VERSION ""

NS_ :

BS_:

BU_: Turbocharger OnBoardDataLogger OffBoardDiagnosticTool2 OffBoardDiagnosticTool1 FileServer ParkingBrakeController SeatControl2 FanDriveController SteeringColumnUnit CommunicationUnitRadio CommunicationUnitSatellite CommunicationUnitCellular PropulsionBatteryCharger ChassisController2 ChassisController1 EngineValveControl AuxiliaryHeater2 AuxiliaryHeater1 ClutchUnit RampControl InformationSystem1 SuspensionSystemController2 OilSensor VehicleDynamicStability ExhaustEmissionController TransmissionDisplay2 TransmissionDisplay1 ClimateControl2 WaterPumpController RearAxleSteeringController LightingOperatorControl SeatController1 IgnitionController2 IgnitionController1 TirePressureController CabController2 CabController1 PneumaticSystemController SuspensionSystemController1 HydraulicPumpController EnduranceBrakingSystem RetarderExhaustEngine2 OnBoardDiagnosticUnit HeadwayController RetarderExhaustEngine1 CabDisplay1 ManagementComputer VirtualTerminal OffVehicleGateway PowerTakeOffFront HitchControl AuxiliaryValveControl BodyController TractorTrailerBridge1 StarterSystem ElectricalSystem VehicleSecurity VehicleNavigation AerodynamicControl ElectricalChargingSystem ClimateControl1 TripRecorder InstrumentCluster SuspensionDriveAxle2 SuspensionDriveAxle1 SuspensionSteerAxle SteeringController FuelSystem CruiseControl RetarderDriveline RetarderEngine BrakesDriveAxle2 BrakesDriveAxle1 BrakesSystemController BrakesSteerAxle AxleDrive2 AxleDrive1 AxleSteering PowerTakeOff ShiftConsoleSecondary ShiftConsolePrimary Transmission2 Transmission1 Engine2 Engine1

BO_ 2628452094 FSClient: 9 Vector__XXX
 SG_ FSClientCommand M : 0|8@1+ (1,0) [0|255] "" Vector__XXX
 SG_ CM_VersionNumber m0 : 8|8@1+ (1,0) [0|255] "" Vector__XXX
 SG_ VS_ReportVolumeUsedByClient m2 : 8|1@1+ (1,0) [0|1] "" Vector__XXX
 SG_ VI_TAN m64 : 8|8@1+ (1,0) [0|255] "" Vector__XXX
 SG_ DF_TAN m49 : 8|8@1+ (1,0) [0|255] "" Vector__XXX
 SG_ MF_TAN m48 : 8|8@1+ (1,0) [0|255] "" Vector__XXX
 SG_ OF_TAN m32 : 8|8@1+ (1,0) [0|255] "" Vector__XXX
 SG_ SF_TAN m33 : 8|8@1+ (1,0) [0|255] "" Vector__XXX
 SG_ WF_TAN m35 : 8|8@1+ (1,0) [0|255] "" Vector__XXX
 SG_ CF_TAN m36 : 8|8@1+ (1,0) [0|255] "" Vector__XXX
 SG_ RF_TAN m34 : 8|8@1+ (1,0) [0|255] "" Vector__XXX
 SG_ GA_TAN m50 : 8|8@1+ (1,0) [0|255] "" Vector__XXX
 SG_ SA_TAN m51 : 8|8@1+ (1,0) [0|255] "" Vector__XXX
 SG_ FDT_TAN m52 : 8|8@1+ (1,0) [0|255] "" Vector__XXX
 SG_ GCD_TAN m16 : 8|8@1+ (1,0) [0|255] "" Vector__XXX
 SG_ CCD_TAN m17 : 8|8@1+ (1,0) [0|255] "" Vector__XXX
 SG_ VS_RequestVolumeToPrepareForRemo m2 : 9|1@1- (1,0) [0|1] "" Vector__XXX
 SG_ VS_VolumeName m2 : 16|16@1+ (1,0) [0|65535] "" Vector__XXX
 SG_ FDT_PathName m52 : 16|16@1+ (1,0) [0|65535] "" Vector__XXX
 SG_ GA_PathName m50 : 16|16@1+ (1,0) [0|65535] "" Vector__XXX
 SG_ DF_DeleteMode m49 : 16|1@1+ (1,0) [0|1] "" Vector__XXX
 SG_ MF_MoveModeCopy m48 : 16|1@1+ (1,0) [0|1] "" Vector__XXX
 SG_ CCD_PathName m17 : 16|16@1+ (1,0) [0|65535] "" Vector__XXX
 SG_ OF_FlagReadWrite m32 : 16|2@1+ (1,0) [0|3] "" Vector__XXX
 SG_ SF_Handle m33 : 16|8@1+ (1,0) [0|255] "" Vector__XXX
 SG_ RF_Handle m34 : 16|8@1+ (1,0) [0|255] "" Vector__XXX
 SG_ WF_Handle m35 : 16|8@1+ (1,0) [0|255] "" Vector__XXX
 SG_ CF_Handle m36 : 16|8@1+ (1,0) [0|255] "" Vector__XXX
 SG_ SET_ATTR_ReadOnly m51 : 16|2@1+ (1,0) [0|3] "" Vector__XXX
 SG_ VI_Flag_UsingSpaceSpecified m64 : 49|1@1+ (1,0) [0|1] "" Vector__XXX
 SG_ DF_DeleteModeForce m49 : 17|1@1+ (1,0) [0|1] "" Vector__XXX
 SG_ MF_MoveModeForce m48 : 17|1@1+ (1,0) [0|1] "" Vector__XXX
 SG_ DF_DeleteModeRecursive m49 : 18|1@1+ (1,0) [0|1] "" Vector__XXX
 SG_ MF_MoveModeRecursive m48 : 18|1@1+ (1,0) [0|1] "" Vector__XXX
 SG_ OF_FlagCreateNew m32 : 18|1@1+ (1,0) [0|1] "" Vector__XXX
 SG_ SET_ATTR_Hidden m51 : 18|2@1+ (1,0) [0|3] "" Vector__XXX
 SG_ OF_FlagAppend m32 : 19|1@1+ (1,0) [0|1] "" Vector__XXX
 SG_ OF_FlagExclusiveAccess m32 : 20|1@1+ (1,0) [0|1] "" Vector__XXX
 SG_ VI_Space m64 : 16|32@1+ (1,0) [0|4294967295] "" Vector__XXX
 SG_ SA_PathName m51 : 24|16@1+ (1,0) [0|65535] "" Vector__XXX
 SG_ DF_PathName m49 : 24|16@1+ (1,0) [0|65535] "" Vector__XXX
 SG_ WF_Count m35 : 24|16@1+ (1,0) [0|65535] "" Vector__XXX
 SG_ MF_SourcePathNameLength m48 : 24|16@1+ (1,0) [0|65535] "" Vector__XXX
 SG_ OF_PathName m32 : 24|16@1+ (1,0) [0|65535] "" Vector__XXX
 SG_ SF_PositionMode m33 : 24|8@1+ (1,0) [0|255] "" Vector__XXX
 SG_ RF_Count m34 : 24|16@1+ (1,0) [0|65535] "Bytes" Vector__XXX
 SG_ SF_Offset m33 : 32|32@1+ (1,0) [0|4294967295] "" Vector__XXX
 SG_ RF_ReportHiddenFiles m34 : 40|8@1+ (1,0) [0|255] "" Vector__XXX
 SG_ MF_DestinationPathNameLength m48 : 40|16@1+ (1,0) [0|65535] "" Vector__XXX
 SG_ VI_Flag_OverwriteExisting m64 : 48|1@1+ (1,0) [0|1] "" Vector__XXX
 SG_ VI_VolumeName m64 : 56|16@1+ (1,0) [0|65535] "" Vector__XXX

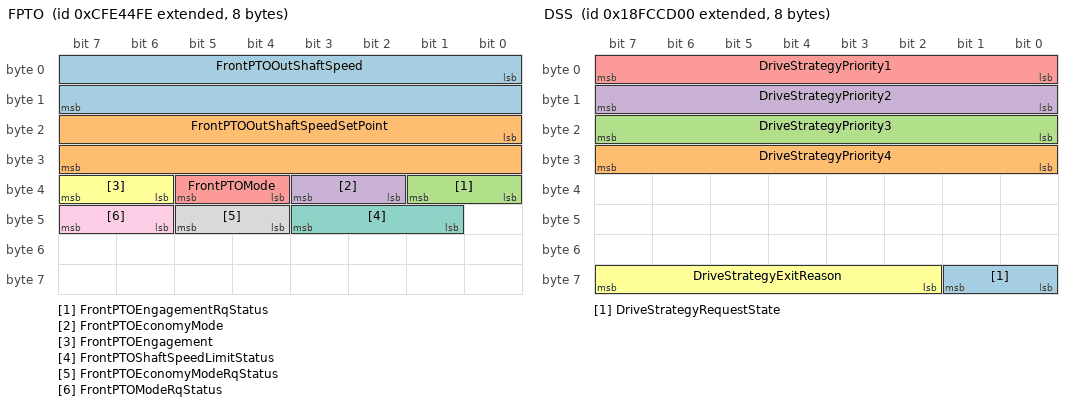
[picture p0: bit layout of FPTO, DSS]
BO_ 2365474046 FPTO: 8 Vector__XXX
 SG_ FrontPTOOutShaftSpeed : 0|16@1+ (0.125,0) [0|8031.88] "1/min" Vector__XXX
 SG_ FrontPTOOutShaftSpeedSetPoint : 16|16@1+ (0.125,0) [0|8031.88] "1/min" Vector__XXX
 SG_ FrontPTOEngagementRqStatus : 32|2@1+ (1,0) [0|3] "" Vector__XXX
 SG_ FrontPTOEconomyMode : 34|2@1+ (1,0) [0|3] "" Vector__XXX
 SG_ FrontPTOMode : 36|2@1+ (1,0) [0|3] "" Vector__XXX
 SG_ FrontPTOEngagement : 38|2@1+ (1,0) [0|3] "" Vector__XXX
 SG_ FrontPTOShaftSpeedLimitStatus : 41|3@1+ (1,0) [0|7] "" Vector__XXX
 SG_ FrontPTOEconomyModeRqStatus : 44|2@1+ (1,0) [0|3] "" Vector__XXX
 SG_ FrontPTOModeRqStatus : 46|2@1+ (1,0) [0|3] "" Vector__XXX

BO_ 2365474558 FHS: 8 Vector__XXX
 SG_ FrontHitchPosition : 0|8@1+ (0.4,0) [0|100] "%" Vector__XXX
 SG_ FrontHitchPositionLimitStatus : 11|3@1+ (1,0) [0|7] "" Vector__XXX
 SG_ FrontHitchInWorkIndication : 14|2@1+ (1,0) [0|3] "" Vector__XXX
 SG_ FrontNominalLowerLinkForce : 16|8@1+ (0.8,-100) [-100|100] "%" Vector__XXX
 SG_ FrontDraft : 24|16@1+ (10,-320000) [-320000|322550] "N" Vector__XXX

BO_ 2563243774 ETP_DT: 8 Vector__XXX
 SG_ SequenceNumber : 0|8@1+ (1,0) [0|255] "" Vector__XXX
 SG_ Byte1 : 8|8@1+ (1,0) [0|255] "" Vector__XXX
 SG_ Byte2 : 16|8@1+ (1,0) [0|255] "" Vector__XXX
 SG_ Byte3 : 24|8@1+ (1,0) [0|255] "" Vector__XXX
 SG_ Byte4 : 32|8@1+ (1,0) [0|255] "" Vector__XXX
 SG_ Byte5 : 40|8@1+ (1,0) [0|255] "" Vector__XXX
 SG_ Byte6 : 48|8@1+ (1,0) [0|255] "" Vector__XXX
 SG_ Byte7 : 56|8@1+ (1,0) [0|255] "" Vector__XXX

BO_ 2563309310 ETP_CM: 8 Vector__XXX
 SG_ ConnectionAbortReason m255 : 8|8@1+ (1,0) [0|255] "" Vector__XXX
 SG_ ControlByte M : 0|8@1+ (1,0) [0|255] "" Vector__XXX
 SG_ NumberOfBytesToTransfer m20 : 8|32@1+ (1,0) [1786|117440505] "" Vector__XXX
 SG_ NumberOfPacketsToSend m21 : 8|8@1+ (1,0) [1|255] "" Vector__XXX
 SG_ NumberOfPacketsOffset m22 : 8|8@1+ (1,0) [1|255] "" Vector__XXX
 SG_ NumberOfBytesTransfered m23 : 8|32@1+ (1,0) [1786|117440505] "" Vector__XXX
 SG_ NextPacketNumberToSend m21 : 16|24@1+ (1,0) [1|16777215] "" Vector__XXX
 SG_ DataPacketOffset m22 : 16|24@1+ (1,0) [0|16777215] "" Vector__XXX
 SG_ PGNumber : 40|24@1+ (1,0) [0|16777200] "" Vector__XXX

BO_ 2566704384 DSS: 8 Vector__XXX
 SG_ DriveStrategyRequestState : 56|2@1+ (1,0) [0|3] "" Vector__XXX
 SG_ DriveStrategyPriority4 : 24|8@1+ (1,0) [0|255] "" Vector__XXX
 SG_ DriveStrategyPriority3 : 16|8@1+ (1,0) [0|255] "" Vector__XXX
 SG_ DriveStrategyPriority2 : 8|8@1+ (1,0) [0|255] "" Vector__XXX
 SG_ DriveStrategyPriority1 : 0|8@1+ (1,0) [0|255] "" Vector__XXX
 SG_ DriveStrategyExitReason : 58|6@1+ (1,0) [0|63] "" Vector__XXX

BO_ 2365378048 DSC: 8 Vector__XXX
 SG_ RestoreOpDriveStratSetReq : 56|2@1+ (1,0) [0|3] "" Vector__XXX
 SG_ DriveStrategyPriority4Req : 24|8@1+ (1,0) [0|255] "" Vector__XXX
 SG_ DriveStrategyPriority3Req : 16|8@1+ (1,0) [0|255] "" Vector__XXX
 SG_ DriveStrategyPriority2Req : 8|8@1+ (1,0) [0|255] "" Vector__XXX
 SG_ DriveStrategyPriority1Req : 0|8@1+ (1,0) [0|255] "" Vector__XXX

BO_ 2566730494 DP: 8 Vector__XXX
 SG_ J1939_73 : 0|1@1+ (1,0) [0|1] "" Vector__XXX
 SG_ ISO14230 : 1|1@1+ (1,0) [0|1] "" Vector__XXX
 SG_ ISO15765_3 : 2|1@1+ (1,0) [0|1] "" Vector__XXX

BO_ 2314732286 COGSOGRapidUpdate: 8 Vector__XXX
 SG_ SID : 0|8@1+ (1,0) [0|252] "" Vector__XXX
 SG_ COGReference : 8|2@1+ (1,0) [0|3] "" Vector__XXX
 SG_ CourseOverGround : 16|16@1+ (0.0001,0) [0|6.28318] "rad" Vector__XXX
 SG_ SpeedOverGround : 32|16@1+ (0.01,0) [0|655.32] "m/s" Vector__XXX

BO_ 2566688510 CFF: 8 Vector__XXX
 SG_ NumberOfOptionsBytes : 32|8@1- (1,0) [0|255] "" Vector__XXX
 SG_ FunctionalityGeneration : 24|8@1- (1,0) [1|255] "" Vector__XXX
 SG_ Functionality : 16|8@1- (1,0) [0|255] "" Vector__XXX
 SG_ NumberOfFunctionalities : 8|8@1- (1,0) [1|255] "" Vector__XXX

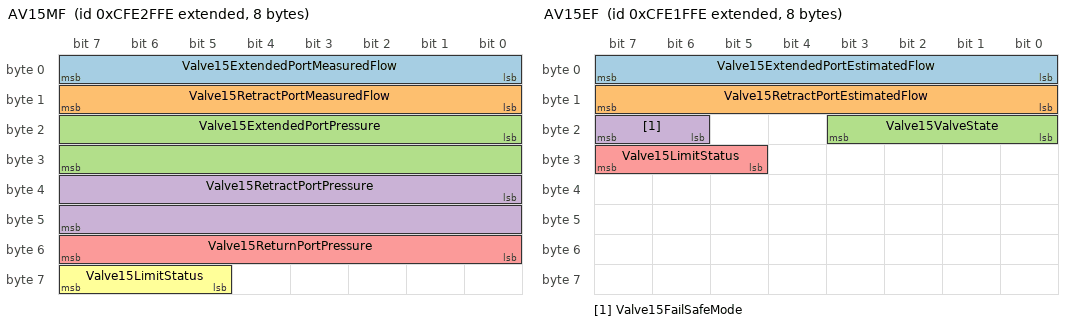
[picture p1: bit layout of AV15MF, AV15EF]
BO_ 2365468670 AV15MF: 8 Vector__XXX
 SG_ Valve15ExtendedPortMeasuredFlow : 0|8@1+ (1,-125) [-125|125] "%" Vector__XXX
 SG_ Valve15RetractPortMeasuredFlow : 8|8@1+ (1,-125) [-125|125] "%" Vector__XXX
 SG_ Valve15ExtendedPortPressure : 16|16@1+ (5,0) [0|321275] "kPa" Vector__XXX
 SG_ Valve15RetractPortPressure : 32|16@1+ (5,0) [0|321275] "kPa" Vector__XXX
 SG_ Valve15ReturnPortPressure : 48|8@1+ (16,0) [0|4000] "kPa" Vector__XXX
 SG_ Valve15LimitStatus : 61|3@1+ (1,0) [0|7] "" Vector__XXX

BO_ 2365464574 AV15EF: 8 Vector__XXX
 SG_ Valve15ExtendedPortEstimatedFlow : 0|8@1+ (1,-125) [-125|125] "%" Vector__XXX
 SG_ Valve15RetractPortEstimatedFlow : 8|8@1+ (1,-125) [-125|125] "%" Vector__XXX
 SG_ Valve15ValveState : 16|4@1+ (1,0) [0|15] "" Vector__XXX
 SG_ Valve15FailSafeMode : 22|2@1+ (1,0) [0|3] "" Vector__XXX
 SG_ Valve15LimitStatus : 29|3@1+ (1,0) [0|7] "" Vector__XXX

BO_ 2365472766 AV15C: 8 Vector__XXX
 SG_ Valve15PortFlowCmd : 0|8@1+ (0.4,0) [0|100] "%" Vector__XXX
 SG_ Valve15StateCmd : 16|4@1+ (1,0) [0|15] "" Vector__XXX
 SG_ Valve15FailSaveModeCmd : 22|2@1+ (1,0) [0|3] "" Vector__XXX

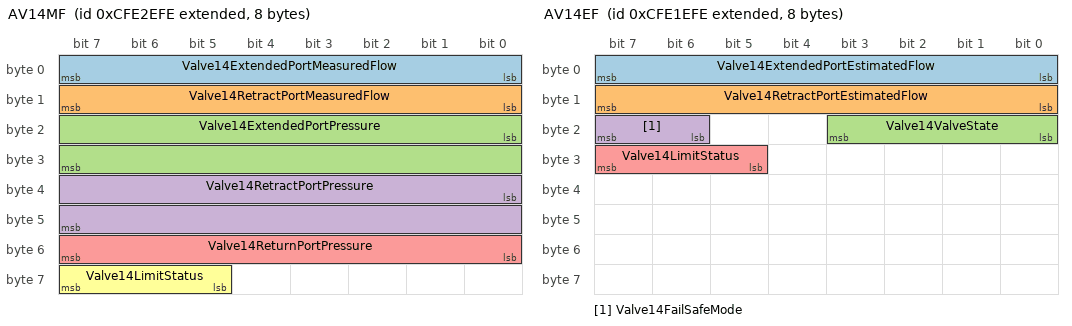
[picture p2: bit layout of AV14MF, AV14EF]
BO_ 2365468414 AV14MF: 8 Vector__XXX
 SG_ Valve14ExtendedPortMeasuredFlow : 0|8@1+ (1,-125) [-125|125] "%" Vector__XXX
 SG_ Valve14RetractPortMeasuredFlow : 8|8@1+ (1,-125) [-125|125] "%" Vector__XXX
 SG_ Valve14ExtendedPortPressure : 16|16@1+ (5,0) [0|321275] "kPa" Vector__XXX
 SG_ Valve14RetractPortPressure : 32|16@1+ (5,0) [0|321275] "kPa" Vector__XXX
 SG_ Valve14ReturnPortPressure : 48|8@1+ (16,0) [0|4000] "kPa" Vector__XXX
 SG_ Valve14LimitStatus : 61|3@1+ (1,0) [0|7] "" Vector__XXX

BO_ 2365464318 AV14EF: 8 Vector__XXX
 SG_ Valve14ExtendedPortEstimatedFlow : 0|8@1+ (1,-125) [-125|125] "%" Vector__XXX
 SG_ Valve14RetractPortEstimatedFlow : 8|8@1+ (1,-125) [-125|125] "%" Vector__XXX
 SG_ Valve14ValveState : 16|4@1+ (1,0) [0|15] "" Vector__XXX
 SG_ Valve14FailSafeMode : 22|2@1+ (1,0) [0|3] "" Vector__XXX
 SG_ Valve14LimitStatus : 29|3@1+ (1,0) [0|7] "" Vector__XXX

BO_ 2365472510 AV14C: 8 Vector__XXX
 SG_ Valve14PortFlowCmd : 0|8@1+ (0.4,0) [0|100] "%" Vector__XXX
 SG_ Valve14StateCmd : 16|4@1+ (1,0) [0|15] "" Vector__XXX
 SG_ Valve14FailSaveModeCmd : 22|2@1+ (1,0) [0|3] "" Vector__XXX

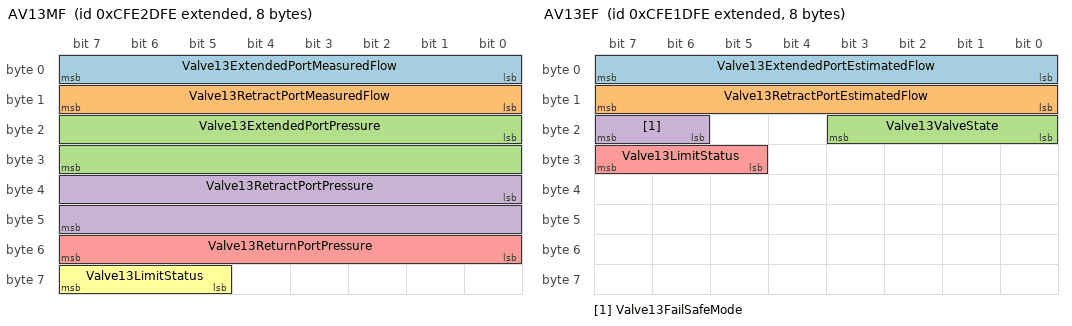
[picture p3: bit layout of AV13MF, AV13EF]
BO_ 2365468158 AV13MF: 8 Vector__XXX
 SG_ Valve13ExtendedPortMeasuredFlow : 0|8@1+ (1,-125) [-125|125] "%" Vector__XXX
 SG_ Valve13RetractPortMeasuredFlow : 8|8@1+ (1,-125) [-125|125] "%" Vector__XXX
 SG_ Valve13ExtendedPortPressure : 16|16@1+ (5,0) [0|321275] "kPa" Vector__XXX
 SG_ Valve13RetractPortPressure : 32|16@1+ (5,0) [0|321275] "kPa" Vector__XXX
 SG_ Valve13ReturnPortPressure : 48|8@1+ (16,0) [0|4000] "kPa" Vector__XXX
 SG_ Valve13LimitStatus : 61|3@1+ (1,0) [0|7] "" Vector__XXX

BO_ 2365464062 AV13EF: 8 Vector__XXX
 SG_ Valve13ExtendedPortEstimatedFlow : 0|8@1+ (1,-125) [-125|125] "%" Vector__XXX
 SG_ Valve13RetractPortEstimatedFlow : 8|8@1+ (1,-125) [-125|125] "%" Vector__XXX
 SG_ Valve13ValveState : 16|4@1+ (1,0) [0|15] "" Vector__XXX
 SG_ Valve13FailSafeMode : 22|2@1+ (1,0) [0|3] "" Vector__XXX
 SG_ Valve13LimitStatus : 29|3@1+ (1,0) [0|7] "" Vector__XXX

BO_ 2365472254 AV13C: 8 Vector__XXX
 SG_ Valve13PortFlowCmd : 0|8@1+ (0.4,0) [0|100] "%" Vector__XXX
 SG_ Valve13StateCmd : 16|4@1+ (1,0) [0|15] "" Vector__XXX
 SG_ Valve13FailSaveModeCmd : 22|2@1+ (1,0) [0|3] "" Vector__XXX

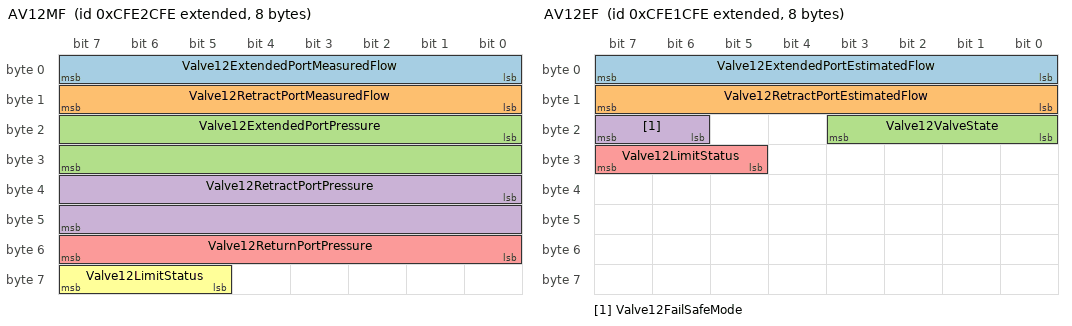
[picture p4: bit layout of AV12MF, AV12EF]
BO_ 2365467902 AV12MF: 8 Vector__XXX
 SG_ Valve12ExtendedPortMeasuredFlow : 0|8@1+ (1,-125) [-125|125] "%" Vector__XXX
 SG_ Valve12RetractPortMeasuredFlow : 8|8@1+ (1,-125) [-125|125] "%" Vector__XXX
 SG_ Valve12ExtendedPortPressure : 16|16@1+ (5,0) [0|321275] "kPa" Vector__XXX
 SG_ Valve12RetractPortPressure : 32|16@1+ (5,0) [0|321275] "kPa" Vector__XXX
 SG_ Valve12ReturnPortPressure : 48|8@1+ (16,0) [0|4000] "kPa" Vector__XXX
 SG_ Valve12LimitStatus : 61|3@1+ (1,0) [0|7] "" Vector__XXX

BO_ 2365463806 AV12EF: 8 Vector__XXX
 SG_ Valve12ExtendedPortEstimatedFlow : 0|8@1+ (1,-125) [-125|125] "%" Vector__XXX
 SG_ Valve12RetractPortEstimatedFlow : 8|8@1+ (1,-125) [-125|125] "%" Vector__XXX
 SG_ Valve12ValveState : 16|4@1+ (1,0) [0|15] "" Vector__XXX
 SG_ Valve12FailSafeMode : 22|2@1+ (1,0) [0|3] "" Vector__XXX
 SG_ Valve12LimitStatus : 29|3@1+ (1,0) [0|7] "" Vector__XXX

BO_ 2365471998 AV12C: 8 Vector__XXX
 SG_ Valve12PortFlowCmd : 0|8@1+ (0.4,0) [0|100] "%" Vector__XXX
 SG_ Valve12StateCmd : 16|4@1+ (1,0) [0|15] "" Vector__XXX
 SG_ Valve12FailSaveModeCmd : 22|2@1+ (1,0) [0|3] "" Vector__XXX

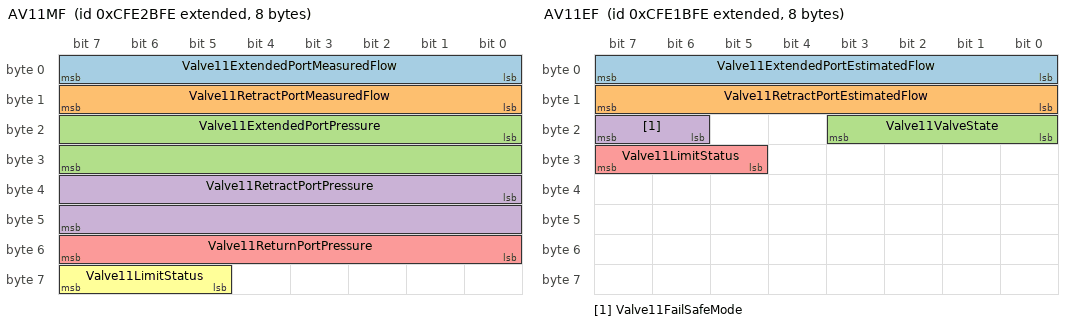
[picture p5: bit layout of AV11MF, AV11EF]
BO_ 2365467646 AV11MF: 8 Vector__XXX
 SG_ Valve11ExtendedPortMeasuredFlow : 0|8@1+ (1,-125) [-125|125] "%" Vector__XXX
 SG_ Valve11RetractPortMeasuredFlow : 8|8@1+ (1,-125) [-125|125] "%" Vector__XXX
 SG_ Valve11ExtendedPortPressure : 16|16@1+ (5,0) [0|321275] "kPa" Vector__XXX
 SG_ Valve11RetractPortPressure : 32|16@1+ (5,0) [0|321275] "kPa" Vector__XXX
 SG_ Valve11ReturnPortPressure : 48|8@1+ (16,0) [0|4000] "kPa" Vector__XXX
 SG_ Valve11LimitStatus : 61|3@1+ (1,0) [0|7] "" Vector__XXX

BO_ 2365463550 AV11EF: 8 Vector__XXX
 SG_ Valve11ExtendedPortEstimatedFlow : 0|8@1+ (1,-125) [-125|125] "%" Vector__XXX
 SG_ Valve11RetractPortEstimatedFlow : 8|8@1+ (1,-125) [-125|125] "%" Vector__XXX
 SG_ Valve11ValveState : 16|4@1+ (1,0) [0|15] "" Vector__XXX
 SG_ Valve11FailSafeMode : 22|2@1+ (1,0) [0|3] "" Vector__XXX
 SG_ Valve11LimitStatus : 29|3@1+ (1,0) [0|7] "" Vector__XXX

BO_ 2365471742 AV11C: 8 Vector__XXX
 SG_ Valve11PortFlowCmd : 0|8@1+ (0.4,0) [0|100] "%" Vector__XXX
 SG_ Valve11StateCmd : 16|4@1+ (1,0) [0|15] "" Vector__XXX
 SG_ Valve11FailSaveModeCmd : 22|2@1+ (1,0) [0|3] "" Vector__XXX

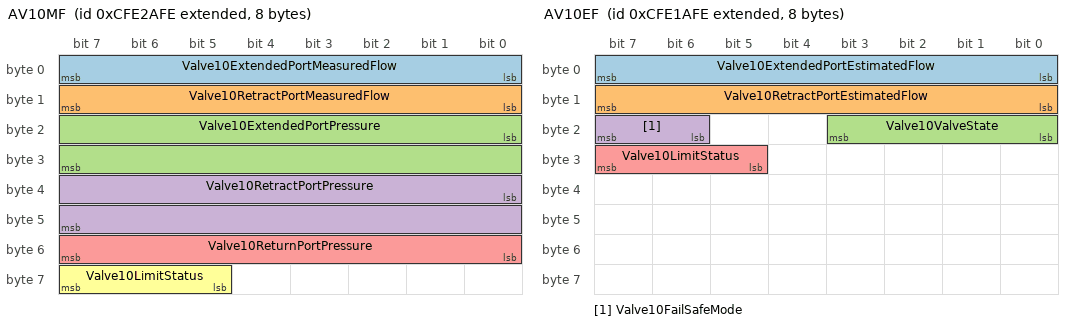
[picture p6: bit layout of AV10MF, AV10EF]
BO_ 2365467390 AV10MF: 8 Vector__XXX
 SG_ Valve10ExtendedPortMeasuredFlow : 0|8@1+ (1,-125) [-125|125] "%" Vector__XXX
 SG_ Valve10RetractPortMeasuredFlow : 8|8@1+ (1,-125) [-125|125] "%" Vector__XXX
 SG_ Valve10ExtendedPortPressure : 16|16@1+ (5,0) [0|321275] "kPa" Vector__XXX
 SG_ Valve10RetractPortPressure : 32|16@1+ (5,0) [0|321275] "kPa" Vector__XXX
 SG_ Valve10ReturnPortPressure : 48|8@1+ (16,0) [0|4000] "kPa" Vector__XXX
 SG_ Valve10LimitStatus : 61|3@1+ (1,0) [0|7] "" Vector__XXX

BO_ 2365463294 AV10EF: 8 Vector__XXX
 SG_ Valve10ExtendedPortEstimatedFlow : 0|8@1+ (1,-125) [-125|125] "%" Vector__XXX
 SG_ Valve10RetractPortEstimatedFlow : 8|8@1+ (1,-125) [-125|125] "%" Vector__XXX
 SG_ Valve10ValveState : 16|4@1+ (1,0) [0|15] "" Vector__XXX
 SG_ Valve10FailSafeMode : 22|2@1+ (1,0) [0|3] "" Vector__XXX
 SG_ Valve10LimitStatus : 29|3@1+ (1,0) [0|7] "" Vector__XXX

BO_ 2365471486 AV10C: 8 Vector__XXX
 SG_ Valve10PortFlowCmd : 0|8@1+ (0.4,0) [0|100] "%" Vector__XXX
 SG_ Valve10StateCmd : 16|4@1+ (1,0) [0|15] "" Vector__XXX
 SG_ Valve10FailSaveModeCmd : 22|2@1+ (1,0) [0|3] "" Vector__XXX

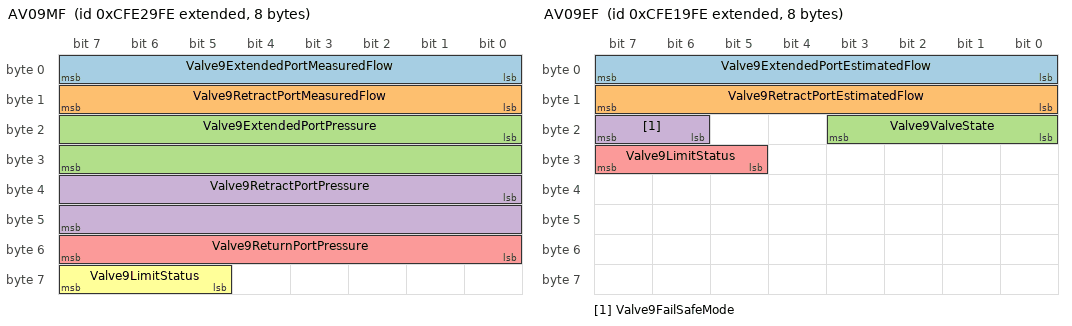
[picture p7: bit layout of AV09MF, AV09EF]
BO_ 2365467134 AV09MF: 8 Vector__XXX
 SG_ Valve9ExtendedPortMeasuredFlow : 0|8@1+ (1,-125) [-125|125] "%" Vector__XXX
 SG_ Valve9RetractPortMeasuredFlow : 8|8@1+ (1,-125) [-125|125] "%" Vector__XXX
 SG_ Valve9ExtendedPortPressure : 16|16@1+ (5,0) [0|321275] "kPa" Vector__XXX
 SG_ Valve9RetractPortPressure : 32|16@1+ (5,0) [0|321275] "kPa" Vector__XXX
 SG_ Valve9ReturnPortPressure : 48|8@1+ (16,0) [0|4000] "kPa" Vector__XXX
 SG_ Valve9LimitStatus : 61|3@1+ (1,0) [0|7] "" Vector__XXX

BO_ 2365463038 AV09EF: 8 Vector__XXX
 SG_ Valve9ExtendedPortEstimatedFlow : 0|8@1+ (1,-125) [-125|125] "%" Vector__XXX
 SG_ Valve9RetractPortEstimatedFlow : 8|8@1+ (1,-125) [-125|125] "%" Vector__XXX
 SG_ Valve9ValveState : 16|4@1+ (1,0) [0|15] "" Vector__XXX
 SG_ Valve9FailSafeMode : 22|2@1+ (1,0) [0|3] "" Vector__XXX
 SG_ Valve9LimitStatus : 29|3@1+ (1,0) [0|7] "" Vector__XXX

BO_ 2365471230 AV09C: 8 Vector__XXX
 SG_ Valve9PortFlowCmd : 0|8@1+ (0.4,0) [0|100] "%" Vector__XXX
 SG_ Valve9StateCmd : 16|4@1+ (1,0) [0|15] "" Vector__XXX
 SG_ Valve9FailSaveModeCmd : 22|2@1+ (1,0) [0|3] "" Vector__XXX

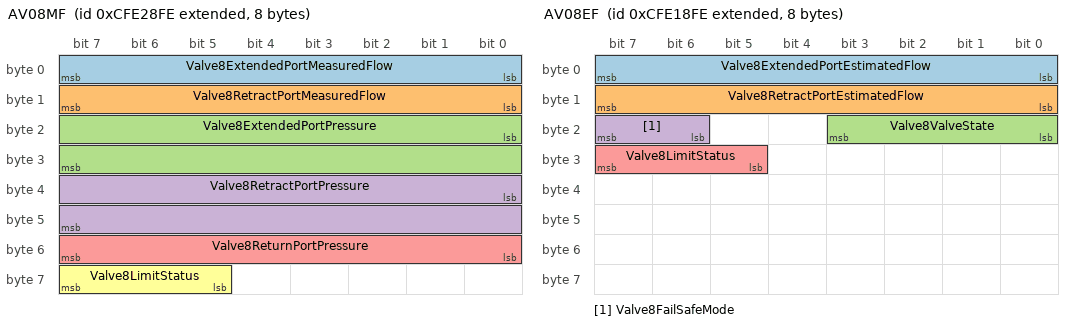
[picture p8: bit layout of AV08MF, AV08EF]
BO_ 2365466878 AV08MF: 8 Vector__XXX
 SG_ Valve8ExtendedPortMeasuredFlow : 0|8@1+ (1,-125) [-125|125] "%" Vector__XXX
 SG_ Valve8RetractPortMeasuredFlow : 8|8@1+ (1,-125) [-125|125] "%" Vector__XXX
 SG_ Valve8ExtendedPortPressure : 16|16@1+ (5,0) [0|321275] "kPa" Vector__XXX
 SG_ Valve8RetractPortPressure : 32|16@1+ (5,0) [0|321275] "kPa" Vector__XXX
 SG_ Valve8ReturnPortPressure : 48|8@1+ (16,0) [0|4000] "kPa" Vector__XXX
 SG_ Valve8LimitStatus : 61|3@1+ (1,0) [0|7] "" Vector__XXX

BO_ 2365462782 AV08EF: 8 Vector__XXX
 SG_ Valve8ExtendedPortEstimatedFlow : 0|8@1+ (1,-125) [-125|125] "%" Vector__XXX
 SG_ Valve8RetractPortEstimatedFlow : 8|8@1+ (1,-125) [-125|125] "%" Vector__XXX
 SG_ Valve8ValveState : 16|4@1+ (1,0) [0|15] "" Vector__XXX
 SG_ Valve8FailSafeMode : 22|2@1+ (1,0) [0|3] "" Vector__XXX
 SG_ Valve8LimitStatus : 29|3@1+ (1,0) [0|7] "" Vector__XXX

BO_ 2365470974 AV08C: 8 Vector__XXX
 SG_ Valve8PortFlowCmd : 0|8@1+ (0.4,0) [0|100] "%" Vector__XXX
 SG_ Valve8StateCmd : 16|4@1+ (1,0) [0|15] "" Vector__XXX
 SG_ Valve8FailSaveModeCmd : 22|2@1+ (1,0) [0|3] "" Vector__XXX

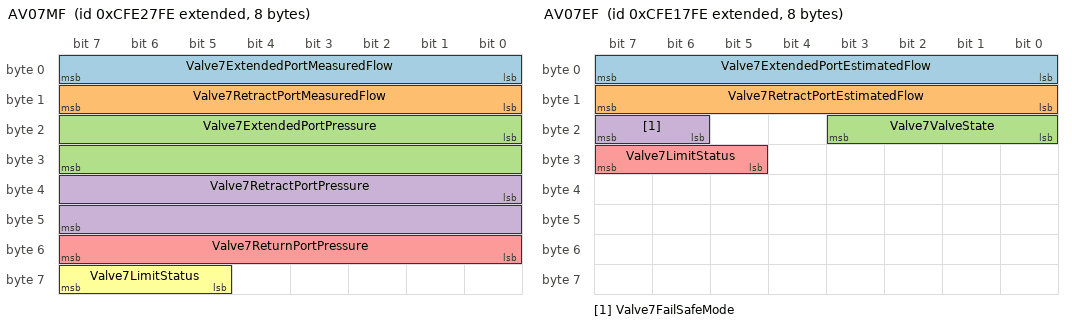
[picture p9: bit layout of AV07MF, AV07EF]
BO_ 2365466622 AV07MF: 8 Vector__XXX
 SG_ Valve7ExtendedPortMeasuredFlow : 0|8@1+ (1,-125) [-125|125] "%" Vector__XXX
 SG_ Valve7RetractPortMeasuredFlow : 8|8@1+ (1,-125) [-125|125] "%" Vector__XXX
 SG_ Valve7ExtendedPortPressure : 16|16@1+ (5,0) [0|321275] "kPa" Vector__XXX
 SG_ Valve7RetractPortPressure : 32|16@1+ (5,0) [0|321275] "kPa" Vector__XXX
 SG_ Valve7ReturnPortPressure : 48|8@1+ (16,0) [0|4000] "kPa" Vector__XXX
 SG_ Valve7LimitStatus : 61|3@1+ (1,0) [0|7] "" Vector__XXX

BO_ 2365462526 AV07EF: 8 Vector__XXX
 SG_ Valve7ExtendedPortEstimatedFlow : 0|8@1+ (1,-125) [-125|125] "%" Vector__XXX
 SG_ Valve7RetractPortEstimatedFlow : 8|8@1+ (1,-125) [-125|125] "%" Vector__XXX
 SG_ Valve7ValveState : 16|4@1+ (1,0) [0|15] "" Vector__XXX
 SG_ Valve7FailSafeMode : 22|2@1+ (1,0) [0|3] "" Vector__XXX
 SG_ Valve7LimitStatus : 29|3@1+ (1,0) [0|7] "" Vector__XXX

BO_ 2365470718 AV07C: 8 Vector__XXX
 SG_ Valve7PortFlowCmd : 0|8@1+ (0.4,0) [0|100] "%" Vector__XXX
 SG_ Valve7StateCmd : 16|4@1+ (1,0) [0|15] "" Vector__XXX
 SG_ Valve7FailSaveModeCmd : 22|2@1+ (1,0) [0|3] "" Vector__XXX

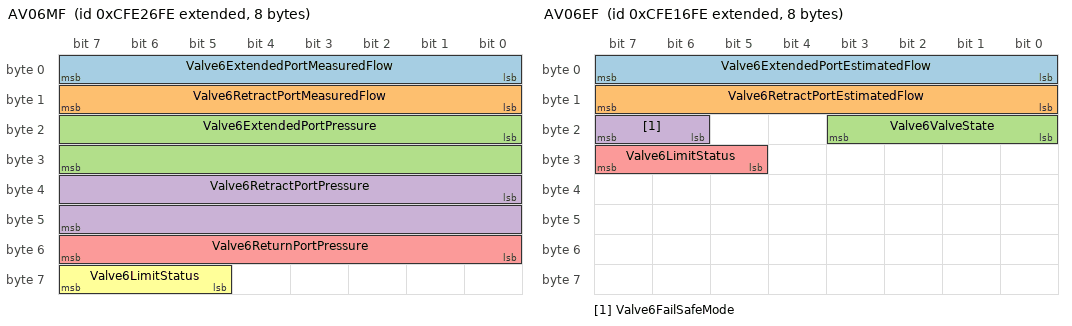
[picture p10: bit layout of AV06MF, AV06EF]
BO_ 2365466366 AV06MF: 8 Vector__XXX
 SG_ Valve6ExtendedPortMeasuredFlow : 0|8@1+ (1,-125) [-125|125] "%" Vector__XXX
 SG_ Valve6RetractPortMeasuredFlow : 8|8@1+ (1,-125) [-125|125] "%" Vector__XXX
 SG_ Valve6ExtendedPortPressure : 16|16@1+ (5,0) [0|321275] "kPa" Vector__XXX
 SG_ Valve6RetractPortPressure : 32|16@1+ (5,0) [0|321275] "kPa" Vector__XXX
 SG_ Valve6ReturnPortPressure : 48|8@1+ (16,0) [0|4000] "kPa" Vector__XXX
 SG_ Valve6LimitStatus : 61|3@1+ (1,0) [0|7] "" Vector__XXX

BO_ 2365462270 AV06EF: 8 Vector__XXX
 SG_ Valve6ExtendedPortEstimatedFlow : 0|8@1+ (1,-125) [-125|125] "%" Vector__XXX
 SG_ Valve6RetractPortEstimatedFlow : 8|8@1+ (1,-125) [-125|125] "%" Vector__XXX
 SG_ Valve6ValveState : 16|4@1+ (1,0) [0|15] "" Vector__XXX
 SG_ Valve6FailSafeMode : 22|2@1+ (1,0) [0|3] "" Vector__XXX
 SG_ Valve6LimitStatus : 29|3@1+ (1,0) [0|7] "" Vector__XXX

BO_ 2365470462 AV06C: 8 Vector__XXX
 SG_ Valve6PortFlowCmd : 0|8@1+ (0.4,0) [0|100] "%" Vector__XXX
 SG_ Valve6StateCmd : 16|4@1+ (1,0) [0|15] "" Vector__XXX
 SG_ Valve6FailSaveModeCmd : 22|2@1+ (1,0) [0|3] "" Vector__XXX

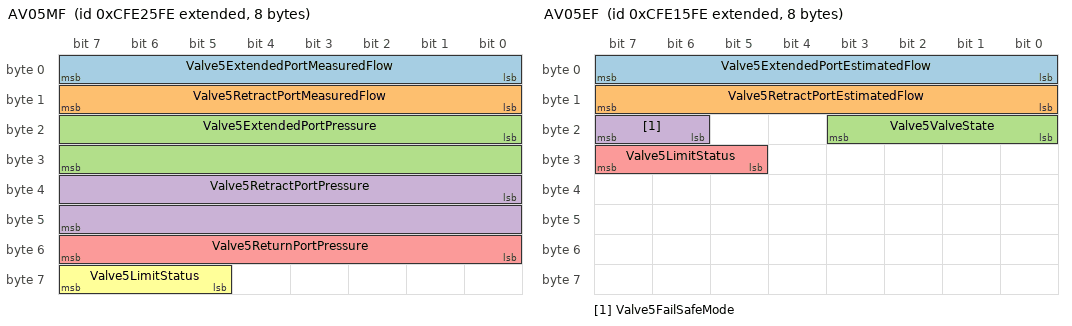
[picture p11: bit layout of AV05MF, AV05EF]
BO_ 2365466110 AV05MF: 8 Vector__XXX
 SG_ Valve5ExtendedPortMeasuredFlow : 0|8@1+ (1,-125) [-125|125] "%" Vector__XXX
 SG_ Valve5RetractPortMeasuredFlow : 8|8@1+ (1,-125) [-125|125] "%" Vector__XXX
 SG_ Valve5ExtendedPortPressure : 16|16@1+ (5,0) [0|321275] "kPa" Vector__XXX
 SG_ Valve5RetractPortPressure : 32|16@1+ (5,0) [0|321275] "kPa" Vector__XXX
 SG_ Valve5ReturnPortPressure : 48|8@1+ (16,0) [0|4000] "kPa" Vector__XXX
 SG_ Valve5LimitStatus : 61|3@1+ (1,0) [0|7] "" Vector__XXX

BO_ 2365462014 AV05EF: 8 Vector__XXX
 SG_ Valve5ExtendedPortEstimatedFlow : 0|8@1+ (1,-125) [-125|125] "%" Vector__XXX
 SG_ Valve5RetractPortEstimatedFlow : 8|8@1+ (1,-125) [-125|125] "%" Vector__XXX
 SG_ Valve5ValveState : 16|4@1+ (1,0) [0|15] "" Vector__XXX
 SG_ Valve5FailSafeMode : 22|2@1+ (1,0) [0|3] "" Vector__XXX
 SG_ Valve5LimitStatus : 29|3@1+ (1,0) [0|7] "" Vector__XXX

BO_ 2365470206 AV05C: 8 Vector__XXX
 SG_ Valve5PortFlowCmd : 0|8@1+ (0.4,0) [0|100] "%" Vector__XXX
 SG_ Valve5StateCmd : 16|4@1+ (1,0) [0|15] "" Vector__XXX
 SG_ Valve5FailSaveModeCmd : 22|2@1+ (1,0) [0|3] "" Vector__XXX

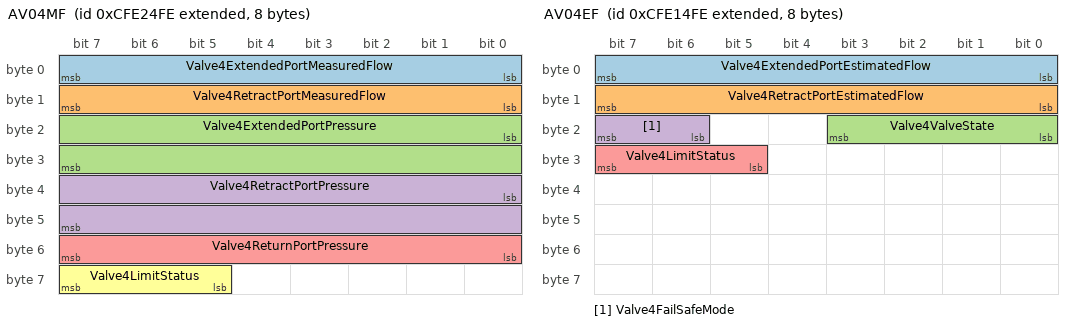
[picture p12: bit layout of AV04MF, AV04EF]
BO_ 2365465854 AV04MF: 8 Vector__XXX
 SG_ Valve4ExtendedPortMeasuredFlow : 0|8@1+ (1,-125) [-125|125] "%" Vector__XXX
 SG_ Valve4RetractPortMeasuredFlow : 8|8@1+ (1,-125) [-125|125] "%" Vector__XXX
 SG_ Valve4ExtendedPortPressure : 16|16@1+ (5,0) [0|321275] "kPa" Vector__XXX
 SG_ Valve4RetractPortPressure : 32|16@1+ (5,0) [0|321275] "kPa" Vector__XXX
 SG_ Valve4ReturnPortPressure : 48|8@1+ (16,0) [0|4000] "kPa" Vector__XXX
 SG_ Valve4LimitStatus : 61|3@1+ (1,0) [0|7] "" Vector__XXX

BO_ 2365461758 AV04EF: 8 Vector__XXX
 SG_ Valve4ExtendedPortEstimatedFlow : 0|8@1+ (1,-125) [-125|125] "%" Vector__XXX
 SG_ Valve4RetractPortEstimatedFlow : 8|8@1+ (1,-125) [-125|125] "%" Vector__XXX
 SG_ Valve4ValveState : 16|4@1+ (1,0) [0|15] "" Vector__XXX
 SG_ Valve4FailSafeMode : 22|2@1+ (1,0) [0|3] "" Vector__XXX
 SG_ Valve4LimitStatus : 29|3@1+ (1,0) [0|7] "" Vector__XXX

BO_ 2365469950 AV04C: 8 Vector__XXX
 SG_ Valve4PortFlowCmd : 0|8@1+ (0.4,0) [0|100] "%" Vector__XXX
 SG_ Valve4StateCmd : 16|4@1+ (1,0) [0|15] "" Vector__XXX
 SG_ Valve4FailSaveModeCmd : 22|2@1+ (1,0) [0|3] "" Vector__XXX

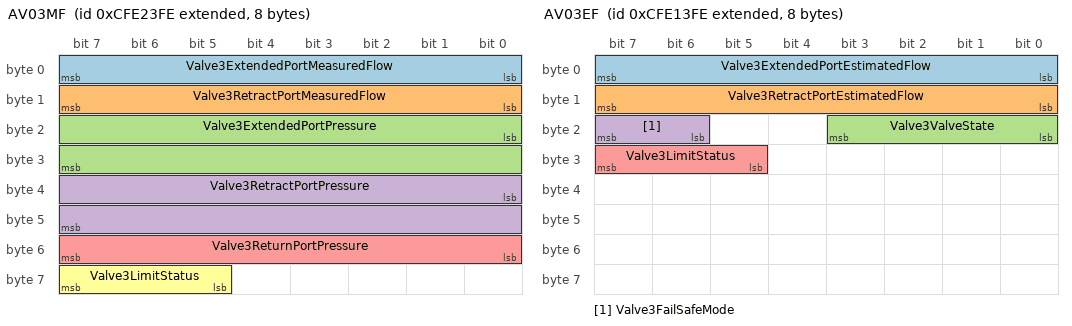
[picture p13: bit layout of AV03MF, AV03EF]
BO_ 2365465598 AV03MF: 8 Vector__XXX
 SG_ Valve3ExtendedPortMeasuredFlow : 0|8@1+ (1,-125) [-125|125] "%" Vector__XXX
 SG_ Valve3RetractPortMeasuredFlow : 8|8@1+ (1,-125) [-125|125] "%" Vector__XXX
 SG_ Valve3ExtendedPortPressure : 16|16@1+ (5,0) [0|321275] "kPa" Vector__XXX
 SG_ Valve3RetractPortPressure : 32|16@1+ (5,0) [0|321275] "kPa" Vector__XXX
 SG_ Valve3ReturnPortPressure : 48|8@1+ (16,0) [0|4000] "kPa" Vector__XXX
 SG_ Valve3LimitStatus : 61|3@1+ (1,0) [0|7] "" Vector__XXX

BO_ 2365461502 AV03EF: 8 Vector__XXX
 SG_ Valve3ExtendedPortEstimatedFlow : 0|8@1+ (1,-125) [-125|125] "%" Vector__XXX
 SG_ Valve3RetractPortEstimatedFlow : 8|8@1+ (1,-125) [-125|125] "%" Vector__XXX
 SG_ Valve3ValveState : 16|4@1+ (1,0) [0|15] "" Vector__XXX
 SG_ Valve3FailSafeMode : 22|2@1+ (1,0) [0|3] "" Vector__XXX
 SG_ Valve3LimitStatus : 29|3@1+ (1,0) [0|7] "" Vector__XXX

BO_ 2365469694 AV03C: 8 Vector__XXX
 SG_ Valve3PortFlowCmd : 0|8@1+ (0.4,0) [0|100] "%" Vector__XXX
 SG_ Valve3StateCmd : 16|4@1+ (1,0) [0|15] "" Vector__XXX
 SG_ Valve3FailSaveModeCmd : 22|2@1+ (1,0) [0|3] "" Vector__XXX

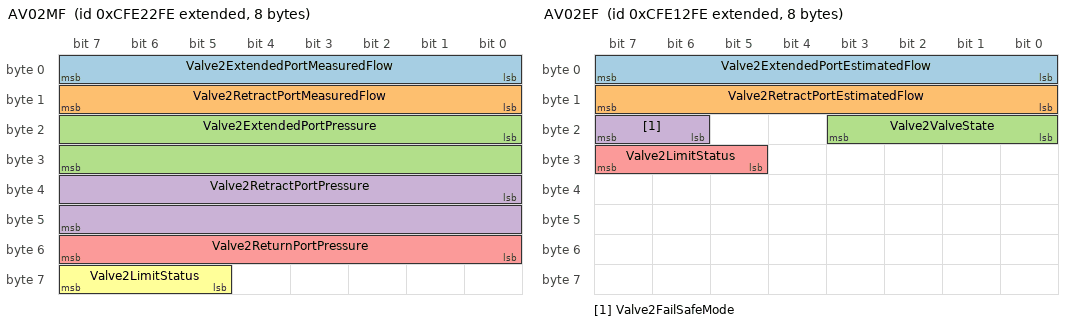
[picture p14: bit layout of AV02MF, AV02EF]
BO_ 2365465342 AV02MF: 8 Vector__XXX
 SG_ Valve2ExtendedPortMeasuredFlow : 0|8@1+ (1,-125) [-125|125] "%" Vector__XXX
 SG_ Valve2RetractPortMeasuredFlow : 8|8@1+ (1,-125) [-125|125] "%" Vector__XXX
 SG_ Valve2ExtendedPortPressure : 16|16@1+ (5,0) [0|321275] "kPa" Vector__XXX
 SG_ Valve2RetractPortPressure : 32|16@1+ (5,0) [0|321275] "kPa" Vector__XXX
 SG_ Valve2ReturnPortPressure : 48|8@1+ (16,0) [0|4000] "kPa" Vector__XXX
 SG_ Valve2LimitStatus : 61|3@1+ (1,0) [0|7] "" Vector__XXX

BO_ 2365461246 AV02EF: 8 Vector__XXX
 SG_ Valve2ExtendedPortEstimatedFlow : 0|8@1+ (1,-125) [-125|125] "%" Vector__XXX
 SG_ Valve2RetractPortEstimatedFlow : 8|8@1+ (1,-125) [-125|125] "%" Vector__XXX
 SG_ Valve2ValveState : 16|4@1+ (1,0) [0|15] "" Vector__XXX
 SG_ Valve2FailSafeMode : 22|2@1+ (1,0) [0|3] "" Vector__XXX
 SG_ Valve2LimitStatus : 29|3@1+ (1,0) [0|7] "" Vector__XXX

BO_ 2365469438 AV02C: 8 Vector__XXX
 SG_ Valve2PortFlowCmd : 0|8@1+ (0.4,0) [0|100] "%" Vector__XXX
 SG_ Valve2StateCmd : 16|4@1+ (1,0) [0|15] "" Vector__XXX
 SG_ Valve2FailSaveModeCmd : 22|2@1+ (1,0) [0|3] "" Vector__XXX

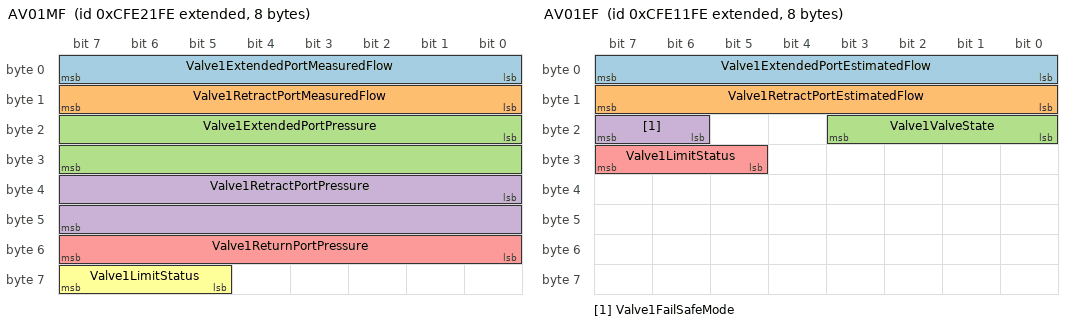
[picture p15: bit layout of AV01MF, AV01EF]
BO_ 2365465086 AV01MF: 8 Vector__XXX
 SG_ Valve1ExtendedPortMeasuredFlow : 0|8@1+ (1,-125) [-125|125] "%" Vector__XXX
 SG_ Valve1RetractPortMeasuredFlow : 8|8@1+ (1,-125) [-125|125] "%" Vector__XXX
 SG_ Valve1ExtendedPortPressure : 16|16@1+ (5,0) [0|321275] "kPa" Vector__XXX
 SG_ Valve1RetractPortPressure : 32|16@1+ (5,0) [0|321275] "kPa" Vector__XXX
 SG_ Valve1ReturnPortPressure : 48|8@1+ (16,0) [0|4000] "kPa" Vector__XXX
 SG_ Valve1LimitStatus : 61|3@1+ (1,0) [0|7] "" Vector__XXX

BO_ 2365460990 AV01EF: 8 Vector__XXX
 SG_ Valve1ExtendedPortEstimatedFlow : 0|8@1+ (1,-125) [-125|125] "%" Vector__XXX
 SG_ Valve1RetractPortEstimatedFlow : 8|8@1+ (1,-125) [-125|125] "%" Vector__XXX
 SG_ Valve1ValveState : 16|4@1+ (1,0) [0|15] "" Vector__XXX
 SG_ Valve1FailSafeMode : 22|2@1+ (1,0) [0|3] "" Vector__XXX
 SG_ Valve1LimitStatus : 29|3@1+ (1,0) [0|7] "" Vector__XXX

BO_ 2365469182 AV01C: 8 Vector__XXX
 SG_ Valve1PortFlowCmd : 0|8@1+ (0.4,0) [0|100] "%" Vector__XXX
 SG_ Valve1StateCmd : 16|4@1+ (1,0) [0|15] "" Vector__XXX
 SG_ Valve1FailSaveModeCmd : 22|2@1+ (1,0) [0|3] "" Vector__XXX

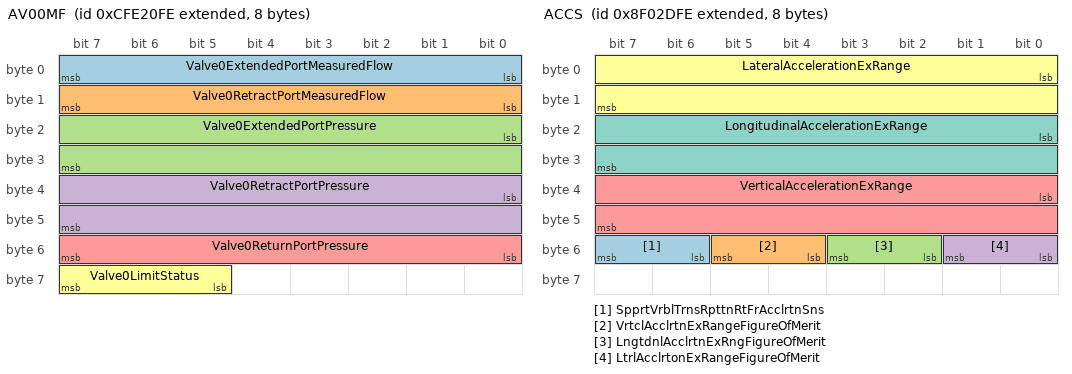
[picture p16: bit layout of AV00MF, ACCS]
BO_ 2365464830 AV00MF: 8 Vector__XXX
 SG_ Valve0ExtendedPortMeasuredFlow : 0|8@1+ (1,-125) [-125|125] "%" Vector__XXX
 SG_ Valve0RetractPortMeasuredFlow : 8|8@1+ (1,-125) [-125|125] "%" Vector__XXX
 SG_ Valve0ExtendedPortPressure : 16|16@1+ (5,0) [0|321275] "kPa" Vector__XXX
 SG_ Valve0RetractPortPressure : 32|16@1+ (5,0) [0|321275] "kPa" Vector__XXX
 SG_ Valve0ReturnPortPressure : 48|8@1+ (16,0) [0|4000] "kPa" Vector__XXX
 SG_ Valve0LimitStatus : 61|3@1+ (1,0) [0|7] "" Vector__XXX

BO_ 2365460734 AV00EF: 8 Vector__XXX
 SG_ Valve0ExtendedPortEstimatedFlow : 0|8@1+ (1,-125) [-125|125] "%" Vector__XXX
 SG_ Valve0RetractPortEstimatedFlow : 8|8@1+ (1,-125) [-125|125] "%" Vector__XXX
 SG_ Valve0ValveState : 16|4@1+ (1,0) [0|15] "" Vector__XXX
 SG_ Valve0FailSafeMode : 22|2@1+ (1,0) [0|3] "" Vector__XXX
 SG_ Valve0LimitStatus : 29|3@1+ (1,0) [0|7] "" Vector__XXX

BO_ 2365468926 AV00C: 8 Vector__XXX
 SG_ Valve0PortFlowCmd : 0|8@1+ (0.4,0) [0|100] "%" Vector__XXX
 SG_ Valve0StateCmd : 16|4@1+ (1,0) [0|15] "" Vector__XXX
 SG_ Valve0FailSaveModeCmd : 22|2@1+ (1,0) [0|3] "" Vector__XXX

BO_ 2365391360 AISO: 8 Vector__XXX
 SG_ StopAllImplementOperations : 56|2@1- (1,0) [0|3] "" Vector__XXX

BO_ 2297441790 ACCS: 8 Vector__XXX
 SG_ SpprtVrblTrnsRpttnRtFrAcclrtnSns : 54|2@1+ (1,0) [0|3] "" Vector__XXX
 SG_ VrtclAcclrtnExRangeFigureOfMerit : 52|2@1+ (1,0) [0|3] "" Vector__XXX
 SG_ LngtdnlAcclrtnExRngFigureOfMerit : 50|2@1+ (1,0) [0|3] "" Vector__XXX
 SG_ LtrlAcclrtonExRangeFigureOfMerit : 48|2@1+ (1,0) [0|3] "" Vector__XXX
 SG_ VerticalAccelerationExRange : 32|16@1+ (0.01,-320) [-320|322.55] "m/s²" Vector__XXX
 SG_ LateralAccelerationExRange : 0|16@1+ (0.01,-320) [-320|322.55] "m/s²" Vector__XXX
 SG_ LongitudinalAccelerationExRange : 16|16@1+ (0.01,-320) [-320|322.55] "m/s²" Vector__XXX

BO_ 2566712062 VEP4: 8 Vector__XXX
 SG_ HybridBatteryPackRemainingCharge : 0|16@1+ (0.0025,0) [0|160.6375] "%" Vector__XXX

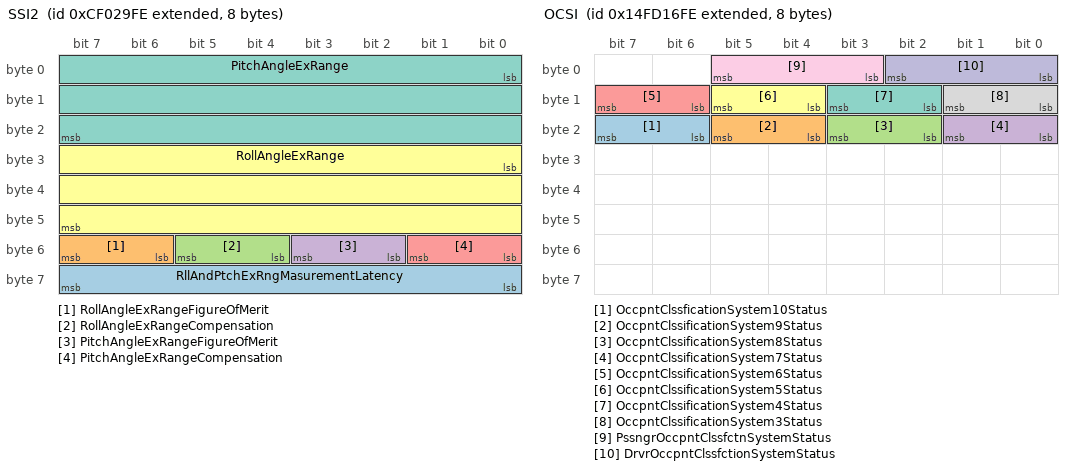
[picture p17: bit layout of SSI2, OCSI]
BO_ 2364549630 SSI2: 8 Vector__XXX
 SG_ RllAndPtchExRngMasurementLatency : 56|8@1+ (0.5,0) [0|125] "ms" Vector__XXX
 SG_ RollAngleExRangeFigureOfMerit : 54|2@1+ (1,0) [0|3] "" Vector__XXX
 SG_ RollAngleExRangeCompensation : 52|2@1+ (1,0) [0|3] "" Vector__XXX
 SG_ PitchAngleExRangeFigureOfMerit : 50|2@1+ (1,0) [0|3] "" Vector__XXX
 SG_ PitchAngleExRangeCompensation : 48|2@1+ (1,0) [0|3] "" Vector__XXX
 SG_ RollAngleExRange : 24|24@1+ (1,-250) [-250|250.9999] "deg" Vector__XXX
 SG_ PitchAngleExRange : 0|24@1+ (1,-250) [-250|250.9999] "deg" Vector__XXX

BO_ 2499614462 OCSI: 8 Vector__XXX
 SG_ OccpntClssficationSystem10Status : 22|2@1+ (1,0) [0|3] "" Vector__XXX
 SG_ OccpntClssificationSystem9Status : 20|2@1+ (1,0) [0|3] "" Vector__XXX
 SG_ OccpntClssificationSystem8Status : 18|2@1+ (1,0) [0|3] "" Vector__XXX
 SG_ OccpntClssificationSystem7Status : 16|2@1+ (1,0) [0|3] "" Vector__XXX
 SG_ OccpntClssificationSystem6Status : 14|2@1+ (1,0) [0|3] "" Vector__XXX
 SG_ OccpntClssificationSystem5Status : 12|2@1+ (1,0) [0|3] "" Vector__XXX
 SG_ OccpntClssificationSystem4Status : 10|2@1+ (1,0) [0|3] "" Vector__XXX
 SG_ OccpntClssificationSystem3Status : 8|2@1+ (1,0) [0|3] "" Vector__XXX
 SG_ PssngrOccpntClssfctnSystemStatus : 3|3@1+ (1,0) [0|7] "" Vector__XXX
 SG_ DrvrOccpntClssfctionSystemStatus : 0|3@1+ (1,0) [0|7] "" Vector__XXX

BO_ 2560098046 NCS: 8 Vector__XXX
 SG_ CabNoiseCtrlTuningStatus : 2|4@1+ (1,0) [0|15] "" Vector__XXX
 SG_ CabNoiseCtrlStatus : 0|2@1+ (1,0) [0|3] "" Vector__XXX

BO_ 2560163582 NC1: 8 Vector__XXX
 SG_ CabNoiseCtrlTuningState : 2|3@1+ (1,0) [0|7] "" Vector__XXX
 SG_ CabNoiseCtrlState : 0|2@1+ (1,0) [0|3] "" Vector__XXX

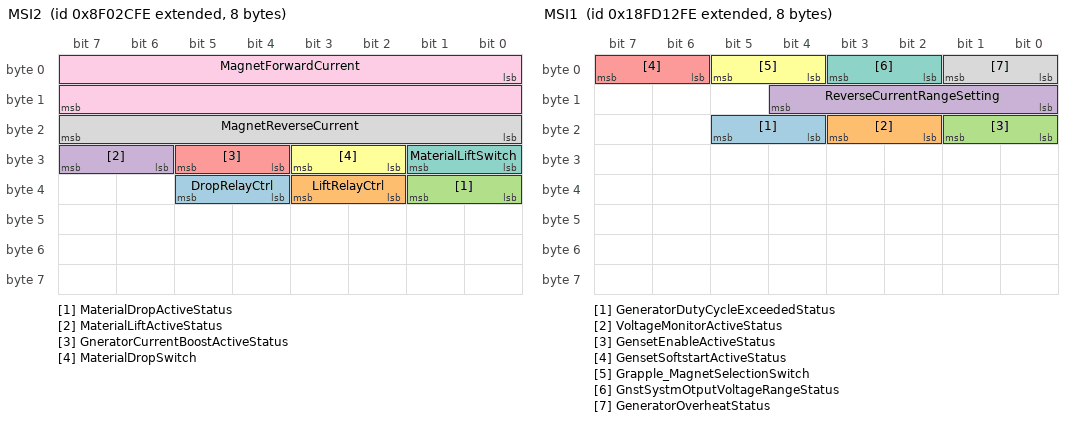
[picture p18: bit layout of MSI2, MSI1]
BO_ 2297441534 MSI2: 8 Vector__XXX
 SG_ DropRelayCtrl : 36|2@1+ (1,0) [0|3] "" Vector__XXX
 SG_ LiftRelayCtrl : 34|2@1+ (1,0) [0|3] "" Vector__XXX
 SG_ MaterialDropActiveStatus : 32|2@1+ (1,0) [0|3] "" Vector__XXX
 SG_ MaterialLiftActiveStatus : 30|2@1+ (1,0) [0|3] "" Vector__XXX
 SG_ GneratorCurrentBoostActiveStatus : 28|2@1+ (1,0) [0|3] "" Vector__XXX
 SG_ MaterialDropSwitch : 26|2@1+ (1,0) [0|3] "" Vector__XXX
 SG_ MaterialLiftSwitch : 24|2@1+ (1,0) [0|3] "" Vector__XXX
 SG_ MagnetReverseCurrent : 16|8@1+ (1,0) [0|250] "A" Vector__XXX
 SG_ MagnetForwardCurrent : 0|16@1+ (1,0) [0|64255] "Amps" Vector__XXX

BO_ 2566722302 MSI1: 8 Vector__XXX
 SG_ GeneratorDutyCycleExceededStatus : 20|2@1+ (1,0) [0|3] "" Vector__XXX
 SG_ VoltageMonitorActiveStatus : 18|2@1+ (1,0) [0|3] "" Vector__XXX
 SG_ GensetEnableActiveStatus : 16|2@1+ (1,0) [0|3] "" Vector__XXX
 SG_ ReverseCurrentRangeSetting : 8|5@1+ (1,0) [0|31] "" Vector__XXX
 SG_ GensetSoftstartActiveStatus : 6|2@1+ (1,0) [0|3] "" Vector__XXX
 SG_ Grapple_MagnetSelectionSwitch : 4|2@1+ (1,0) [0|3] "" Vector__XXX
 SG_ GnstSystmOtputVoltageRangeStatus : 2|2@1+ (1,0) [0|3] "" Vector__XXX
 SG_ GeneratorOverheatStatus : 0|2@1+ (1,0) [0|3] "" Vector__XXX

BO_ 2566722558 MSCI: 8 Vector__XXX
 SG_ MagnetRatedPower : 8|16@1+ (1,0) [0|32127.5] "kW" Vector__XXX
 SG_ MagnetBoostTime : 0|8@1+ (1,0) [0|62.5] "s" Vector__XXX

BO_ 2560032510 LVDSOM: 8 Vector__XXX
 SG_ LwVltgDscnnctDsiredOperatingMode : 0|4@1+ (1,0) [0|15] "" Vector__XXX

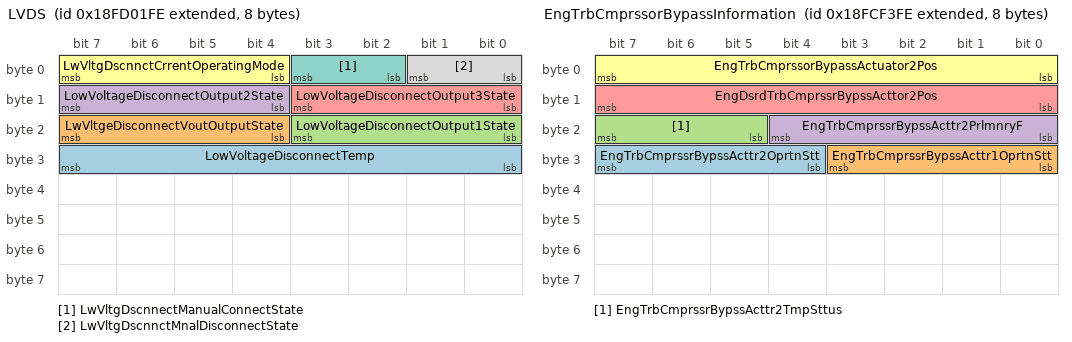
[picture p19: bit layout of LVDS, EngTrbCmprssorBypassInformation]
BO_ 2566717950 LVDS: 8 Vector__XXX
 SG_ LowVoltageDisconnectTemp : 24|8@1+ (1,-40) [-40|210] "deg C" Vector__XXX
 SG_ LwVltgeDisconnectVoutOutputState : 20|4@1+ (1,0) [0|15] "" Vector__XXX
 SG_ LowVoltageDisconnectOutput1State : 16|4@1+ (1,0) [0|15] "" Vector__XXX
 SG_ LowVoltageDisconnectOutput2State : 12|4@1+ (1,0) [0|15] "" Vector__XXX
 SG_ LowVoltageDisconnectOutput3State : 8|4@1+ (1,0) [0|15] "" Vector__XXX
 SG_ LwVltgDscnnctCrrentOperatingMode : 4|4@1+ (1,0) [0|15] "" Vector__XXX
 SG_ LwVltgDscnnectManualConnectState : 2|2@1+ (1,0) [0|3] "" Vector__XXX
 SG_ LwVltgDscnnctMnalDisconnectState : 0|2@1+ (1,0) [0|3] "" Vector__XXX

BO_ 2499604222 LLRE: 8 Vector__XXX
 SG_ BldReferenceElevationOffsetRight : 48|16@1+ (1,-32000) [-32000|32255] "mm" Vector__XXX
 SG_ BldeReferenceElevationOffsetLeft : 32|16@1+ (1,-32000) [-32000|32255] "mm" Vector__XXX
 SG_ BladeElevationDeviationRight : 16|16@1+ (1,-32000) [-32000|32255] "mm" Vector__XXX
 SG_ BladeElevationDeviationLeft : 0|16@1+ (1,-32000) [-32000|32255] "mm" Vector__XXX

BO_ 2358902526 JLCM: 8 Vector__XXX
 SG_ Joystick3Lamp10Cmd : 58|2@1+ (1,0) [0|3] "" Vector__XXX
 SG_ Joystick3Lamp9Cmd : 56|2@1+ (1,0) [0|3] "" Vector__XXX
 SG_ Joystick3Lamp8Cmd : 54|2@1+ (1,0) [0|3] "" Vector__XXX
 SG_ Joystick3Lamp7Cmd : 52|2@1+ (1,0) [0|3] "" Vector__XXX
 SG_ Joystick3Lamp6Cmd : 50|2@1+ (1,0) [0|3] "" Vector__XXX
 SG_ Joystick3Lamp5Cmd : 48|2@1+ (1,0) [0|3] "" Vector__XXX
 SG_ Joystick3Lamp4Cmd : 46|2@1+ (1,0) [0|3] "" Vector__XXX
 SG_ Joystick3Lamp3Cmd : 44|2@1+ (1,0) [0|3] "" Vector__XXX
 SG_ Joystick3Lamp2Cmd : 42|2@1+ (1,0) [0|3] "" Vector__XXX
 SG_ Joystick3Lamp1Cmd : 40|2@1+ (1,0) [0|3] "" Vector__XXX
 SG_ Joystick2Lamp10Cmd : 38|2@1+ (1,0) [0|3] "" Vector__XXX
 SG_ Joystick2Lamp9Cmd : 36|2@1+ (1,0) [0|3] "" Vector__XXX
 SG_ Joystick2Lamp8Cmd : 34|2@1+ (1,0) [0|3] "" Vector__XXX
 SG_ Joystick2Lamp7Cmd : 32|2@1+ (1,0) [0|3] "" Vector__XXX
 SG_ Joystick2Lamp6Cmd : 30|2@1+ (1,0) [0|3] "" Vector__XXX
 SG_ Joystick2Lamp5Cmd : 28|2@1+ (1,0) [0|3] "" Vector__XXX
 SG_ Joystick2Lamp4Cmd : 26|2@1+ (1,0) [0|3] "" Vector__XXX
 SG_ Joystick2Lamp3Cmd : 24|2@1+ (1,0) [0|3] "" Vector__XXX
 SG_ Joystick2Lamp2Cmd : 22|2@1+ (1,0) [0|3] "" Vector__XXX
 SG_ Joystick2Lamp1Cmd : 20|2@1+ (1,0) [0|3] "" Vector__XXX
 SG_ Joystick1Lamp10Cmd : 18|2@1+ (1,0) [0|3] "" Vector__XXX
 SG_ Joystick1Lamp9Cmd : 16|2@1+ (1,0) [0|3] "" Vector__XXX
 SG_ Joystick1Lamp8Cmd : 14|2@1+ (1,0) [0|3] "" Vector__XXX
 SG_ Joystick1Lamp7Cmd : 12|2@1+ (1,0) [0|3] "" Vector__XXX
 SG_ Joystick1Lamp6Cmd : 10|2@1+ (1,0) [0|3] "" Vector__XXX
 SG_ Joystick1Lamp5Cmd : 8|2@1+ (1,0) [0|3] "" Vector__XXX
 SG_ Joystick1Lamp4Cmd : 6|2@1+ (1,0) [0|3] "" Vector__XXX
 SG_ Joystick1Lamp3Cmd : 4|2@1+ (1,0) [0|3] "" Vector__XXX
 SG_ Joystick1Lamp2Cmd : 2|2@1+ (1,0) [0|3] "" Vector__XXX
 SG_ Joystick1Lamp1Cmd : 0|2@1+ (1,0) [0|3] "" Vector__XXX

BO_ 2566711550 IVAC: 8 Vector__XXX
 SG_ IntkVlvActtnSystmOlPrss2SlndCtrl : 2|2@1+ (1,0) [0|3] "" Vector__XXX
 SG_ IntkVlvActtnSystmOlPrss1SlndCtrl : 0|2@1+ (1,0) [0|3] "" Vector__XXX

BO_ 2633832958 ILI: 198 Vector__XXX
 SG_ SpecialIgnitorLoop90Resistance : 1584|16@1+ (0.1,0) [0|6425.5] "ohm" Vector__XXX
 SG_ SpecialIgnitorLoop89Resistance : 1568|16@1+ (0.1,0) [0|6425.5] "ohm" Vector__XXX
 SG_ SpecialIgnitorLoop88Resistance : 1552|16@1+ (0.1,0) [0|6425.5] "ohm" Vector__XXX
 SG_ SpecialIgnitorLoop87Resistance : 1536|16@1+ (0.1,0) [0|6425.5] "ohm" Vector__XXX
 SG_ SpecialIgnitorLoop86Resistance : 1520|16@1+ (0.1,0) [0|6425.5] "ohm" Vector__XXX
 SG_ SpecialIgnitorLoop85Resistance : 1504|16@1+ (0.1,0) [0|6425.5] "ohm" Vector__XXX
 SG_ SpecialIgnitorLoop84Resistance : 1488|16@1+ (0.1,0) [0|6425.5] "ohm" Vector__XXX
 SG_ SpecialIgnitorLoop83Resistance : 1472|16@1+ (0.1,0) [0|6425.5] "ohm" Vector__XXX
 SG_ SpecialIgnitorLoop82Resistance : 1456|16@1+ (0.1,0) [0|6425.5] "ohm" Vector__XXX
 SG_ SpecialIgnitorLoop81Resistance : 1440|16@1+ (0.1,0) [0|6425.5] "ohm" Vector__XXX
 SG_ SpecialIgnitorLoop80Resistance : 1424|16@1+ (0.1,0) [0|6425.5] "ohm" Vector__XXX
 SG_ SpecialIgnitorLoop79Resistance : 1408|16@1+ (0.1,0) [0|6425.5] "ohm" Vector__XXX
 SG_ SpecialIgnitorLoop78Resistance : 1392|16@1+ (0.1,0) [0|6425.5] "ohm" Vector__XXX
 SG_ SpecialIgnitorLoop77Resistance : 1376|16@1+ (0.1,0) [0|6425.5] "ohm" Vector__XXX
 SG_ SpecialIgnitorLoop76Resistance : 1360|16@1+ (0.1,0) [0|6425.5] "ohm" Vector__XXX
 SG_ SpecialIgnitorLoop75Resistance : 1344|16@1+ (0.1,0) [0|6425.5] "ohm" Vector__XXX
 SG_ SpecialIgnitorLoop74Resistance : 1328|16@1+ (0.1,0) [0|6425.5] "ohm" Vector__XXX
 SG_ SpecialIgnitorLoop73Resistance : 1312|16@1+ (0.1,0) [0|6425.5] "ohm" Vector__XXX
 SG_ SpecialIgnitorLoop72Resistance : 1296|16@1+ (0.1,0) [0|6425.5] "ohm" Vector__XXX
 SG_ SpecialIgnitorLoop71Resistance : 1280|16@1+ (0.1,0) [0|6425.5] "ohm" Vector__XXX
 SG_ SpecialIgnitorLoop70Resistance : 1264|16@1+ (0.1,0) [0|6425.5] "ohm" Vector__XXX
 SG_ SpecialIgnitorLoop69Resistance : 1248|16@1+ (0.1,0) [0|6425.5] "ohm" Vector__XXX
 SG_ SpecialIgnitorLoop68Resistance : 1232|16@1+ (0.1,0) [0|6425.5] "ohm" Vector__XXX
 SG_ SpecialIgnitorLoop67Resistance : 1216|16@1+ (0.1,0) [0|6425.5] "ohm" Vector__XXX
 SG_ SpecialIgnitorLoop66Resistance : 1200|16@1+ (0.1,0) [0|6425.5] "ohm" Vector__XXX
 SG_ SpecialIgnitorLoop65Resistance : 1184|16@1+ (0.1,0) [0|6425.5] "ohm" Vector__XXX
 SG_ SpecialIgnitorLoop64Resistance : 1168|16@1+ (0.1,0) [0|6425.5] "ohm" Vector__XXX
 SG_ SpecialIgnitorLoop63Resistance : 1152|16@1+ (0.1,0) [0|6425.5] "ohm" Vector__XXX
 SG_ SpecialIgnitorLoop61Resistance : 1120|16@1+ (0.1,0) [0|6425.5] "ohm" Vector__XXX
 SG_ SpecialIgnitorLoop60Resistance : 1104|16@1+ (0.1,0) [0|6425.5] "ohm" Vector__XXX
 SG_ SpecialIgnitorLoop59Resistance : 1088|16@1+ (0.1,0) [0|6425.5] "ohm" Vector__XXX
 SG_ SpecialIgnitorLoop58Resistance : 1072|16@1+ (0.1,0) [0|6425.5] "ohm" Vector__XXX
 SG_ SpecialIgnitorLoop57Resistance : 1056|16@1+ (0.1,0) [0|6425.5] "ohm" Vector__XXX
 SG_ SpecialIgnitorLoop56Resistance : 1040|16@1+ (0.1,0) [0|6425.5] "ohm" Vector__XXX
 SG_ SpecialIgnitorLoop55Resistance : 1024|16@1+ (0.1,0) [0|6425.5] "ohm" Vector__XXX
 SG_ SpecialIgnitorLoop54Resistance : 1008|16@1+ (0.1,0) [0|6425.5] "ohm" Vector__XXX
 SG_ SpecialIgnitorLoop53Resistance : 992|16@1+ (0.1,0) [0|6425.5] "ohm" Vector__XXX
 SG_ SpecialIgnitorLoop52Resistance : 976|16@1+ (0.1,0) [0|6425.5] "ohm" Vector__XXX
 SG_ SpecialIgnitorLoop51Resistance : 960|16@1+ (0.1,0) [0|6425.5] "ohm" Vector__XXX
 SG_ SpecialIgnitorLoop50Resistance : 944|16@1+ (0.1,0) [0|6425.5] "ohm" Vector__XXX
 SG_ SpecialIgnitorLoop49Resistance : 928|16@1+ (0.1,0) [0|6425.5] "ohm" Vector__XXX
 SG_ SpecialIgnitorLoop48Resistance : 912|16@1+ (0.1,0) [0|6425.5] "ohm" Vector__XXX
 SG_ SpecialIgnitorLoop47Resistance : 896|16@1+ (0.1,0) [0|6425.5] "ohm" Vector__XXX
 SG_ SpecialIgnitorLoop46Resistance : 880|16@1+ (0.1,0) [0|6425.5] "ohm" Vector__XXX
 SG_ SpecialIgnitorLoop45Resistance : 864|16@1+ (0.1,0) [0|6425.5] "ohm" Vector__XXX
 SG_ SpecialIgnitorLoop44Resistance : 848|16@1+ (0.1,0) [0|6425.5] "ohm" Vector__XXX
 SG_ SpecialIgnitorLoop43Resistance : 832|16@1+ (0.1,0) [0|6425.5] "ohm" Vector__XXX
 SG_ SpecialIgnitorLoop42Resistance : 816|16@1+ (0.1,0) [0|6425.5] "ohm" Vector__XXX
 SG_ SpecialIgnitorLoop41Resistance : 800|16@1+ (0.1,0) [0|6425.5] "ohm" Vector__XXX
 SG_ SpecialIgnitorLoop40Resistance : 784|16@1+ (0.1,0) [0|6425.5] "ohm" Vector__XXX
 SG_ SpecialIgnitorLoop39Resistance : 768|16@1+ (0.1,0) [0|6425.5] "ohm" Vector__XXX
 SG_ SpecialIgnitorLoop38Resistance : 752|16@1+ (0.1,0) [0|6425.5] "ohm" Vector__XXX
 SG_ SpecialIgnitorLoop37Resistance : 736|16@1+ (0.1,0) [0|6425.5] "ohm" Vector__XXX
 SG_ SpecialIgnitorLoop36Resistance : 720|16@1+ (0.1,0) [0|6425.5] "ohm" Vector__XXX
 SG_ SpecialIgnitorLoop35Resistance : 704|16@1+ (0.1,0) [0|6425.5] "ohm" Vector__XXX
 SG_ SpecialIgnitorLoop34Resistance : 688|16@1+ (0.1,0) [0|6425.5] "ohm" Vector__XXX
 SG_ SpecialIgnitorLoop33Resistance : 672|16@1+ (0.1,0) [0|6425.5] "ohm" Vector__XXX
 SG_ SpecialIgnitorLoop32Resistance : 656|16@1+ (0.1,0) [0|6425.5] "ohm" Vector__XXX
 SG_ SpecialIgnitorLoop31Resistance : 640|16@1+ (0.1,0) [0|6425.5] "ohm" Vector__XXX
 SG_ SpecialIgnitorLoop30Resistance : 624|16@1+ (0.1,0) [0|6425.5] "ohm" Vector__XXX
 SG_ SpecialIgnitorLoop29Resistance : 608|16@1+ (0.1,0) [0|6425.5] "ohm" Vector__XXX
 SG_ SpecialIgnitorLoop28Resistance : 592|16@1+ (0.1,0) [0|6425.5] "ohm" Vector__XXX
 SG_ SpecialIgnitorLoop27Resistance : 576|16@1+ (0.1,0) [0|6425.5] "ohm" Vector__XXX
 SG_ SpecialIgnitorLoop26Resistance : 560|16@1+ (0.1,0) [0|6425.5] "ohm" Vector__XXX
 SG_ SpecialIgnitorLoop25Resistance : 544|16@1+ (0.1,0) [0|6425.5] "ohm" Vector__XXX
 SG_ SpecialIgnitorLoop24Resistance : 528|16@1+ (0.1,0) [0|6425.5] "ohm" Vector__XXX
 SG_ SpecialIgnitorLoop23Resistance : 512|16@1+ (0.1,0) [0|6425.5] "ohm" Vector__XXX
 SG_ SpecialIgnitorLoop22Resistance : 496|16@1+ (0.1,0) [0|6425.5] "ohm" Vector__XXX
 SG_ SpecialIgnitorLoop21Resistance : 480|16@1+ (0.1,0) [0|6425.5] "ohm" Vector__XXX
 SG_ SpecialIgnitorLoop20Resistance : 464|16@1+ (0.1,0) [0|6425.5] "ohm" Vector__XXX
 SG_ SpecialIgnitorLoop19Resistance : 448|16@1+ (0.1,0) [0|6425.5] "ohm" Vector__XXX
 SG_ SpecialIgnitorLoop18Resistance : 432|16@1+ (0.1,0) [0|6425.5] "ohm" Vector__XXX
 SG_ SpecialIgnitorLoop17Resistance : 416|16@1+ (0.1,0) [0|6425.5] "ohm" Vector__XXX
 SG_ SpecialIgnitorLoop16Resistance : 400|16@1+ (0.1,0) [0|6425.5] "ohm" Vector__XXX
 SG_ SpecialIgnitorLoop15Resistance : 384|16@1+ (0.1,0) [0|6425.5] "ohm" Vector__XXX
 SG_ SpecialIgnitorLoop14Resistance : 368|16@1+ (0.1,0) [0|6425.5] "ohm" Vector__XXX
 SG_ SpecialIgnitorLoop13Resistance : 352|16@1+ (0.1,0) [0|6425.5] "ohm" Vector__XXX
 SG_ SpecialIgnitorLoop12Resistance : 336|16@1+ (0.1,0) [0|6425.5] "ohm" Vector__XXX
 SG_ SpecialIgnitorLoop11Resistance : 320|16@1+ (0.1,0) [0|6425.5] "ohm" Vector__XXX
 SG_ SpecialIgnitorLoop10Resistance : 304|16@1+ (0.1,0) [0|6425.5] "ohm" Vector__XXX
 SG_ SpecialIgnitorLoop9Resistance : 288|16@1+ (0.1,0) [0|6425.5] "ohm" Vector__XXX
 SG_ SpecialIgnitorLoop8Resistance : 272|16@1+ (0.1,0) [0|6425.5] "ohm" Vector__XXX
 SG_ SpecialIgnitorLoop7Resistance : 256|16@1+ (0.1,0) [0|6425.5] "ohm" Vector__XXX
 SG_ SpecialIgnitorLoop6Resistance : 240|16@1+ (0.1,0) [0|6425.5] "ohm" Vector__XXX
 SG_ SpecialIgnitorLoop5Resistance : 224|16@1+ (0.1,0) [0|6425.5] "ohm" Vector__XXX
 SG_ SpecialIgnitorLoop4Resistance : 208|16@1+ (0.1,0) [0|6425.5] "ohm" Vector__XXX
 SG_ SpecialIgnitorLoop3Resistance : 192|16@1+ (0.1,0) [0|6425.5] "ohm" Vector__XXX
 SG_ SpecialIgnitorLoop2Resistance : 176|16@1+ (0.1,0) [0|6425.5] "ohm" Vector__XXX
 SG_ SpecialIgnitorLoop1Resistance : 160|16@1+ (0.1,0) [0|6425.5] "ohm" Vector__XXX
 SG_ SdBagIgnitorLoop2RightResistance : 144|16@1+ (0.1,0) [0|6425.5] "ohm" Vector__XXX
 SG_ SdBagIgnitorLoop1RightResistance : 128|16@1+ (0.1,0) [0|6425.5] "ohm" Vector__XXX
 SG_ SdeBagIgnitorLoop2LeftResistance : 112|16@1+ (0.1,0) [0|6425.5] "ohm" Vector__XXX
 SG_ SdeBagIgnitorLoop1LeftResistance : 96|16@1+ (0.1,0) [0|6425.5] "ohm" Vector__XXX
 SG_ PssngrBltTnsnrIgntrLopResistance : 80|16@1+ (0.1,0) [0|6425.5] "ohm" Vector__XXX
 SG_ DrvrBltTnsnrIgntorLoopResistance : 64|16@1+ (0.1,0) [0|6425.5] "ohm" Vector__XXX
 SG_ PssngrArbgIgntrLp2ndStgRsistance : 48|16@1+ (0.1,0) [0|6425.5] "ohm" Vector__XXX
 SG_ DrvrArbgIgntrLp2ndStgeResistance : 32|16@1+ (0.1,0) [0|6425.5] "ohm" Vector__XXX
 SG_ PssngrArbgIgntrLp1stStgRsistance : 16|16@1+ (0.1,0) [0|6425.5] "ohm" Vector__XXX
 SG_ DrvrArbgIgntrLp1stStgeResistance : 0|16@1+ (0.1,0) [0|6425.5] "ohm" Vector__XXX

BO_ 2566719998 HRLFC: 8 Vector__XXX
 SG_ HighResolutionEngTotalFuelUsed : 32|32@1+ (0.001,0) [0|4211081.215] "L" Vector__XXX
 SG_ HighResolutionEngTripFuel : 0|32@1+ (0.001,0) [0|4211081.215] "L" Vector__XXX

BO_ 2565877502 EngTrboWastegateActuatorCtrlCmd: 8 Vector__XXX
 SG_ EngTurboWastegateActuator2Cmd : 16|16@1+ (1,0) [0|160.6375] "%" Vector__XXX
 SG_ EngTurboWastegateActuator1Cmd : 0|16@1+ (1,0) [0|160.6375] "%" Vector__XXX

BO_ 2566713854 EngTrbWstgteActuatorInformation: 8 Vector__XXX
 SG_ EngTrbWstgtActtr2OperationStatus : 12|4@1+ (1,0) [0|15] "" Vector__XXX
 SG_ EngTrbWstgtActtr1OperationStatus : 8|4@1+ (1,0) [0|15] "" Vector__XXX
 SG_ EngTrbWstgateActuator2TempStatus : 5|3@1+ (1,0) [0|7] "" Vector__XXX
 SG_ EngTrbWstgtActtor2PreliminaryFMI : 0|5@1+ (1,0) [0|31] "" Vector__XXX

BO_ 2566714366 EngTrbCmprssorBypassInformation: 8 Vector__XXX
 SG_ EngTrbCmprssrBypssActtr2OprtnStt : 28|4@1+ (1,0) [0|15] "" Vector__XXX
 SG_ EngTrbCmprssrBypssActtr1OprtnStt : 24|4@1+ (1,0) [0|15] "" Vector__XXX
 SG_ EngTrbCmprssrBypssActtr2TmpSttus : 21|3@1+ (1,0) [0|7] "" Vector__XXX
 SG_ EngTrbCmprssrBypssActtr2PrlmnryF : 16|5@1+ (1,0) [0|31] "" Vector__XXX
 SG_ EngDsrdTrbCmprssrBypssActtor2Pos : 8|8@1+ (1,0) [0|100] "%" Vector__XXX
 SG_ EngTrbCmprssorBypassActuator2Pos : 0|8@1+ (0.4,0) [0|100] "%" Vector__XXX

CM_ BO_ 2628452094 "File Client to Server";
CM_ SG_ 2628452094 FSClientCommand "File Server - Client Command";
CM_ SG_ 2628452094 VI_TAN "Transaction Number for Volume Initialization";
CM_ SG_ 2628452094 DF_TAN "Transaction Number for Delete File";
CM_ SG_ 2628452094 MF_TAN "Transaction Number for Move File";
CM_ SG_ 2628452094 OF_TAN "Transaction Number for Open File";
CM_ SG_ 2628452094 SF_TAN "Transaction Number for Seek File";
CM_ SG_ 2628452094 WF_TAN "Transaction Number for Write File";
CM_ SG_ 2628452094 CF_TAN "Transaction Number for Close File";
CM_ SG_ 2628452094 RF_TAN "Transaction Number for Rename File";
CM_ SG_ 2628452094 GA_TAN "Transaction Number for Get File Attributes";
CM_ SG_ 2628452094 SA_TAN "Transaction Number for Set File Attributes";
CM_ SG_ 2628452094 FDT_TAN "Transaction Number for Get File Data & Time";
CM_ SG_ 2628452094 GCD_TAN "Transaction Number for Get Current Directory";
CM_ SG_ 2628452094 CCD_TAN "Transaction Number for Change Current Directory";
CM_ SG_ 2628452094 FDT_PathName "Length of path name string for Get File Date and Time";
CM_ SG_ 2628452094 GA_PathName "Length of path name string for Get File Attributes";
CM_ SG_ 2628452094 DF_DeleteMode "Copy mode for Move File";
CM_ SG_ 2628452094 MF_MoveModeCopy "Copy mode for Move File";
CM_ SG_ 2628452094 CCD_PathName "Length of path name string for Change Current Directory";
CM_ SG_ 2628452094 OF_FlagReadWrite "Read/Write/Both/Directory Flag for Open File";
CM_ SG_ 2628452094 SF_Handle "Handle for Seek File";
CM_ SG_ 2628452094 RF_Handle "Handle for Read File";
CM_ SG_ 2628452094 WF_Handle "Handle for Write File";
CM_ SG_ 2628452094 CF_Handle "Handle for Close File";
CM_ SG_ 2628452094 SET_ATTR_ReadOnly "SetFile Attribute Read-Only";
CM_ SG_ 2628452094 VI_Flag_UsingSpaceSpecified "Create volume using space specified";
CM_ SG_ 2628452094 DF_DeleteModeForce "Force mode for Move File";
CM_ SG_ 2628452094 MF_MoveModeForce "Force mode for Move File";
CM_ SG_ 2628452094 DF_DeleteModeRecursive "Recursive mode for Move File";
CM_ SG_ 2628452094 MF_MoveModeRecursive "Recursive mode for Move File";
CM_ SG_ 2628452094 OF_FlagCreateNew "Create a new file if not yet existing";
CM_ SG_ 2628452094 SET_ATTR_Hidden "SetFile Attribute Hidden";
CM_ SG_ 2628452094 OF_FlagAppend "Open file for appending data to the end of the file";
CM_ SG_ 2628452094 OF_FlagExclusiveAccess "Open file with exclusive access (fails if already open)";
CM_ SG_ 2628452094 VI_Space "The space in units of 512";
CM_ SG_ 2628452094 SA_PathName "Length of path name string for Set File Attributes";
CM_ SG_ 2628452094 DF_PathName "Length of path name string for Delete File";
CM_ SG_ 2628452094 WF_Count "Number of written bytes";
CM_ SG_ 2628452094 MF_SourcePathNameLength "Length of source path name string for Move File";
CM_ SG_ 2628452094 OF_PathName "Length of path name string for Open File";
CM_ SG_ 2628452094 SF_PositionMode "Position Mode for Seek File";
CM_ SG_ 2628452094 RF_Count "Number of read bytes or number of read directory entries";
CM_ SG_ 2628452094 SF_Offset "Offset for Seek File";
CM_ SG_ 2628452094 RF_ReportHiddenFiles "Report Hidden Files";
CM_ SG_ 2628452094 MF_DestinationPathNameLength "Length of destination path name string for Move File";
CM_ SG_ 2628452094 VI_Flag_OverwriteExisting "Create a new volume if not yet existing (fails if existing volume)";
CM_ SG_ 2628452094 VI_VolumeName "Length of path name string for Initailize Volume Request";
CM_ BO_ 2365474046 "Secondary or Front Power Take off Output-Shaft";
CM_ SG_ 2365474046 FrontPTOEngagementRqStatus "Parameter used to report the tractor ECUs status associated with a parameter whose requests are transient.";
CM_ SG_ 2365474046 FrontPTOShaftSpeedLimitStatus "Parameter used to report the tractor ECUs present limit status associated with a parameter whose commands are persistent";
CM_ SG_ 2365474046 FrontPTOEconomyModeRqStatus "Parameter used to report the tractor ECUs status associated with a parameter whose requests are transient.";
CM_ SG_ 2365474046 FrontPTOModeRqStatus "Parameter used to report the tractor ECUs status associated with a parameter whose requests are transient.";
CM_ BO_ 2365474558 "Secondary or Front Hitch Status";
CM_ SG_ 2365474558 FrontHitchPositionLimitStatus "Parameter used to report the tractor ECUs present limit status associated with a parameter whose commands are persistent";
CM_ BO_ 2563243774 "Extended TP (Data)";
CM_ BO_ 2563309310 "Extended TP (Command)";
CM_ BO_ 2566704384 "Message sent from the tractor to the implement to indicate the current status, of the drive strategy priority 
structure, which indicates the priority of the multiple powertrain functions. ";
CM_ SG_ 2566704384 DriveStrategyRequestState "This  parmeter  reports  the  tractor's  state  associated  with  Drive  Strategy  requests  that  are 
transient/temporary/one-shot.";
CM_ SG_ 2566704384 DriveStrategyPriority4 "This parameter indicates the current Tractor drive strategy priority structure, which determines the balance 
between  fuel  economy/consumption  and  the  torque  reserve  of  the  engine.  This  parameter  indicates  the 
lowest priority. ";
CM_ SG_ 2566704384 DriveStrategyPriority3 "This parameter indicates the current Tractor drive strategy priority structure, which determines the balance 
between  fuel  economy/consumption  and  the  torque  reserve  of  the  engine.  This  parameter  indicates 
 the third to highest priority. ";
CM_ SG_ 2566704384 DriveStrategyPriority2 "This parameter indicates the current Tractor drive strategy priority structure, which determines the balance 
between  fuel  economy/consumption  and  the  torque  reserve  of  the  engine.  This  parameter  indicates 
 the second to highest priority. ";
CM_ SG_ 2566704384 DriveStrategyPriority1 "This parameter indicates the current Tractor drive strategy priority structure, which determines the balance 
between  fuel  economy/consumption  and  the  torque  reserve  of  the  engine.  This  parameter  indicates  the 
highest priority. ";
CM_ SG_ 2566704384 DriveStrategyExitReason "Parameter used to indicate why the drive strategy subsystem cannot currently accept remote commands or 
has most recently stopped accepting remote commands.";
CM_ SG_ 2365378048 RestoreOpDriveStratSetReq "This parameter requests the drive strategy subsystem to restore the settings for drive strategy to the state 
before automation was ended. ";
CM_ SG_ 2365378048 DriveStrategyPriority4Req "This parameter used to request an alteration to the tractor drive strategy priority structure, which determines 
the  balance  between  fuel  economy/consumption  and  the  torque  reserve  of  the  engine - the lowest priority request.  ";
CM_ SG_ 2365378048 DriveStrategyPriority3Req "This parameter used to request an alteration to the tractor drive strategy priority structure, which determines 
the  balance  between  fuel  economy/consumption  and  the  torque  reserve  of  the  engine - the third to highest priority request.";
CM_ SG_ 2365378048 DriveStrategyPriority2Req "This parameter used to request an alteration to the tractor drive strategy priority structure, which determines 
the  balance  between  fuel  economy/consumption  and  the  torque  reserve  of  the  engine - the second to highest priority request.";
CM_ SG_ 2365378048 DriveStrategyPriority1Req "This parameter used to request an alteration to the tractor drive strategy priority structure, which determines 
the  balance  between  fuel  economy/consumption  and  the  torque  reserve  of  the  engine - the highest priority request.";
CM_ BO_ 2566730494 "ECU diagnostic protocol";
CM_ SG_ 2566730494 J1939_73 "J1939-73";
CM_ SG_ 2566730494 ISO14230 "ISO 14230 (KWP 2000 over K line)";
CM_ SG_ 2566730494 ISO15765_3 "ISO 15765-3 (UDS on CAN)";
CM_ BO_ 2314732286 "This PGN is a single frame PGN that provides Course Over Ground(COG)and Speed Over Ground(SOG).

Being a single frame Msg,as opposed to other PGNs that include COG and SOG and are defined as multi-packet,this PGN lends itself to being transmitted more f";
CM_ SG_ 2314732286 SID "An upward counting number used to tie related information together between different PGNs.For example,SID would be used to tie together COG,SOG and RAIM values to a given Pos.255=no valid Pos fix to tie it to.Range 0 to 250 for valid Pos fixes.";
CM_ SG_ 2314732286 COGReference "0 = True, 
1 = Magnetic, 
2 = Error, 
3 = Null";
CM_ SG_ 2314732286 CourseOverGround "The direction of the path over ground actually followed by a vessel.";
CM_ BO_ 2566688510 "This message identifies all the functionalities, functionality generation and functionality options, supported by 
control functions.";
CM_ SG_ 2566688510 NumberOfOptionsBytes "This parameter reports the number of bytes that follow to report which options are supported by a functionality 
provided  by  a  control  function  connected  to  the  ISO  11783  network.";
CM_ SG_ 2566688510 FunctionalityGeneration "This parameter reports the generation of the functionality provided by a control function connected to the ISO 11783 network.";
CM_ SG_ 2566688510 Functionality "This parameter reports which functionalities are supported by a control function connected to the ISO 11783 
network. ";
CM_ BO_ 2365468670 "Auxiliary valve measured flow";
CM_ SG_ 2365468670 Valve15LimitStatus "Parameter used to report the tractor ECUs present limit status associated with a parameter whose commands are persistent";
CM_ BO_ 2365464574 "Esimated flow of auxiliary valve number 0 ";
CM_ SG_ 2365464574 Valve15LimitStatus "Parameter used to report the tractor ECUs present limit status associated with a parameter whose commands are persistent";
CM_ BO_ 2365472766 "Auxiliary Valve Command";
CM_ BO_ 2365468414 "Auxiliary valve measured flow";
CM_ SG_ 2365468414 Valve14LimitStatus "Parameter used to report the tractor ECUs present limit status associated with a parameter whose commands are persistent";
CM_ BO_ 2365464318 "Esimated flow of auxiliary valve number 0 ";
CM_ SG_ 2365464318 Valve14LimitStatus "Parameter used to report the tractor ECUs present limit status associated with a parameter whose commands are persistent";
CM_ BO_ 2365472510 "Auxiliary Valve Command";
CM_ BO_ 2365468158 "Auxiliary valve measured flow";
CM_ SG_ 2365468158 Valve13LimitStatus "Parameter used to report the tractor ECUs present limit status associated with a parameter whose commands are persistent";
CM_ BO_ 2365464062 "Esimated flow of auxiliary valve number 0 ";
CM_ SG_ 2365464062 Valve13LimitStatus "Parameter used to report the tractor ECUs present limit status associated with a parameter whose commands are persistent";
CM_ BO_ 2365472254 "Auxiliary Valve Command";
CM_ BO_ 2365467902 "Auxiliary valve measured flow";
CM_ SG_ 2365467902 Valve12LimitStatus "Parameter used to report the tractor ECUs present limit status associated with a parameter whose commands are persistent";
CM_ BO_ 2365463806 "Esimated flow of auxiliary valve number 0 ";
CM_ SG_ 2365463806 Valve12LimitStatus "Parameter used to report the tractor ECUs present limit status associated with a parameter whose commands are persistent";
CM_ BO_ 2365471998 "Auxiliary Valve Command";
CM_ BO_ 2365467646 "Auxiliary valve measured flow";
CM_ SG_ 2365467646 Valve11LimitStatus "Parameter used to report the tractor ECUs present limit status associated with a parameter whose commands are persistent";
CM_ BO_ 2365463550 "Esimated flow of auxiliary valve number 0 ";
CM_ SG_ 2365463550 Valve11LimitStatus "Parameter used to report the tractor ECUs present limit status associated with a parameter whose commands are persistent";
CM_ BO_ 2365471742 "Auxiliary Valve Command";
CM_ BO_ 2365467390 "Auxiliary valve measured flow";
CM_ SG_ 2365467390 Valve10LimitStatus "Parameter used to report the tractor ECUs present limit status associated with a parameter whose commands are persistent";
CM_ BO_ 2365463294 "Esimated flow of auxiliary valve number 0 ";
CM_ SG_ 2365463294 Valve10LimitStatus "Parameter used to report the tractor ECUs present limit status associated with a parameter whose commands are persistent";
CM_ BO_ 2365471486 "Auxiliary Valve Command";
CM_ BO_ 2365467134 "Auxiliary valve measured flow";
CM_ SG_ 2365467134 Valve9LimitStatus "Parameter used to report the tractor ECUs present limit status associated with a parameter whose commands are persistent";
CM_ BO_ 2365463038 "Esimated flow of auxiliary valve number 0 ";
CM_ SG_ 2365463038 Valve9LimitStatus "Parameter used to report the tractor ECUs present limit status associated with a parameter whose commands are persistent";
CM_ BO_ 2365471230 "Auxiliary Valve Command";
CM_ BO_ 2365466878 "Auxiliary valve measured flow";
CM_ SG_ 2365466878 Valve8LimitStatus "Parameter used to report the tractor ECUs present limit status associated with a parameter whose commands are persistent";
CM_ BO_ 2365462782 "Esimated flow of auxiliary valve number 0 ";
CM_ SG_ 2365462782 Valve8LimitStatus "Parameter used to report the tractor ECUs present limit status associated with a parameter whose commands are persistent";
CM_ BO_ 2365470974 "Auxiliary Valve Command";
CM_ BO_ 2365466622 "Auxiliary valve measured flow";
CM_ SG_ 2365466622 Valve7LimitStatus "Parameter used to report the tractor ECUs present limit status associated with a parameter whose commands are persistent";
CM_ BO_ 2365462526 "Esimated flow of auxiliary valve number 0 ";
CM_ SG_ 2365462526 Valve7LimitStatus "Parameter used to report the tractor ECUs present limit status associated with a parameter whose commands are persistent";
CM_ BO_ 2365470718 "Auxiliary Valve Command";
CM_ BO_ 2365466366 "Auxiliary valve measured flow";
CM_ SG_ 2365466366 Valve6LimitStatus "Parameter used to report the tractor ECUs present limit status associated with a parameter whose commands are persistent";
CM_ BO_ 2365462270 "Esimated flow of auxiliary valve number 0 ";
CM_ SG_ 2365462270 Valve6LimitStatus "Parameter used to report the tractor ECUs present limit status associated with a parameter whose commands are persistent";
CM_ BO_ 2365470462 "Auxiliary Valve Command";
CM_ BO_ 2365466110 "Auxiliary valve measured flow";
CM_ SG_ 2365466110 Valve5LimitStatus "Parameter used to report the tractor ECUs present limit status associated with a parameter whose commands are persistent";
CM_ BO_ 2365462014 "Esimated flow of auxiliary valve number 0 ";
CM_ SG_ 2365462014 Valve5LimitStatus "Parameter used to report the tractor ECUs present limit status associated with a parameter whose commands are persistent";
CM_ BO_ 2365470206 "Auxiliary Valve Command";
CM_ BO_ 2365465854 "Auxiliary valve measured flow";
CM_ SG_ 2365465854 Valve4LimitStatus "Parameter used to report the tractor ECUs present limit status associated with a parameter whose commands are persistent";
CM_ BO_ 2365461758 "Esimated flow of auxiliary valve number 0 ";
CM_ SG_ 2365461758 Valve4LimitStatus "Parameter used to report the tractor ECUs present limit status associated with a parameter whose commands are persistent";
CM_ BO_ 2365469950 "Auxiliary Valve Command";
CM_ BO_ 2365465598 "Auxiliary valve measured flow";
CM_ SG_ 2365465598 Valve3LimitStatus "Parameter used to report the tractor ECUs present limit status associated with a parameter whose commands are persistent";
CM_ BO_ 2365461502 "Esimated flow of auxiliary valve number 0 ";
CM_ SG_ 2365461502 Valve3LimitStatus "Parameter used to report the tractor ECUs present limit status associated with a parameter whose commands are persistent";
CM_ BO_ 2365469694 "Auxiliary Valve Command";
CM_ BO_ 2365465342 "Auxiliary valve measured flow";
CM_ SG_ 2365465342 Valve2LimitStatus "Parameter used to report the tractor ECUs present limit status associated with a parameter whose commands are persistent";
CM_ BO_ 2365461246 "Esimated flow of auxiliary valve number 0 ";
CM_ SG_ 2365461246 Valve2LimitStatus "Parameter used to report the tractor ECUs present limit status associated with a parameter whose commands are persistent";
CM_ BO_ 2365469438 "Auxiliary Valve Command";
CM_ BO_ 2365465086 "Auxiliary valve measured flow";
CM_ SG_ 2365465086 Valve1LimitStatus "Parameter used to report the tractor ECUs present limit status associated with a parameter whose commands are persistent";
CM_ BO_ 2365460990 "Esimated flow of auxiliary valve number 0 ";
CM_ SG_ 2365460990 Valve1LimitStatus "Parameter used to report the tractor ECUs present limit status associated with a parameter whose commands are persistent";
CM_ BO_ 2365469182 "Auxiliary Valve Command";
CM_ BO_ 2365464830 "Auxiliary valve measured flow";
CM_ SG_ 2365464830 Valve0LimitStatus "Parameter used to report the tractor ECUs present limit status associated with a parameter whose commands are persistent";
CM_ BO_ 2365460734 "Esimated flow of auxiliary valve number 0 ";
CM_ SG_ 2365460734 Valve0LimitStatus "Parameter used to report the tractor ECUs present limit status associated with a parameter whose commands are persistent";
CM_ BO_ 2365468926 "Auxiliary Valve Command";
CM_ BO_ 2365391360 " All implements stop operations switch state";
CM_ BO_ 2297441790 "The acceleration sensor message shall provide a measurement of the vehicle's acceleration in the lateral, longitudinal,
and vertical axes.";
CM_ SG_ 2297441790 SpprtVrblTrnsRpttnRtFrAcclrtnSns "Indicates which acceleration transmission rate are supported by the ECU in addition to the required 10 ms transmission";
CM_ SG_ 2297441790 VrtclAcclrtnExRangeFigureOfMerit "Figure of merit for vertical acceleration measurement.";
CM_ SG_ 2297441790 LngtdnlAcclrtnExRngFigureOfMerit "Figure of merit for longitudinal acceleration measurement.";
CM_ SG_ 2297441790 LtrlAcclrtonExRangeFigureOfMerit "Figure of merit for lateral acceleration measurement.";
CM_ SG_ 2297441790 VerticalAccelerationExRange "Indicates vertical acceleration of the vehicle and the effect of gravity. A positive vertical acceleration signal results when";
CM_ SG_ 2297441790 LateralAccelerationExRange "Indicates lateral acceleration of the vehicle. A positive lateral acceleration signal results when the vehicle is accelerated";
CM_ SG_ 2297441790 LongitudinalAccelerationExRange "Indicates longitudinal acceleration of the vehicle. A positive longitudinal acceleration signal results when the vehicle";
CM_ BO_ 2566712062 "Hybrid system voltage information.";
CM_ SG_ 2566712062 HybridBatteryPackRemainingCharge "Indicates the hybrid battery pack remaining charge. 0% means no charge remaining, 100% means full charge remaining.";
CM_ BO_ 2364549630 "The Slope Sensor Information 2 message shall provide a measurement of the vehicle's extended pitch angle and a";
CM_ SG_ 2364549630 RllAndPtchExRngMasurementLatency "Time between start of sensor processing and CAN transmission";
CM_ SG_ 2364549630 RollAngleExRangeFigureOfMerit "Figure of merit for roll angle measurement.";
CM_ SG_ 2364549630 RollAngleExRangeCompensation "Compensated mode for the roll measurement. Compensation is the use of multiple sensors together to enhance the";
CM_ SG_ 2364549630 PitchAngleExRangeFigureOfMerit "Figure of merit for pitch angle measurement.";
CM_ SG_ 2364549630 PitchAngleExRangeCompensation "Compensated mode for the pitch measurement. Compensation is the use of multiple sensors together to enhance the";
CM_ SG_ 2364549630 RollAngleExRange "The angle between the vehicle y-axis and the ground plane.";
CM_ SG_ 2364549630 PitchAngleExRange "The angle between the vehicle x-axis and the ground plane.";
CM_ BO_ 2499614462 "Message containing status of Occupant Classification System for driver, passenger and rear seating positions. The PGN";
CM_ SG_ 2499614462 OccpntClssficationSystem10Status "State of Occupant Classification System for seat position 10.";
CM_ SG_ 2499614462 OccpntClssificationSystem9Status "State of Occupant Classification System for seat position 9.";
CM_ SG_ 2499614462 OccpntClssificationSystem8Status "State of Occupant Classification System for seat position 8.";
CM_ SG_ 2499614462 OccpntClssificationSystem7Status "State of Occupant Classification System for seat position 7.";
CM_ SG_ 2499614462 OccpntClssificationSystem6Status "State of Occupant Classification System for seat position 6.";
CM_ SG_ 2499614462 OccpntClssificationSystem5Status "State of Occupant Classification System for seat position 5.";
CM_ SG_ 2499614462 OccpntClssificationSystem4Status "State of Occupant Classification System for seat position 4.";
CM_ SG_ 2499614462 OccpntClssificationSystem3Status "State of Occupant Classification System for seat position 3.";
CM_ SG_ 2499614462 PssngrOccpntClssfctnSystemStatus "State of Occupant Classification System for passenger.";
CM_ SG_ 2499614462 DrvrOccpntClssfctionSystemStatus "State of Occupant Classification System for driver.";
CM_ BO_ 2560098046 "Used to report the current state of the Noise Control System.";
CM_ SG_ 2560098046 CabNoiseCtrlTuningStatus "This parameter returns the current status of tuning function of the Cab Noise Control system. When the tuning state is";
CM_ SG_ 2560098046 CabNoiseCtrlStatus "This parameter returns the current status of the Cab Noise Control system.";
CM_ BO_ 2560163582 "Used to issue commands to the Noise Control System. This command PGN typically originates from either a Cab control";
CM_ SG_ 2560163582 CabNoiseCtrlTuningState "Command values for the Tuning State of the Cab Noise Control System. The Tuning State allows the Cab Noise Control";
CM_ SG_ 2560163582 CabNoiseCtrlState "Command signal to change the state of the Cab Noise Control System to on-line or off-line";
CM_ BO_ 2297441534 "Magnet Status Information 2";
CM_ SG_ 2297441534 DropRelayCtrl "Command signal used to Engage and Disengage the Drop Relay controlling a Steady-State Magnet.";
CM_ SG_ 2297441534 LiftRelayCtrl "Command signal used to Engage and Disengage the Lift Relay controlling a Steady-State Magnet.";
CM_ SG_ 2297441534 MaterialDropActiveStatus "The status of Material Drop Relay. When it is on, the generator generates reverse direction current so that the material";
CM_ SG_ 2297441534 MaterialLiftActiveStatus "The status of Material Lift Relay. When it is on, the generator generates forward direction current so that the material";
CM_ SG_ 2297441534 GneratorCurrentBoostActiveStatus "Status of generator current boost relay that can boost the generator output current for picking-up material operations.";
CM_ SG_ 2297441534 MaterialDropSwitch "This is a switch that can be used to enable the drop functionality of the Material Handler machine.";
CM_ SG_ 2297441534 MaterialLiftSwitch "This is a switch that can be used to enable the lift functionality of the Material Handler machine. When it is activated, the";
CM_ SG_ 2297441534 MagnetReverseCurrent "A reverse current being supplied to the electric magnet to reduce the forward current generated magnet field as quick as";
CM_ SG_ 2297441534 MagnetForwardCurrent "The forward current being supplied by the generator to the electric magnet to create a magnet field to lift material.";
CM_ BO_ 2566722302 "Magnet Status Information 1";
CM_ SG_ 2566722302 GeneratorDutyCycleExceededStatus "The status of the duty cycle of the generator usage, indicating if the generator has been on for too much time within a";
CM_ SG_ 2566722302 VoltageMonitorActiveStatus "Status of Voltage Monitor Relay. When it is activated, the Generator Voltage Monitor is connected to the generator output";
CM_ SG_ 2566722302 GensetEnableActiveStatus "Status of the Genset Enable Relay that enables or disables the Genset.";
CM_ SG_ 2566722302 ReverseCurrentRangeSetting "The operator setting for the Reverse Current. The setting defines the maximum reverse current. The actual current limits";
CM_ SG_ 2566722302 GensetSoftstartActiveStatus "The Genset Softstart Active Status refers to the status of the genset softstart relay. The moment the Genset System is";
CM_ SG_ 2566722302 Grapple_MagnetSelectionSwitch "This is a switch that can be used to select either the Grapple or Magnet function of the material handler machine.";
CM_ SG_ 2566722302 GnstSystmOtputVoltageRangeStatus "Status of generator voltage in or out of desired operating range.";
CM_ SG_ 2566722302 GeneratorOverheatStatus "The Status of Generator being Overheated.";
CM_ BO_ 2566722558 "This message carries data related to the configuration of the magnetic material handling system, possibly including the";
CM_ SG_ 2566722558 MagnetRatedPower "The rated power that the magnet can accept during material holding operations. Note that the magnet may experience";
CM_ SG_ 2566722558 MagnetBoostTime "The duration of time after the activation of the magnet circuit that a relatively high current is sent to the magnet for";
CM_ BO_ 2560032510 "Low Voltage Disconnect (LVD) Set Operating Mode is sent to the LVD to either manuallly override the normal LVD";
CM_ SG_ 2560032510 LwVltgDscnnctDsiredOperatingMode "Desired Operating Mode of the LVD. Used to issue a J1939 request to the LVD to change modes.";
CM_ BO_ 2566717950 "Status of the Low-Voltage Disconnect (LVD) device.";
CM_ SG_ 2566717950 LowVoltageDisconnectTemp "Internal temperature of the LVD.";
CM_ SG_ 2566717950 LwVltgeDisconnectVoutOutputState "State of the Vout Output from the LVD. Vout is the LVD's main internal, controllable, high-current output. If the LVD";
CM_ SG_ 2566717950 LowVoltageDisconnectOutput1State "State of the Output #1 from the LVD. Output #1 controls an external load or relay. This external load could be";
CM_ SG_ 2566717950 LowVoltageDisconnectOutput2State "State of the Output #2 from the LVD. Output #2 controls an external load or relay. This external load could be";
CM_ SG_ 2566717950 LowVoltageDisconnectOutput3State "State of the Output #3 from the LVD. Output #3 controls an external load or relay. This external load could be";
CM_ SG_ 2566717950 LwVltgDscnnctCrrentOperatingMode "Current operating mode of the LVD. The current mode is dependent on the state of the Manual Disconnect/Connect";
CM_ SG_ 2566717950 LwVltgDscnnectManualConnectState "State of the Manual Connect hardwired input to the LVD. Manual Connect is used to override the LVD's normal activlty";
CM_ SG_ 2566717950 LwVltgDscnnctMnalDisconnectState "State of the Manual Disconnect hardwired input to the LVD. Manual Disconnect is used to override the LVD's normal";
CM_ BO_ 2499604222 "This PGN will be used to communicate the reference elvation information for the land leveling system. It will";
CM_ SG_ 2499604222 BldReferenceElevationOffsetRight "Indicates the blade's right elevation offset with respect to the reference elevation. An offset of 0 m represents no offset";
CM_ SG_ 2499604222 BldeReferenceElevationOffsetLeft "Indicates the blade's left elevation offset with respect to the reference elevation. An offset of 0 m represents no offset";
CM_ SG_ 2499604222 BladeElevationDeviationRight "Indicate the blade's right elevation deviation with respect to the reference elevation. Serves as an indication of how far";
CM_ SG_ 2499604222 BladeElevationDeviationLeft "Indicate the blade's left elevation deviation with respect to the reference elevation. Serves as an indication of how far the";
CM_ BO_ 2358902526 "Used to transfer joystick lamp command informations which are used to switch on/off/blinking joystick 1...3 lamps 1...10.";
CM_ SG_ 2358902526 Joystick3Lamp10Cmd "Tells joystick 3 to switch on/off/blinking lamp 10.";
CM_ SG_ 2358902526 Joystick3Lamp9Cmd "Tells joystick 3 to switch on/off/blinking lamp 9.";
CM_ SG_ 2358902526 Joystick3Lamp8Cmd "Tells joystick 3 to switch on/off/blinking lamp 8.";
CM_ SG_ 2358902526 Joystick3Lamp7Cmd "Tells joystick 3 to switch on/off/blinking lamp 7.";
CM_ SG_ 2358902526 Joystick3Lamp6Cmd "Tells joystick 3 to switch on/off/blinking lamp 6.";
CM_ SG_ 2358902526 Joystick3Lamp5Cmd "Tells joystick 3 to switch on/off/blinking lamp 5.";
CM_ SG_ 2358902526 Joystick3Lamp4Cmd "Tells joystick 3 to switch on/off/blinking lamp 4.";
CM_ SG_ 2358902526 Joystick3Lamp3Cmd "Tells joystick 3 to switch on/off/blinking lamp 3.";
CM_ SG_ 2358902526 Joystick3Lamp2Cmd "Tells joystick 3 to switch on/off/blinking lamp 2.";
CM_ SG_ 2358902526 Joystick3Lamp1Cmd "Tells joystick 3 to switch on/off/blinking lamp 1.";
CM_ SG_ 2358902526 Joystick2Lamp10Cmd "Tells joystick 2 to switch on/off/blinking lamp 10.";
CM_ SG_ 2358902526 Joystick2Lamp9Cmd "Tells joystick 2 to switch on/off/blinking lamp 9.";
CM_ SG_ 2358902526 Joystick2Lamp8Cmd "Tells joystick 2 to switch on/off/blinking lamp 8.";
CM_ SG_ 2358902526 Joystick2Lamp7Cmd "Tells joystick 2 to switch on/off/blinking lamp 7.";
CM_ SG_ 2358902526 Joystick2Lamp6Cmd "Tells joystick 2 to switch on/off/blinking lamp 6.";
CM_ SG_ 2358902526 Joystick2Lamp5Cmd "Tells joystick 2 to switch on/off/blinking lamp 5.";
CM_ SG_ 2358902526 Joystick2Lamp4Cmd "Tells joystick 2 to switch on/off/blinking lamp 4.";
CM_ SG_ 2358902526 Joystick2Lamp3Cmd "Tells joystick 2 to switch on/off/blinking lamp 3.";
CM_ SG_ 2358902526 Joystick2Lamp2Cmd "Tells joystick 2 to switch on/off/blinking lamp 2.";
CM_ SG_ 2358902526 Joystick2Lamp1Cmd "Tells joystick 2 to switch on/off/blinking lamp 1.";
CM_ SG_ 2358902526 Joystick1Lamp10Cmd "Tells joystick 1 to switch on/off/blinking lamp 10.";
CM_ SG_ 2358902526 Joystick1Lamp9Cmd "Tells joystick 1 to switch on/off/blinking lamp 9.";
CM_ SG_ 2358902526 Joystick1Lamp8Cmd "Tells joystick 1 to switch on/off/blinking lamp 8.";
CM_ SG_ 2358902526 Joystick1Lamp7Cmd "Tells joystick 1 to switch on/off/blinking lamp 7.";
CM_ SG_ 2358902526 Joystick1Lamp6Cmd "Tells joystick 1 to switch on/off/blinking lamp 6.";
CM_ SG_ 2358902526 Joystick1Lamp5Cmd "Tells joystick 1 to switch on/off/blinking lamp 5.";
CM_ SG_ 2358902526 Joystick1Lamp4Cmd "Tells joystick 1 to switch on/off/blinking lamp 4.";
CM_ SG_ 2358902526 Joystick1Lamp3Cmd "Tells joystick 1 to switch on/off/blinking lamp 3.";
CM_ SG_ 2358902526 Joystick1Lamp2Cmd "Tells joystick 1 to switch on/off/blinking lamp 2.";
CM_ SG_ 2358902526 Joystick1Lamp1Cmd "Tells joystick 1 to switch on/off/blinking lamp 1.";
CM_ BO_ 2566711550 "Contains information about the intake valve actuation system control.";
CM_ SG_ 2566711550 IntkVlvActtnSystmOlPrss2SlndCtrl "Indicates the current command to the solenoid that controls the intake valve actuation system oil pressure 2 valve. This";
CM_ SG_ 2566711550 IntkVlvActtnSystmOlPrss1SlndCtrl "Indicates the current command to the solenoid that controls the intake valve actuation system oil pressure 1 valve. This";
CM_ BO_ 2633832958 "Message containing resistance values for every equipped ignitor loop of the restraint-system. (Maximum of 100 Ignitor";
CM_ SG_ 2633832958 SpecialIgnitorLoop90Resistance "Resistance of Special Ignitor Loop 90. Since there are many different vehicle types (e.g. truck, bus, firetruck or";
CM_ SG_ 2633832958 SpecialIgnitorLoop89Resistance "Resistance of Special Ignitor Loop 89. Since there are many different vehicle types (e.g. truck, bus, firetruck or";
CM_ SG_ 2633832958 SpecialIgnitorLoop88Resistance "Resistance of Special Ignitor Loop 88. Since there are many different vehicle types (e.g. truck, bus, firetruck or";
CM_ SG_ 2633832958 SpecialIgnitorLoop87Resistance "Resistance of Special Ignitor Loop 87. Since there are many different vehicle types (e.g. truck, bus, firetruck or";
CM_ SG_ 2633832958 SpecialIgnitorLoop86Resistance "Resistance of Special Ignitor Loop 86. Since there are many different vehicle types (e.g. truck, bus, firetruck or";
CM_ SG_ 2633832958 SpecialIgnitorLoop85Resistance "Resistance of Special Ignitor Loop 85. Since there are many different vehicle types (e.g. truck, bus, firetruck or";
CM_ SG_ 2633832958 SpecialIgnitorLoop84Resistance "Resistance of Special Ignitor Loop 84. Since there are many different vehicle types (e.g. truck, bus, firetruck or";
CM_ SG_ 2633832958 SpecialIgnitorLoop83Resistance "Resistance of Special Ignitor Loop 83. Since there are many different vehicle types (e.g. truck, bus, firetruck or";
CM_ SG_ 2633832958 SpecialIgnitorLoop82Resistance "Resistance of Special Ignitor Loop 82. Since there are many different vehicle types (e.g. truck, bus, firetruck or";
CM_ SG_ 2633832958 SpecialIgnitorLoop81Resistance "Resistance of Special Ignitor Loop 81. Since there are many different vehicle types (e.g. truck, bus, firetruck or";
CM_ SG_ 2633832958 SpecialIgnitorLoop80Resistance "Resistance of Special Ignitor Loop 80. Since there are many different vehicle types (e.g. truck, bus, firetruck or";
CM_ SG_ 2633832958 SpecialIgnitorLoop79Resistance "Resistance of Special Ignitor Loop 79. Since there are many different vehicle types (e.g. truck, bus, firetruck or";
CM_ SG_ 2633832958 SpecialIgnitorLoop78Resistance "Resistance of Special Ignitor Loop 78. Since there are many different vehicle types (e.g. truck, bus, firetruck or";
CM_ SG_ 2633832958 SpecialIgnitorLoop77Resistance "Resistance of Special Ignitor Loop 77. Since there are many different vehicle types (e.g. truck, bus, firetruck or";
CM_ SG_ 2633832958 SpecialIgnitorLoop76Resistance "Resistance of Special Ignitor Loop 76. Since there are many different vehicle types (e.g. truck, bus, firetruck or";
CM_ SG_ 2633832958 SpecialIgnitorLoop75Resistance "Resistance of Special Ignitor Loop 75. Since there are many different vehicle types (e.g. truck, bus, firetruck or";
CM_ SG_ 2633832958 SpecialIgnitorLoop74Resistance "Resistance of Special Ignitor Loop 74. Since there are many different vehicle types (e.g. truck, bus, firetruck or";
CM_ SG_ 2633832958 SpecialIgnitorLoop73Resistance "Resistance of Special Ignitor Loop 73. Since there are many different vehicle types (e.g. truck, bus, firetruck or";
CM_ SG_ 2633832958 SpecialIgnitorLoop72Resistance "Resistance of Special Ignitor Loop 72. Since there are many different vehicle types (e.g. truck, bus, firetruck or";
CM_ SG_ 2633832958 SpecialIgnitorLoop71Resistance "Resistance of Special Ignitor Loop 71. Since there are many different vehicle types (e.g. truck, bus, firetruck or";
CM_ SG_ 2633832958 SpecialIgnitorLoop70Resistance "Resistance of Special Ignitor Loop 70. Since there are many different vehicle types (e.g. truck, bus, firetruck or";
CM_ SG_ 2633832958 SpecialIgnitorLoop69Resistance "Resistance of Special Ignitor Loop 69. Since there are many different vehicle types (e.g. truck, bus, firetruck or";
CM_ SG_ 2633832958 SpecialIgnitorLoop68Resistance "Resistance of Special Ignitor Loop 68. Since there are many different vehicle types (e.g. truck, bus, firetruck or";
CM_ SG_ 2633832958 SpecialIgnitorLoop67Resistance "Resistance of Special Ignitor Loop 67. Since there are many different vehicle types (e.g. truck, bus, firetruck or";
CM_ SG_ 2633832958 SpecialIgnitorLoop66Resistance "Resistance of Special Ignitor Loop 66. Since there are many different vehicle types (e.g. truck, bus, firetruck or";
CM_ SG_ 2633832958 SpecialIgnitorLoop65Resistance "Resistance of Special Ignitor Loop 65. Since there are many different vehicle types (e.g. truck, bus, firetruck or";
CM_ SG_ 2633832958 SpecialIgnitorLoop64Resistance "Resistance of Special Ignitor Loop 64. Since there are many different vehicle types (e.g. truck, bus, firetruck or";
CM_ SG_ 2633832958 SpecialIgnitorLoop63Resistance "Resistance of Special Ignitor Loop 63. Since there are many different vehicle types (e.g. truck, bus, firetruck or";
CM_ SG_ 2633832958 SpecialIgnitorLoop61Resistance "Resistance of Special Ignitor Loop 61. Since there are many different vehicle types (e.g. truck, bus, firetruck or";
CM_ SG_ 2633832958 SpecialIgnitorLoop60Resistance "Resistance of Special Ignitor Loop 60. Since there are many different vehicle types (e.g. truck, bus, firetruck or";
CM_ SG_ 2633832958 SpecialIgnitorLoop59Resistance "Resistance of Special Ignitor Loop 59. Since there are many different vehicle types (e.g. truck, bus, firetruck or";
CM_ SG_ 2633832958 SpecialIgnitorLoop58Resistance "Resistance of Special Ignitor Loop 58. Since there are many different vehicle types (e.g. truck, bus, firetruck or";
CM_ SG_ 2633832958 SpecialIgnitorLoop57Resistance "Resistance of Special Ignitor Loop 57. Since there are many different vehicle types (e.g. truck, bus, firetruck or";
CM_ SG_ 2633832958 SpecialIgnitorLoop56Resistance "Resistance of Special Ignitor Loop 56. Since there are many different vehicle types (e.g. truck, bus, firetruck or";
CM_ SG_ 2633832958 SpecialIgnitorLoop55Resistance "Resistance of Special Ignitor Loop 55. Since there are many different vehicle types (e.g. truck, bus, firetruck or";
CM_ SG_ 2633832958 SpecialIgnitorLoop54Resistance "Resistance of Special Ignitor Loop 54. Since there are many different vehicle types (e.g. truck, bus, firetruck or";
CM_ SG_ 2633832958 SpecialIgnitorLoop53Resistance "Resistance of Special Ignitor Loop 53. Since there are many different vehicle types (e.g. truck, bus, firetruck or";
CM_ SG_ 2633832958 SpecialIgnitorLoop52Resistance "Resistance of Special Ignitor Loop 52. Since there are many different vehicle types (e.g. truck, bus, firetruck or";
CM_ SG_ 2633832958 SpecialIgnitorLoop51Resistance "Resistance of Special Ignitor Loop 51. Since there are many different vehicle types (e.g. truck, bus, firetruck or";
CM_ SG_ 2633832958 SpecialIgnitorLoop50Resistance "Resistance of Special Ignitor Loop 50. Since there are many different vehicle types (e.g. truck, bus, firetruck or";
CM_ SG_ 2633832958 SpecialIgnitorLoop49Resistance "Resistance of Special Ignitor Loop 49. Since there are many different vehicle types (e.g. truck, bus, firetruck or";
CM_ SG_ 2633832958 SpecialIgnitorLoop48Resistance "Resistance of Special Ignitor Loop 48. Since there are many different vehicle types (e.g. truck, bus, firetruck or";
CM_ SG_ 2633832958 SpecialIgnitorLoop47Resistance "Resistance of Special Ignitor Loop 47. Since there are many different vehicle types (e.g. truck, bus, firetruck or";
CM_ SG_ 2633832958 SpecialIgnitorLoop46Resistance "Resistance of Special Ignitor Loop 46. Since there are many different vehicle types (e.g. truck, bus, firetruck or";
CM_ SG_ 2633832958 SpecialIgnitorLoop45Resistance "Resistance of Special Ignitor Loop 45. Since there are many different vehicle types (e.g. truck, bus, firetruck or";
CM_ SG_ 2633832958 SpecialIgnitorLoop44Resistance "Resistance of Special Ignitor Loop 44. Since there are many different vehicle types (e.g. truck, bus, firetruck or";
CM_ SG_ 2633832958 SpecialIgnitorLoop43Resistance "Resistance of Special Ignitor Loop 43. Since there are many different vehicle types (e.g. truck, bus, firetruck or";
CM_ SG_ 2633832958 SpecialIgnitorLoop42Resistance "Resistance of Special Ignitor Loop 42. Since there are many different vehicle types (e.g. truck, bus, firetruck or";
CM_ SG_ 2633832958 SpecialIgnitorLoop41Resistance "Resistance of Special Ignitor Loop 41. Since there are many different vehicle types (e.g. truck, bus, firetruck or";
CM_ SG_ 2633832958 SpecialIgnitorLoop40Resistance "Resistance of Special Ignitor Loop 40. Since there are many different vehicle types (e.g. truck, bus, firetruck or";
CM_ SG_ 2633832958 SpecialIgnitorLoop39Resistance "Resistance of Special Ignitor Loop 39. Since there are many different vehicle types (e.g. truck, bus, firetruck or";
CM_ SG_ 2633832958 SpecialIgnitorLoop38Resistance "Resistance of Special Ignitor Loop 38. Since there are many different vehicle types (e.g. truck, bus, firetruck or";
CM_ SG_ 2633832958 SpecialIgnitorLoop37Resistance "Resistance of Special Ignitor Loop 37. Since there are many different vehicle types (e.g. truck, bus, firetruck or";
CM_ SG_ 2633832958 SpecialIgnitorLoop36Resistance "Resistance of Special Ignitor Loop 36. Since there are many different vehicle types (e.g. truck, bus, firetruck or";
CM_ SG_ 2633832958 SpecialIgnitorLoop35Resistance "Resistance of Special Ignitor Loop 35. Since there are many different vehicle types (e.g. truck, bus, firetruck or";
CM_ SG_ 2633832958 SpecialIgnitorLoop34Resistance "Resistance of Special Ignitor Loop 34. Since there are many different vehicle types (e.g. truck, bus, firetruck or";
CM_ SG_ 2633832958 SpecialIgnitorLoop33Resistance "Resistance of Special Ignitor Loop 33. Since there are many different vehicle types (e.g. truck, bus, firetruck or";
CM_ SG_ 2633832958 SpecialIgnitorLoop32Resistance "Resistance of Special Ignitor Loop 32. Since there are many different vehicle types (e.g. truck, bus, firetruck or";
CM_ SG_ 2633832958 SpecialIgnitorLoop31Resistance "Resistance of Special Ignitor Loop 31. Since there are many different vehicle types (e.g. truck, bus, firetruck or";
CM_ SG_ 2633832958 SpecialIgnitorLoop30Resistance "Resistance of Special Ignitor Loop 30. Since there are many different vehicle types (e.g. truck, bus, firetruck or";
CM_ SG_ 2633832958 SpecialIgnitorLoop29Resistance "Resistance of Special Ignitor Loop 29. Since there are many different vehicle types (e.g. truck, bus, firetruck or";
CM_ SG_ 2633832958 SpecialIgnitorLoop28Resistance "Resistance of Special Ignitor Loop 28. Since there are many different vehicle types (e.g. truck, bus, firetruck or";
CM_ SG_ 2633832958 SpecialIgnitorLoop27Resistance "Resistance of Special Ignitor Loop 27. Since there are many different vehicle types (e.g. truck, bus, firetruck or";
CM_ SG_ 2633832958 SpecialIgnitorLoop26Resistance "Resistance of Special Ignitor Loop 26. Since there are many different vehicle types (e.g. truck, bus, firetruck or";
CM_ SG_ 2633832958 SpecialIgnitorLoop25Resistance "Resistance of Special Ignitor Loop 25. Since there are many different vehicle types (e.g. truck, bus, firetruck or";
CM_ SG_ 2633832958 SpecialIgnitorLoop24Resistance "Resistance of Special Ignitor Loop 24. Since there are many different vehicle types (e.g. truck, bus, firetruck or";
CM_ SG_ 2633832958 SpecialIgnitorLoop23Resistance "Resistance of Special Ignitor Loop 23. Since there are many different vehicle types (e.g. truck, bus, firetruck or";
CM_ SG_ 2633832958 SpecialIgnitorLoop22Resistance "Resistance of Special Ignitor Loop 22. Since there are many different vehicle types (e.g. truck, bus, firetruck or";
CM_ SG_ 2633832958 SpecialIgnitorLoop21Resistance "Resistance of Special Ignitor Loop 21. Since there are many different vehicle types (e.g. truck, bus, firetruck or";
CM_ SG_ 2633832958 SpecialIgnitorLoop20Resistance "Resistance of Special Ignitor Loop 20. Since there are many different vehicle types (e.g. truck, bus, firetruck or";
CM_ SG_ 2633832958 SpecialIgnitorLoop19Resistance "Resistance of Special Ignitor Loop 19. Since there are many different vehicle types (e.g. truck, bus, firetruck or";
CM_ SG_ 2633832958 SpecialIgnitorLoop18Resistance "Resistance of Special Ignitor Loop 18. Since there are many different vehicle types (e.g. truck, bus, firetruck or";
CM_ SG_ 2633832958 SpecialIgnitorLoop17Resistance "Resistance of Special Ignitor Loop 17. Since there are many different vehicle types (e.g. truck, bus, firetruck or";
CM_ SG_ 2633832958 SpecialIgnitorLoop16Resistance "Resistance of Special Ignitor Loop 16. Since there are many different vehicle types (e.g. truck, bus, firetruck or";
CM_ SG_ 2633832958 SpecialIgnitorLoop15Resistance "Resistance of Special Ignitor Loop 15. Since there are many different vehicle types (e.g. truck, bus, firetruck or";
CM_ SG_ 2633832958 SpecialIgnitorLoop14Resistance "Resistance of Special Ignitor Loop 14. Since there are many different vehicle types (e.g. truck, bus, firetruck or";
CM_ SG_ 2633832958 SpecialIgnitorLoop13Resistance "Resistance of Special Ignitor Loop 13. Since there are many different vehicle types (e.g. truck, bus, firetruck or";
CM_ SG_ 2633832958 SpecialIgnitorLoop12Resistance "Resistance of Special Ignitor Loop 12. Since there are many different vehicle types (e.g. truck, bus, firetruck or";
CM_ SG_ 2633832958 SpecialIgnitorLoop11Resistance "Resistance of Special Ignitor Loop 11. Since there are many different vehicle types (e.g. truck, bus, firetruck or";
CM_ SG_ 2633832958 SpecialIgnitorLoop10Resistance "Resistance of Special Ignitor Loop 10. Since there are many different vehicle types (e.g. truck, bus, firetruck or";
CM_ SG_ 2633832958 SpecialIgnitorLoop9Resistance "Resistance of Special Ignitor Loop 9. Since there are many different vehicle types (e.g. truck, bus, firetruck or";
CM_ SG_ 2633832958 SpecialIgnitorLoop8Resistance "Resistance of Special Ignitor Loop 8. Since there are many different vehicle types (e.g. truck, bus, firetruck or";
CM_ SG_ 2633832958 SpecialIgnitorLoop7Resistance "Resistance of Special Ignitor Loop 7. Since there are many different vehicle types (e.g. truck, bus, firetruck or";
CM_ SG_ 2633832958 SpecialIgnitorLoop6Resistance "Resistance of Special Ignitor Loop 6. Since there are many different vehicle types (e.g. truck, bus, firetruck or";
CM_ SG_ 2633832958 SpecialIgnitorLoop5Resistance "Resistance of Special Ignitor Loop 5. Since there are many different vehicle types (e.g. truck, bus, firetruck or";
CM_ SG_ 2633832958 SpecialIgnitorLoop4Resistance "Resistance of Special Ignitor Loop 4. Since there are many different vehicle types (e.g. truck, bus, firetruck or";
CM_ SG_ 2633832958 SpecialIgnitorLoop3Resistance "Resistance of Special Ignitor Loop 3. Since there are many different vehicle types (e.g. truck, bus, firetruck or";
CM_ SG_ 2633832958 SpecialIgnitorLoop2Resistance "Resistance of Special Ignitor Loop 2. Since there are many different vehicle types (e.g. truck, bus, firetruck or";
CM_ SG_ 2633832958 SpecialIgnitorLoop1Resistance "Resistance of Special Ignitor Loop 1. Since there are many different vehicle types (e.g. truck, bus, firetruck or";
CM_ SG_ 2633832958 SdBagIgnitorLoop2RightResistance "Resistance of Side Bag Ignitor Loop 2 - Right.";
CM_ SG_ 2633832958 SdBagIgnitorLoop1RightResistance "Resistance of Side Bag Ignitor Loop 1 - Right.";
CM_ SG_ 2633832958 SdeBagIgnitorLoop2LeftResistance "Resistance of Side Bag Ignitor Loop 2 - Left.";
CM_ SG_ 2633832958 SdeBagIgnitorLoop1LeftResistance "Resistance of Side Bag Ignitor Loop 1 - Left.";
CM_ SG_ 2633832958 PssngrBltTnsnrIgntrLopResistance "Resistance of Passenger Belt Tensioner Ignitor Loop 1st Stage.";
CM_ SG_ 2633832958 DrvrBltTnsnrIgntorLoopResistance "Resistance of Driver Belt Tensioner Ignitor Loop 1st Stage.";
CM_ SG_ 2633832958 PssngrArbgIgntrLp2ndStgRsistance "Resistance of Passenger Airbag Ignitor Loop 2nd Stage.";
CM_ SG_ 2633832958 DrvrArbgIgntrLp2ndStgeResistance "Resistance of Driver Airbag Ignitor Loop 2nd Stage.";
CM_ SG_ 2633832958 PssngrArbgIgntrLp1stStgRsistance "Resistance of Passenger Airbag Ignitor Loop 1st Stage.";
CM_ SG_ 2633832958 DrvrArbgIgntrLp1stStgeResistance "Resistance of Driver Airbag Ignitor Loop 1st Stage.";
CM_ BO_ 2566719998 "Engine fuel consumption accumulators. See PGN 65257 for alternate resolution.";
CM_ SG_ 2566719998 HighResolutionEngTotalFuelUsed "Accumulated amount of fuel used during vehicle operation. High resolution used for calculations and fleet management";
CM_ SG_ 2566719998 HighResolutionEngTripFuel "Fuel consumed during all or part of a journey. High resolution used for calculations and fleet management systems. See";
CM_ BO_ 2565877502 "Engine Turbocharger Wastegate Actuator Control Command";
CM_ SG_ 2565877502 EngTurboWastegateActuator2Cmd "The command to a Turbocharger Wastegate actuator 2, normalized to percent, where 0% nominally represents fully";
CM_ SG_ 2565877502 EngTurboWastegateActuator1Cmd "The ccommand to a Turbocharger Wastegate actuator 1, normalized to percent, where 0% nominally represents fully";
CM_ BO_ 2566713854 "Engine Turbocharger Wastegate Actuator Information";
CM_ SG_ 2566713854 EngTrbWstgtActtr2OperationStatus "Used to identify the status of Engine Turbocharger Wastegate Actuator 2";
CM_ SG_ 2566713854 EngTrbWstgtActtr1OperationStatus "Used to identify the status of Engine Turbocharger Wastegate Actuator 1";
CM_ SG_ 2566713854 EngTrbWstgateActuator2TempStatus "Used to identify the status of the Engine Turbocharger Wastegate Actuator 2 drive circuitry temperature. Temperature";
CM_ SG_ 2566713854 EngTrbWstgtActtor2PreliminaryFMI "Used to identify the applicable J1939-73 FMI detected in the Engine Turbocharger Wastegate Actuator 2 by the";
CM_ BO_ 2566714366 "Engine Turbocharger Compressor Bypass Information";
CM_ SG_ 2566714366 EngTrbCmprssrBypssActtr2OprtnStt "Used to identify the status of Engine Turbocharger Compressor Bypass Actuator 2";
CM_ SG_ 2566714366 EngTrbCmprssrBypssActtr1OprtnStt "Used to identify the status of Engine Turbocharger Compressor Bypass Actuator 1";
CM_ SG_ 2566714366 EngTrbCmprssrBypssActtr2TmpSttus "Used to identify the status of the Engine Turbocharger Compresssor Bypass Actuator 2 drive circuitry temperature.";
CM_ SG_ 2566714366 EngTrbCmprssrBypssActtr2PrlmnryF "Used to identify the applicable J1939-73 FMI detected in the Engine Turbocharger Compressor Bypass Actuator 1 by the";
CM_ SG_ 2566714366 EngDsrdTrbCmprssrBypssActtor2Pos "The desired position of the Engine Turbocharger Compressor Bypass actuator 2 by the engine ECM, where 0%";
CM_ SG_ 2566714366 EngTrbCmprssorBypassActuator2Pos "Measures the position of the turbocharger compressor bypass actuator 2, where 0% represents bypass fully closed and";
BA_DEF_ BO_  "GenMsgCycleTimeFast" INT 0 3600000;
BA_DEF_ SG_  "SigType" ENUM  "Default","Range","RangeSigned","ASCII","Discrete","Control","ReferencePGN","DTC","StringDelimiter","StringLength","StringLengthControl";
BA_DEF_ SG_  "GenSigStartValue" INT 0 10000;
BA_DEF_ SG_  "GenSigSendType" ENUM  "Cyclic","OnWrite","reserved","OnChange","reserved","reserved","reserved","NoSigSendType";
BA_DEF_ SG_  "GenSigILSupport" ENUM  "Yes","No";
BA_DEF_ SG_  "GenSigEVName" STRING ;
BA_DEF_ SG_  "SPN" INT 0 524287;
BA_DEF_ SG_  "DDI" INT 0 65535;
BA_DEF_ SG_  "SAEDocument" STRING ;
BA_DEF_ BO_  "GenMsgStartDelayTime" INT 0 100000;
BA_DEF_ BO_  "GenMsgILSupport" ENUM  "Yes","No";
BA_DEF_ BO_  "GenMsgRequestable" INT 0 1;
BA_DEF_ BO_  "GenMsgSendType" ENUM  "cyclic","reserved","cyclicIfActive","reserved","reserved","reserved","reserved","reserved","noMsgSendType";
BA_DEF_ BO_  "VFrameFormat" ENUM  "StandardCAN","ExtendedCAN","reserved","J1939PG";
BA_DEF_ BO_  "SingleFrame" INT 0 1;
BA_DEF_ BO_  "GenMsgCycleTime" INT 0 3600000;
BA_DEF_ BO_  "SAE_Document" STRING ;
BA_DEF_ SG_  "SystemSignalLongSymbol" STRING ;
BA_DEF_DEF_  "GenMsgCycleTimeFast" 0;
BA_DEF_DEF_  "SigType" "Default";
BA_DEF_DEF_  "GenSigStartValue" 0;
BA_DEF_DEF_  "GenSigSendType" "NoSigSendType";
BA_DEF_DEF_  "GenSigILSupport" "Yes";
BA_DEF_DEF_  "GenSigEVName" "Env@Nodename_@Signame";
BA_DEF_DEF_  "SPN" 0;
BA_DEF_DEF_  "DDI" 0;
BA_DEF_DEF_  "SAEDocument" "";
BA_DEF_DEF_  "GenMsgStartDelayTime" 0;
BA_DEF_DEF_  "GenMsgILSupport" "Yes";
BA_DEF_DEF_  "GenMsgRequestable" 1;
BA_DEF_DEF_  "GenMsgSendType" "noMsgSendType";
BA_DEF_DEF_  "VFrameFormat" "J1939PG";
BA_DEF_DEF_  "SingleFrame" 1;
BA_DEF_DEF_  "GenMsgCycleTime" 0;
BA_DEF_DEF_  "SAE_Document" "";
BA_DEF_DEF_  "SystemSignalLongSymbol" "";
BA_ "GenMsgCycleTime" BO_ 2365474046 100;
BA_ "GenMsgCycleTime" BO_ 2365474558 100;
BA_ "GenMsgCycleTime" BO_ 2566704384 500;
BA_ "GenMsgCycleTime" BO_ 2365378048 500;
BA_ "GenMsgCycleTimeFast" BO_ 2365378048 100;
BA_ "GenMsgCycleTime" BO_ 2314732286 250;
BA_ "GenMsgCycleTime" BO_ 2365468670 100;
BA_ "GenMsgCycleTime" BO_ 2365464574 100;
BA_ "GenMsgCycleTime" BO_ 2365472766 1000;
BA_ "GenMsgCycleTime" BO_ 2365468414 100;
BA_ "GenMsgCycleTime" BO_ 2365464318 100;
BA_ "GenMsgCycleTime" BO_ 2365472510 1000;
BA_ "GenMsgCycleTime" BO_ 2365468158 100;
BA_ "GenMsgCycleTime" BO_ 2365464062 100;
BA_ "GenMsgCycleTime" BO_ 2365472254 1000;
BA_ "GenMsgCycleTime" BO_ 2365467902 100;
BA_ "GenMsgCycleTime" BO_ 2365463806 100;
BA_ "GenMsgCycleTime" BO_ 2365471998 1000;
BA_ "GenMsgCycleTime" BO_ 2365467646 100;
BA_ "GenMsgCycleTime" BO_ 2365463550 100;
BA_ "GenMsgCycleTime" BO_ 2365471742 1000;
BA_ "GenMsgCycleTime" BO_ 2365467390 100;
BA_ "GenMsgCycleTime" BO_ 2365463294 100;
BA_ "GenMsgCycleTime" BO_ 2365471486 1000;
BA_ "GenMsgCycleTime" BO_ 2365467134 100;
BA_ "GenMsgCycleTime" BO_ 2365463038 100;
BA_ "GenMsgCycleTime" BO_ 2365471230 1000;
BA_ "GenMsgCycleTime" BO_ 2365466878 100;
BA_ "GenMsgCycleTime" BO_ 2365462782 100;
BA_ "GenMsgCycleTime" BO_ 2365470974 1000;
BA_ "GenMsgCycleTime" BO_ 2365466622 100;
BA_ "GenMsgCycleTime" BO_ 2365462526 100;
BA_ "GenMsgCycleTime" BO_ 2365470718 1000;
BA_ "GenMsgCycleTime" BO_ 2365466366 100;
BA_ "GenMsgCycleTime" BO_ 2365462270 100;
BA_ "GenMsgCycleTime" BO_ 2365470462 1000;
BA_ "GenMsgCycleTime" BO_ 2365466110 100;
BA_ "GenMsgCycleTime" BO_ 2365462014 100;
BA_ "GenMsgCycleTime" BO_ 2365470206 1000;
BA_ "GenMsgCycleTime" BO_ 2365465854 100;
BA_ "GenMsgCycleTime" BO_ 2365461758 100;
BA_ "GenMsgCycleTime" BO_ 2365469950 1000;
BA_ "GenMsgCycleTime" BO_ 2365465598 100;
BA_ "GenMsgCycleTime" BO_ 2365461502 100;
BA_ "GenMsgCycleTime" BO_ 2365469694 1000;
BA_ "GenMsgCycleTime" BO_ 2365465342 100;
BA_ "GenMsgCycleTime" BO_ 2365461246 100;
BA_ "GenMsgCycleTime" BO_ 2365469438 1000;
BA_ "GenMsgCycleTime" BO_ 2365465086 100;
BA_ "GenMsgCycleTime" BO_ 2365460990 100;
BA_ "GenMsgCycleTime" BO_ 2365469182 1000;
BA_ "GenMsgCycleTime" BO_ 2365464830 100;
BA_ "GenMsgCycleTime" BO_ 2365460734 100;
BA_ "GenMsgCycleTime" BO_ 2365468926 1000;
BA_ "GenMsgSendType" BO_ 2297441790 0;
BA_ "GenMsgCycleTime" BO_ 2297441790 10;
BA_ "SAE_Document" BO_ 2297441790 "J1939-71";
BA_ "SAE_Document" BO_ 2566712062 "J1939-71";
BA_ "GenMsgSendType" BO_ 2364549630 0;
BA_ "GenMsgCycleTime" BO_ 2364549630 10;
BA_ "SAE_Document" BO_ 2364549630 "J1939-71";
BA_ "GenMsgSendType" BO_ 2499614462 0;
BA_ "GenMsgCycleTime" BO_ 2499614462 5000;
BA_ "SAE_Document" BO_ 2499614462 "J1939-71";
BA_ "GenMsgSendType" BO_ 2560098046 0;
BA_ "GenMsgCycleTime" BO_ 2560098046 10000;
BA_ "SAE_Document" BO_ 2560098046 "J1939-71";
BA_ "GenMsgSendType" BO_ 2560163582 0;
BA_ "GenMsgCycleTime" BO_ 2560163582 10000;
BA_ "SAE_Document" BO_ 2560163582 "J1939-71";
BA_ "GenMsgSendType" BO_ 2297441534 0;
BA_ "GenMsgCycleTime" BO_ 2297441534 50;
BA_ "SAE_Document" BO_ 2297441534 "J1939-71";
BA_ "GenMsgSendType" BO_ 2566722302 0;
BA_ "GenMsgCycleTime" BO_ 2566722302 500;
BA_ "SAE_Document" BO_ 2566722302 "J1939-71";
BA_ "SAE_Document" BO_ 2566722558 "J1939-71";
BA_ "GenMsgSendType" BO_ 2560032510 0;
BA_ "GenMsgCycleTime" BO_ 2560032510 500;
BA_ "SAE_Document" BO_ 2560032510 "J1939-71";
BA_ "GenMsgSendType" BO_ 2566717950 0;
BA_ "GenMsgCycleTime" BO_ 2566717950 500;
BA_ "SAE_Document" BO_ 2566717950 "J1939-71";
BA_ "GenMsgSendType" BO_ 2499604222 0;
BA_ "GenMsgCycleTime" BO_ 2499604222 200;
BA_ "SAE_Document" BO_ 2499604222 "J1939-71";
BA_ "GenMsgSendType" BO_ 2358902526 0;
BA_ "GenMsgCycleTime" BO_ 2358902526 100;
BA_ "SAE_Document" BO_ 2358902526 "J1939-71";
BA_ "GenMsgSendType" BO_ 2566711550 0;
BA_ "GenMsgCycleTime" BO_ 2566711550 500;
BA_ "SAE_Document" BO_ 2566711550 "J1939-71";
BA_ "SAE_Document" BO_ 2633832958 "J1939-71";
BA_ "GenMsgSendType" BO_ 2566719998 0;
BA_ "GenMsgCycleTime" BO_ 2566719998 1000;
BA_ "SAE_Document" BO_ 2566719998 "J1939-71";
BA_ "SAE_Document" BO_ 2565877502 "J1939-71";
BA_ "GenMsgSendType" BO_ 2566713854 0;
BA_ "GenMsgCycleTime" BO_ 2566713854 100;
BA_ "SAE_Document" BO_ 2566713854 "J1939-71";
BA_ "GenMsgSendType" BO_ 2566714366 0;
BA_ "GenMsgCycleTime" BO_ 2566714366 100;
BA_ "SAE_Document" BO_ 2566714366 "J1939-71";
BA_ "SystemSignalLongSymbol" SG_ 2628452094 VS_RequestVolumeToPrepareForRemo "VS_RequestVolumeToPrepareForRemoval";
BA_ "SigType" SG_ 2628452094 VS_VolumeName 9;
BA_ "SigType" SG_ 2628452094 FDT_PathName 9;
BA_ "SigType" SG_ 2628452094 GA_PathName 9;
BA_ "SigType" SG_ 2628452094 CCD_PathName 9;
BA_ "SigType" SG_ 2628452094 SA_PathName 9;
BA_ "SigType" SG_ 2628452094 DF_PathName 9;
BA_ "SigType" SG_ 2628452094 OF_PathName 9;
BA_ "SigType" SG_ 2628452094 VI_VolumeName 9;
BA_ "SPN" SG_ 2365474046 FrontPTOOutShaftSpeed 1882;
BA_ "SigType" SG_ 2365474046 FrontPTOOutShaftSpeed 1;
BA_ "SPN" SG_ 2365474046 FrontPTOOutShaftSpeedSetPoint 1884;
BA_ "SigType" SG_ 2365474046 FrontPTOOutShaftSpeedSetPoint 1;
BA_ "SPN" SG_ 2365474046 FrontPTOEngagementRqStatus 5152;
BA_ "SigType" SG_ 2365474046 FrontPTOEngagementRqStatus 4;
BA_ "SPN" SG_ 2365474046 FrontPTOEconomyMode 1891;
BA_ "SigType" SG_ 2365474046 FrontPTOEconomyMode 4;
BA_ "SPN" SG_ 2365474046 FrontPTOMode 1889;
BA_ "SigType" SG_ 2365474046 FrontPTOMode 4;
BA_ "SPN" SG_ 2365474046 FrontPTOEngagement 1888;
BA_ "SigType" SG_ 2365474046 FrontPTOEngagement 4;
BA_ "SPN" SG_ 2365474046 FrontPTOShaftSpeedLimitStatus 5155;
BA_ "SPN" SG_ 2365474046 FrontPTOEconomyModeRqStatus 5154;
BA_ "SigType" SG_ 2365474046 FrontPTOEconomyModeRqStatus 4;
BA_ "SPN" SG_ 2365474046 FrontPTOModeRqStatus 5153;
BA_ "SigType" SG_ 2365474046 FrontPTOModeRqStatus 4;
BA_ "SPN" SG_ 2365474558 FrontHitchPosition 1872;
BA_ "SigType" SG_ 2365474558 FrontHitchPosition 1;
BA_ "SPN" SG_ 2365474558 FrontHitchPositionLimitStatus 5150;
BA_ "SPN" SG_ 2365474558 FrontHitchInWorkIndication 1876;
BA_ "SigType" SG_ 2365474558 FrontHitchInWorkIndication 4;
BA_ "SPN" SG_ 2365474558 FrontNominalLowerLinkForce 1880;
BA_ "SigType" SG_ 2365474558 FrontNominalLowerLinkForce 1;
BA_ "SPN" SG_ 2365474558 FrontDraft 1878;
BA_ "SigType" SG_ 2365474558 FrontDraft 1;
BA_ "SigType" SG_ 2563243774 SequenceNumber 1;
BA_ "GenSigStartValue" SG_ 2563243774 SequenceNumber 1;
BA_ "SPN" SG_ 2563243774 SequenceNumber 2572;
BA_ "SAEDocument" SG_ 2563243774 SequenceNumber "J1939-21";
BA_ "SigType" SG_ 2563243774 Byte1 1;
BA_ "SigType" SG_ 2563243774 Byte2 1;
BA_ "SigType" SG_ 2563243774 Byte3 1;
BA_ "SigType" SG_ 2563243774 Byte4 1;
BA_ "SigType" SG_ 2563243774 Byte5 1;
BA_ "SigType" SG_ 2563243774 Byte6 1;
BA_ "SigType" SG_ 2563243774 Byte7 1;
BA_ "SPN" SG_ 2563309310 ConnectionAbortReason 2570;
BA_ "SAEDocument" SG_ 2563309310 ConnectionAbortReason "J1939-21";
BA_ "SigType" SG_ 2563309310 ControlByte 1;
BA_ "SPN" SG_ 2563309310 ControlByte 2541;
BA_ "SAEDocument" SG_ 2563309310 ControlByte "J1939-21";
BA_ "SigType" SG_ 2563309310 NumberOfBytesToTransfer 1;
BA_ "GenSigStartValue" SG_ 2563309310 NumberOfBytesToTransfer 1786;
BA_ "SigType" SG_ 2563309310 NumberOfPacketsToSend 1;
BA_ "GenSigStartValue" SG_ 2563309310 NumberOfPacketsToSend 1;
BA_ "SigType" SG_ 2563309310 NumberOfPacketsOffset 1;
BA_ "GenSigStartValue" SG_ 2563309310 NumberOfPacketsOffset 1;
BA_ "SigType" SG_ 2563309310 NumberOfBytesTransfered 1;
BA_ "GenSigStartValue" SG_ 2563309310 NumberOfBytesTransfered 1786;
BA_ "SigType" SG_ 2563309310 NextPacketNumberToSend 1;
BA_ "GenSigStartValue" SG_ 2563309310 NextPacketNumberToSend 1;
BA_ "SigType" SG_ 2563309310 DataPacketOffset 1;
BA_ "SigType" SG_ 2563309310 PGNumber 6;
BA_ "SPN" SG_ 2563309310 PGNumber 2560;
BA_ "SAEDocument" SG_ 2563309310 PGNumber "J1939-21";
BA_ "SPN" SG_ 2566704384 DriveStrategyRequestState 5731;
BA_ "SPN" SG_ 2566704384 DriveStrategyPriority4 5730;
BA_ "SPN" SG_ 2566704384 DriveStrategyPriority3 5729;
BA_ "SPN" SG_ 2566704384 DriveStrategyPriority2 5728;
BA_ "SPN" SG_ 2566704384 DriveStrategyPriority1 5727;
BA_ "SPN" SG_ 2566704384 DriveStrategyExitReason 5732;
BA_ "SPN" SG_ 2365378048 RestoreOpDriveStratSetReq 5737;
BA_ "SPN" SG_ 2365378048 DriveStrategyPriority4Req 5736;
BA_ "SPN" SG_ 2365378048 DriveStrategyPriority3Req 5735;
BA_ "SPN" SG_ 2365378048 DriveStrategyPriority2Req 5734;
BA_ "SPN" SG_ 2365378048 DriveStrategyPriority1Req 5733;
BA_ "SAEDocument" SG_ 2314732286 SID "NMEA2000";
BA_ "SigType" SG_ 2314732286 SID 1;
BA_ "SigType" SG_ 2314732286 COGReference 4;
BA_ "SAEDocument" SG_ 2314732286 CourseOverGround "NMEA2000";
BA_ "SigType" SG_ 2314732286 CourseOverGround 1;
BA_ "SAEDocument" SG_ 2314732286 SpeedOverGround "NMEA2000";
BA_ "SigType" SG_ 2314732286 SpeedOverGround 1;
BA_ "GenSigStartValue" SG_ 2566688510 FunctionalityGeneration 1;
BA_ "GenSigStartValue" SG_ 2566688510 NumberOfFunctionalities 1;
BA_ "SPN" SG_ 2365468670 Valve15ExtendedPortMeasuredFlow 2335;
BA_ "SigType" SG_ 2365468670 Valve15ExtendedPortMeasuredFlow 1;
BA_ "SPN" SG_ 2365468670 Valve15RetractPortMeasuredFlow 2336;
BA_ "SigType" SG_ 2365468670 Valve15RetractPortMeasuredFlow 1;
BA_ "SPN" SG_ 2365468670 Valve15ExtendedPortPressure 2340;
BA_ "SigType" SG_ 2365468670 Valve15ExtendedPortPressure 1;
BA_ "SPN" SG_ 2365468670 Valve15RetractPortPressure 2341;
BA_ "SigType" SG_ 2365468670 Valve15RetractPortPressure 1;
BA_ "SPN" SG_ 2365468670 Valve15ReturnPortPressure 2342;
BA_ "SigType" SG_ 2365468670 Valve15ReturnPortPressure 1;
BA_ "SPN" SG_ 2365468670 Valve15LimitStatus 5190;
BA_ "SPN" SG_ 2365464574 Valve15ExtendedPortEstimatedFlow 2337;
BA_ "SigType" SG_ 2365464574 Valve15ExtendedPortEstimatedFlow 1;
BA_ "SPN" SG_ 2365464574 Valve15RetractPortEstimatedFlow 2338;
BA_ "SigType" SG_ 2365464574 Valve15RetractPortEstimatedFlow 1;
BA_ "SPN" SG_ 2365464574 Valve15ValveState 2339;
BA_ "SPN" SG_ 2365464574 Valve15FailSafeMode 2346;
BA_ "SigType" SG_ 2365464574 Valve15FailSafeMode 4;
BA_ "SPN" SG_ 2365464574 Valve15LimitStatus 5190;
BA_ "SPN" SG_ 2365472766 Valve15PortFlowCmd 2343;
BA_ "SigType" SG_ 2365472766 Valve15PortFlowCmd 1;
BA_ "SPN" SG_ 2365472766 Valve15StateCmd 2344;
BA_ "SPN" SG_ 2365472766 Valve15FailSaveModeCmd 2345;
BA_ "SigType" SG_ 2365472766 Valve15FailSaveModeCmd 4;
BA_ "SPN" SG_ 2365468414 Valve14ExtendedPortMeasuredFlow 2323;
BA_ "SigType" SG_ 2365468414 Valve14ExtendedPortMeasuredFlow 1;
BA_ "SPN" SG_ 2365468414 Valve14RetractPortMeasuredFlow 2324;
BA_ "SigType" SG_ 2365468414 Valve14RetractPortMeasuredFlow 1;
BA_ "SPN" SG_ 2365468414 Valve14ExtendedPortPressure 2328;
BA_ "SigType" SG_ 2365468414 Valve14ExtendedPortPressure 1;
BA_ "SPN" SG_ 2365468414 Valve14RetractPortPressure 2329;
BA_ "SigType" SG_ 2365468414 Valve14RetractPortPressure 1;
BA_ "SPN" SG_ 2365468414 Valve14ReturnPortPressure 2330;
BA_ "SigType" SG_ 2365468414 Valve14ReturnPortPressure 1;
BA_ "SPN" SG_ 2365468414 Valve14LimitStatus 5188;
BA_ "SPN" SG_ 2365464318 Valve14ExtendedPortEstimatedFlow 2325;
BA_ "SigType" SG_ 2365464318 Valve14ExtendedPortEstimatedFlow 1;
BA_ "SPN" SG_ 2365464318 Valve14RetractPortEstimatedFlow 2326;
BA_ "SigType" SG_ 2365464318 Valve14RetractPortEstimatedFlow 1;
BA_ "SPN" SG_ 2365464318 Valve14ValveState 2327;
BA_ "SPN" SG_ 2365464318 Valve14FailSafeMode 2334;
BA_ "SigType" SG_ 2365464318 Valve14FailSafeMode 4;
BA_ "SPN" SG_ 2365464318 Valve14LimitStatus 5188;
BA_ "SPN" SG_ 2365472510 Valve14PortFlowCmd 2331;
BA_ "SigType" SG_ 2365472510 Valve14PortFlowCmd 1;
BA_ "SPN" SG_ 2365472510 Valve14StateCmd 2332;
BA_ "SPN" SG_ 2365472510 Valve14FailSaveModeCmd 2333;
BA_ "SigType" SG_ 2365472510 Valve14FailSaveModeCmd 4;
BA_ "SPN" SG_ 2365468158 Valve13ExtendedPortMeasuredFlow 2311;
BA_ "SigType" SG_ 2365468158 Valve13ExtendedPortMeasuredFlow 1;
BA_ "SPN" SG_ 2365468158 Valve13RetractPortMeasuredFlow 2312;
BA_ "SigType" SG_ 2365468158 Valve13RetractPortMeasuredFlow 1;
BA_ "SPN" SG_ 2365468158 Valve13ExtendedPortPressure 2316;
BA_ "SigType" SG_ 2365468158 Valve13ExtendedPortPressure 1;
BA_ "SPN" SG_ 2365468158 Valve13RetractPortPressure 2317;
BA_ "SigType" SG_ 2365468158 Valve13RetractPortPressure 1;
BA_ "SPN" SG_ 2365468158 Valve13ReturnPortPressure 2318;
BA_ "SigType" SG_ 2365468158 Valve13ReturnPortPressure 1;
BA_ "SPN" SG_ 2365468158 Valve13LimitStatus 5186;
BA_ "SPN" SG_ 2365464062 Valve13ExtendedPortEstimatedFlow 2313;
BA_ "SigType" SG_ 2365464062 Valve13ExtendedPortEstimatedFlow 1;
BA_ "SPN" SG_ 2365464062 Valve13RetractPortEstimatedFlow 2314;
BA_ "SigType" SG_ 2365464062 Valve13RetractPortEstimatedFlow 1;
BA_ "SPN" SG_ 2365464062 Valve13ValveState 2315;
BA_ "SPN" SG_ 2365464062 Valve13FailSafeMode 2322;
BA_ "SigType" SG_ 2365464062 Valve13FailSafeMode 4;
BA_ "SPN" SG_ 2365464062 Valve13LimitStatus 5186;
BA_ "SPN" SG_ 2365472254 Valve13PortFlowCmd 2319;
BA_ "SigType" SG_ 2365472254 Valve13PortFlowCmd 1;
BA_ "SPN" SG_ 2365472254 Valve13StateCmd 2320;
BA_ "SPN" SG_ 2365472254 Valve13FailSaveModeCmd 2321;
BA_ "SigType" SG_ 2365472254 Valve13FailSaveModeCmd 4;
BA_ "SPN" SG_ 2365467902 Valve12ExtendedPortMeasuredFlow 2299;
BA_ "SigType" SG_ 2365467902 Valve12ExtendedPortMeasuredFlow 1;
BA_ "SPN" SG_ 2365467902 Valve12RetractPortMeasuredFlow 2300;
BA_ "SigType" SG_ 2365467902 Valve12RetractPortMeasuredFlow 1;
BA_ "SPN" SG_ 2365467902 Valve12ExtendedPortPressure 2304;
BA_ "SigType" SG_ 2365467902 Valve12ExtendedPortPressure 1;
BA_ "SPN" SG_ 2365467902 Valve12RetractPortPressure 2305;
BA_ "SigType" SG_ 2365467902 Valve12RetractPortPressure 1;
BA_ "SPN" SG_ 2365467902 Valve12ReturnPortPressure 2306;
BA_ "SigType" SG_ 2365467902 Valve12ReturnPortPressure 1;
BA_ "SPN" SG_ 2365467902 Valve12LimitStatus 5184;
BA_ "SPN" SG_ 2365463806 Valve12ExtendedPortEstimatedFlow 2301;
BA_ "SigType" SG_ 2365463806 Valve12ExtendedPortEstimatedFlow 1;
BA_ "SPN" SG_ 2365463806 Valve12RetractPortEstimatedFlow 2302;
BA_ "SigType" SG_ 2365463806 Valve12RetractPortEstimatedFlow 1;
BA_ "SPN" SG_ 2365463806 Valve12ValveState 2303;
BA_ "SPN" SG_ 2365463806 Valve12FailSafeMode 2310;
BA_ "SigType" SG_ 2365463806 Valve12FailSafeMode 4;
BA_ "SPN" SG_ 2365463806 Valve12LimitStatus 5184;
BA_ "SPN" SG_ 2365471998 Valve12PortFlowCmd 2307;
BA_ "SigType" SG_ 2365471998 Valve12PortFlowCmd 1;
BA_ "SPN" SG_ 2365471998 Valve12StateCmd 2308;
BA_ "SPN" SG_ 2365471998 Valve12FailSaveModeCmd 2309;
BA_ "SigType" SG_ 2365471998 Valve12FailSaveModeCmd 4;
BA_ "SPN" SG_ 2365467646 Valve11ExtendedPortMeasuredFlow 2287;
BA_ "SigType" SG_ 2365467646 Valve11ExtendedPortMeasuredFlow 1;
BA_ "SPN" SG_ 2365467646 Valve11RetractPortMeasuredFlow 2288;
BA_ "SigType" SG_ 2365467646 Valve11RetractPortMeasuredFlow 1;
BA_ "SPN" SG_ 2365467646 Valve11ExtendedPortPressure 2292;
BA_ "SigType" SG_ 2365467646 Valve11ExtendedPortPressure 1;
BA_ "SPN" SG_ 2365467646 Valve11RetractPortPressure 2293;
BA_ "SigType" SG_ 2365467646 Valve11RetractPortPressure 1;
BA_ "SPN" SG_ 2365467646 Valve11ReturnPortPressure 2294;
BA_ "SigType" SG_ 2365467646 Valve11ReturnPortPressure 1;
BA_ "SPN" SG_ 2365467646 Valve11LimitStatus 5182;
BA_ "SPN" SG_ 2365463550 Valve11ExtendedPortEstimatedFlow 2289;
BA_ "SigType" SG_ 2365463550 Valve11ExtendedPortEstimatedFlow 1;
BA_ "SPN" SG_ 2365463550 Valve11RetractPortEstimatedFlow 2290;
BA_ "SigType" SG_ 2365463550 Valve11RetractPortEstimatedFlow 1;
BA_ "SPN" SG_ 2365463550 Valve11ValveState 2291;
BA_ "SPN" SG_ 2365463550 Valve11FailSafeMode 2298;
BA_ "SigType" SG_ 2365463550 Valve11FailSafeMode 4;
BA_ "SPN" SG_ 2365463550 Valve11LimitStatus 5182;
BA_ "SPN" SG_ 2365471742 Valve11PortFlowCmd 2295;
BA_ "SigType" SG_ 2365471742 Valve11PortFlowCmd 1;
BA_ "SPN" SG_ 2365471742 Valve11StateCmd 2296;
BA_ "SPN" SG_ 2365471742 Valve11FailSaveModeCmd 2297;
BA_ "SigType" SG_ 2365471742 Valve11FailSaveModeCmd 4;
BA_ "SPN" SG_ 2365467390 Valve10ExtendedPortMeasuredFlow 2275;
BA_ "SigType" SG_ 2365467390 Valve10ExtendedPortMeasuredFlow 1;
BA_ "SPN" SG_ 2365467390 Valve10RetractPortMeasuredFlow 2276;
BA_ "SigType" SG_ 2365467390 Valve10RetractPortMeasuredFlow 1;
BA_ "SPN" SG_ 2365467390 Valve10ExtendedPortPressure 2280;
BA_ "SigType" SG_ 2365467390 Valve10ExtendedPortPressure 1;
BA_ "SPN" SG_ 2365467390 Valve10RetractPortPressure 2281;
BA_ "SigType" SG_ 2365467390 Valve10RetractPortPressure 1;
BA_ "SPN" SG_ 2365467390 Valve10ReturnPortPressure 2282;
BA_ "SigType" SG_ 2365467390 Valve10ReturnPortPressure 1;
BA_ "SPN" SG_ 2365467390 Valve10LimitStatus 5180;
BA_ "SPN" SG_ 2365463294 Valve10ExtendedPortEstimatedFlow 2277;
BA_ "SigType" SG_ 2365463294 Valve10ExtendedPortEstimatedFlow 1;
BA_ "SPN" SG_ 2365463294 Valve10RetractPortEstimatedFlow 2278;
BA_ "SigType" SG_ 2365463294 Valve10RetractPortEstimatedFlow 1;
BA_ "SPN" SG_ 2365463294 Valve10ValveState 2279;
BA_ "SPN" SG_ 2365463294 Valve10FailSafeMode 2286;
BA_ "SigType" SG_ 2365463294 Valve10FailSafeMode 4;
BA_ "SPN" SG_ 2365463294 Valve10LimitStatus 5180;
BA_ "SPN" SG_ 2365471486 Valve10PortFlowCmd 2283;
BA_ "SigType" SG_ 2365471486 Valve10PortFlowCmd 1;
BA_ "SPN" SG_ 2365471486 Valve10StateCmd 2284;
BA_ "SPN" SG_ 2365471486 Valve10FailSaveModeCmd 2285;
BA_ "SigType" SG_ 2365471486 Valve10FailSaveModeCmd 4;
BA_ "SPN" SG_ 2365467134 Valve9ExtendedPortMeasuredFlow 2263;
BA_ "SigType" SG_ 2365467134 Valve9ExtendedPortMeasuredFlow 1;
BA_ "SPN" SG_ 2365467134 Valve9RetractPortMeasuredFlow 2264;
BA_ "SigType" SG_ 2365467134 Valve9RetractPortMeasuredFlow 1;
BA_ "SPN" SG_ 2365467134 Valve9ExtendedPortPressure 2268;
BA_ "SigType" SG_ 2365467134 Valve9ExtendedPortPressure 1;
BA_ "SPN" SG_ 2365467134 Valve9RetractPortPressure 2269;
BA_ "SigType" SG_ 2365467134 Valve9RetractPortPressure 1;
BA_ "SPN" SG_ 2365467134 Valve9ReturnPortPressure 2270;
BA_ "SigType" SG_ 2365467134 Valve9ReturnPortPressure 1;
BA_ "SPN" SG_ 2365467134 Valve9LimitStatus 5178;
BA_ "SPN" SG_ 2365463038 Valve9ExtendedPortEstimatedFlow 2265;
BA_ "SigType" SG_ 2365463038 Valve9ExtendedPortEstimatedFlow 1;
BA_ "SPN" SG_ 2365463038 Valve9RetractPortEstimatedFlow 2266;
BA_ "SigType" SG_ 2365463038 Valve9RetractPortEstimatedFlow 1;
BA_ "SPN" SG_ 2365463038 Valve9ValveState 2267;
BA_ "SPN" SG_ 2365463038 Valve9FailSafeMode 2274;
BA_ "SigType" SG_ 2365463038 Valve9FailSafeMode 4;
BA_ "SPN" SG_ 2365463038 Valve9LimitStatus 5178;
BA_ "SPN" SG_ 2365471230 Valve9PortFlowCmd 2271;
BA_ "SigType" SG_ 2365471230 Valve9PortFlowCmd 1;
BA_ "SPN" SG_ 2365471230 Valve9StateCmd 2272;
BA_ "SPN" SG_ 2365471230 Valve9FailSaveModeCmd 2273;
BA_ "SigType" SG_ 2365471230 Valve9FailSaveModeCmd 4;
BA_ "SPN" SG_ 2365466878 Valve8ExtendedPortMeasuredFlow 1995;
BA_ "SigType" SG_ 2365466878 Valve8ExtendedPortMeasuredFlow 1;
BA_ "SPN" SG_ 2365466878 Valve8RetractPortMeasuredFlow 1996;
BA_ "SigType" SG_ 2365466878 Valve8RetractPortMeasuredFlow 1;
BA_ "SPN" SG_ 2365466878 Valve8ExtendedPortPressure 2256;
BA_ "SigType" SG_ 2365466878 Valve8ExtendedPortPressure 1;
BA_ "SPN" SG_ 2365466878 Valve8RetractPortPressure 2257;
BA_ "SigType" SG_ 2365466878 Valve8RetractPortPressure 1;
BA_ "SPN" SG_ 2365466878 Valve8ReturnPortPressure 2258;
BA_ "SigType" SG_ 2365466878 Valve8ReturnPortPressure 1;
BA_ "SPN" SG_ 2365466878 Valve8LimitStatus 5176;
BA_ "SPN" SG_ 2365462782 Valve8ExtendedPortEstimatedFlow 1997;
BA_ "SigType" SG_ 2365462782 Valve8ExtendedPortEstimatedFlow 1;
BA_ "SPN" SG_ 2365462782 Valve8RetractPortEstimatedFlow 1998;
BA_ "SigType" SG_ 2365462782 Valve8RetractPortEstimatedFlow 1;
BA_ "SPN" SG_ 2365462782 Valve8ValveState 1999;
BA_ "SPN" SG_ 2365462782 Valve8FailSafeMode 2262;
BA_ "SigType" SG_ 2365462782 Valve8FailSafeMode 4;
BA_ "SPN" SG_ 2365462782 Valve8LimitStatus 5176;
BA_ "SPN" SG_ 2365470974 Valve8PortFlowCmd 2259;
BA_ "SigType" SG_ 2365470974 Valve8PortFlowCmd 1;
BA_ "SPN" SG_ 2365470974 Valve8StateCmd 2260;
BA_ "SPN" SG_ 2365470974 Valve8FailSaveModeCmd 2261;
BA_ "SigType" SG_ 2365470974 Valve8FailSaveModeCmd 4;
BA_ "SPN" SG_ 2365466622 Valve7ExtendedPortMeasuredFlow 1983;
BA_ "SigType" SG_ 2365466622 Valve7ExtendedPortMeasuredFlow 1;
BA_ "SPN" SG_ 2365466622 Valve7RetractPortMeasuredFlow 1984;
BA_ "SigType" SG_ 2365466622 Valve7RetractPortMeasuredFlow 1;
BA_ "SPN" SG_ 2365466622 Valve7ExtendedPortPressure 1988;
BA_ "SigType" SG_ 2365466622 Valve7ExtendedPortPressure 1;
BA_ "SPN" SG_ 2365466622 Valve7RetractPortPressure 1989;
BA_ "SigType" SG_ 2365466622 Valve7RetractPortPressure 1;
BA_ "SPN" SG_ 2365466622 Valve7ReturnPortPressure 1990;
BA_ "SigType" SG_ 2365466622 Valve7ReturnPortPressure 1;
BA_ "SPN" SG_ 2365466622 Valve7LimitStatus 5174;
BA_ "SPN" SG_ 2365462526 Valve7ExtendedPortEstimatedFlow 1985;
BA_ "SigType" SG_ 2365462526 Valve7ExtendedPortEstimatedFlow 1;
BA_ "SPN" SG_ 2365462526 Valve7RetractPortEstimatedFlow 1986;
BA_ "SigType" SG_ 2365462526 Valve7RetractPortEstimatedFlow 1;
BA_ "SPN" SG_ 2365462526 Valve7ValveState 1987;
BA_ "SPN" SG_ 2365462526 Valve7FailSafeMode 1994;
BA_ "SigType" SG_ 2365462526 Valve7FailSafeMode 4;
BA_ "SPN" SG_ 2365462526 Valve7LimitStatus 5174;
BA_ "SPN" SG_ 2365470718 Valve7PortFlowCmd 1991;
BA_ "SigType" SG_ 2365470718 Valve7PortFlowCmd 1;
BA_ "SPN" SG_ 2365470718 Valve7StateCmd 1992;
BA_ "SPN" SG_ 2365470718 Valve7FailSaveModeCmd 1993;
BA_ "SigType" SG_ 2365470718 Valve7FailSaveModeCmd 4;
BA_ "SPN" SG_ 2365466366 Valve6ExtendedPortMeasuredFlow 1971;
BA_ "SigType" SG_ 2365466366 Valve6ExtendedPortMeasuredFlow 1;
BA_ "SPN" SG_ 2365466366 Valve6RetractPortMeasuredFlow 1972;
BA_ "SigType" SG_ 2365466366 Valve6RetractPortMeasuredFlow 1;
BA_ "SPN" SG_ 2365466366 Valve6ExtendedPortPressure 1976;
BA_ "SigType" SG_ 2365466366 Valve6ExtendedPortPressure 1;
BA_ "SPN" SG_ 2365466366 Valve6RetractPortPressure 1977;
BA_ "SigType" SG_ 2365466366 Valve6RetractPortPressure 1;
BA_ "SPN" SG_ 2365466366 Valve6ReturnPortPressure 1978;
BA_ "SigType" SG_ 2365466366 Valve6ReturnPortPressure 1;
BA_ "SPN" SG_ 2365466366 Valve6LimitStatus 5172;
BA_ "SPN" SG_ 2365462270 Valve6ExtendedPortEstimatedFlow 1973;
BA_ "SigType" SG_ 2365462270 Valve6ExtendedPortEstimatedFlow 1;
BA_ "SPN" SG_ 2365462270 Valve6RetractPortEstimatedFlow 1974;
BA_ "SigType" SG_ 2365462270 Valve6RetractPortEstimatedFlow 1;
BA_ "SPN" SG_ 2365462270 Valve6ValveState 1975;
BA_ "SPN" SG_ 2365462270 Valve6FailSafeMode 1982;
BA_ "SigType" SG_ 2365462270 Valve6FailSafeMode 4;
BA_ "SPN" SG_ 2365462270 Valve6LimitStatus 5172;
BA_ "SPN" SG_ 2365470462 Valve6PortFlowCmd 1979;
BA_ "SigType" SG_ 2365470462 Valve6PortFlowCmd 1;
BA_ "SPN" SG_ 2365470462 Valve6StateCmd 1980;
BA_ "SPN" SG_ 2365470462 Valve6FailSaveModeCmd 1981;
BA_ "SigType" SG_ 2365470462 Valve6FailSaveModeCmd 4;
BA_ "SPN" SG_ 2365466110 Valve5ExtendedPortMeasuredFlow 1959;
BA_ "SigType" SG_ 2365466110 Valve5ExtendedPortMeasuredFlow 1;
BA_ "SPN" SG_ 2365466110 Valve5RetractPortMeasuredFlow 1960;
BA_ "SigType" SG_ 2365466110 Valve5RetractPortMeasuredFlow 1;
BA_ "SPN" SG_ 2365466110 Valve5ExtendedPortPressure 1964;
BA_ "SigType" SG_ 2365466110 Valve5ExtendedPortPressure 1;
BA_ "SPN" SG_ 2365466110 Valve5RetractPortPressure 1965;
BA_ "SigType" SG_ 2365466110 Valve5RetractPortPressure 1;
BA_ "SPN" SG_ 2365466110 Valve5ReturnPortPressure 1966;
BA_ "SigType" SG_ 2365466110 Valve5ReturnPortPressure 1;
BA_ "SPN" SG_ 2365466110 Valve5LimitStatus 5170;
BA_ "SPN" SG_ 2365462014 Valve5ExtendedPortEstimatedFlow 1961;
BA_ "SigType" SG_ 2365462014 Valve5ExtendedPortEstimatedFlow 1;
BA_ "SPN" SG_ 2365462014 Valve5RetractPortEstimatedFlow 1962;
BA_ "SigType" SG_ 2365462014 Valve5RetractPortEstimatedFlow 1;
BA_ "SPN" SG_ 2365462014 Valve5ValveState 1963;
BA_ "SPN" SG_ 2365462014 Valve5FailSafeMode 1970;
BA_ "SigType" SG_ 2365462014 Valve5FailSafeMode 4;
BA_ "SPN" SG_ 2365462014 Valve5LimitStatus 5170;
BA_ "SPN" SG_ 2365470206 Valve5PortFlowCmd 1967;
BA_ "SigType" SG_ 2365470206 Valve5PortFlowCmd 1;
BA_ "SPN" SG_ 2365470206 Valve5StateCmd 1968;
BA_ "SPN" SG_ 2365470206 Valve5FailSaveModeCmd 1969;
BA_ "SigType" SG_ 2365470206 Valve5FailSaveModeCmd 4;
BA_ "SPN" SG_ 2365465854 Valve4ExtendedPortMeasuredFlow 1947;
BA_ "SigType" SG_ 2365465854 Valve4ExtendedPortMeasuredFlow 1;
BA_ "SPN" SG_ 2365465854 Valve4RetractPortMeasuredFlow 1948;
BA_ "SigType" SG_ 2365465854 Valve4RetractPortMeasuredFlow 1;
BA_ "SPN" SG_ 2365465854 Valve4ExtendedPortPressure 1952;
BA_ "SigType" SG_ 2365465854 Valve4ExtendedPortPressure 1;
BA_ "SPN" SG_ 2365465854 Valve4RetractPortPressure 1953;
BA_ "SigType" SG_ 2365465854 Valve4RetractPortPressure 1;
BA_ "SPN" SG_ 2365465854 Valve4ReturnPortPressure 1954;
BA_ "SigType" SG_ 2365465854 Valve4ReturnPortPressure 1;
BA_ "SPN" SG_ 2365465854 Valve4LimitStatus 5168;
BA_ "SPN" SG_ 2365461758 Valve4ExtendedPortEstimatedFlow 1949;
BA_ "SigType" SG_ 2365461758 Valve4ExtendedPortEstimatedFlow 1;
BA_ "SPN" SG_ 2365461758 Valve4RetractPortEstimatedFlow 1950;
BA_ "SigType" SG_ 2365461758 Valve4RetractPortEstimatedFlow 1;
BA_ "SPN" SG_ 2365461758 Valve4ValveState 1951;
BA_ "SPN" SG_ 2365461758 Valve4FailSafeMode 1958;
BA_ "SigType" SG_ 2365461758 Valve4FailSafeMode 4;
BA_ "SPN" SG_ 2365461758 Valve4LimitStatus 5168;
BA_ "SPN" SG_ 2365469950 Valve4PortFlowCmd 1955;
BA_ "SigType" SG_ 2365469950 Valve4PortFlowCmd 1;
BA_ "SPN" SG_ 2365469950 Valve4StateCmd 1956;
BA_ "SPN" SG_ 2365469950 Valve4FailSaveModeCmd 1957;
BA_ "SigType" SG_ 2365469950 Valve4FailSaveModeCmd 4;
BA_ "SPN" SG_ 2365465598 Valve3ExtendedPortMeasuredFlow 1935;
BA_ "SigType" SG_ 2365465598 Valve3ExtendedPortMeasuredFlow 1;
BA_ "SPN" SG_ 2365465598 Valve3RetractPortMeasuredFlow 1936;
BA_ "SigType" SG_ 2365465598 Valve3RetractPortMeasuredFlow 1;
BA_ "SPN" SG_ 2365465598 Valve3ExtendedPortPressure 1940;
BA_ "SigType" SG_ 2365465598 Valve3ExtendedPortPressure 1;
BA_ "SPN" SG_ 2365465598 Valve3RetractPortPressure 1941;
BA_ "SigType" SG_ 2365465598 Valve3RetractPortPressure 1;
BA_ "SPN" SG_ 2365465598 Valve3ReturnPortPressure 1942;
BA_ "SigType" SG_ 2365465598 Valve3ReturnPortPressure 1;
BA_ "SPN" SG_ 2365465598 Valve3LimitStatus 5166;
BA_ "SPN" SG_ 2365461502 Valve3ExtendedPortEstimatedFlow 1937;
BA_ "SigType" SG_ 2365461502 Valve3ExtendedPortEstimatedFlow 1;
BA_ "SPN" SG_ 2365461502 Valve3RetractPortEstimatedFlow 1938;
BA_ "SigType" SG_ 2365461502 Valve3RetractPortEstimatedFlow 1;
BA_ "SPN" SG_ 2365461502 Valve3ValveState 1939;
BA_ "SPN" SG_ 2365461502 Valve3FailSafeMode 1946;
BA_ "SigType" SG_ 2365461502 Valve3FailSafeMode 4;
BA_ "SPN" SG_ 2365461502 Valve3LimitStatus 5166;
BA_ "SPN" SG_ 2365469694 Valve3PortFlowCmd 1943;
BA_ "SigType" SG_ 2365469694 Valve3PortFlowCmd 1;
BA_ "SPN" SG_ 2365469694 Valve3StateCmd 1944;
BA_ "SPN" SG_ 2365469694 Valve3FailSaveModeCmd 1945;
BA_ "SigType" SG_ 2365469694 Valve3FailSaveModeCmd 4;
BA_ "SPN" SG_ 2365465342 Valve2ExtendedPortMeasuredFlow 1923;
BA_ "SigType" SG_ 2365465342 Valve2ExtendedPortMeasuredFlow 1;
BA_ "SPN" SG_ 2365465342 Valve2RetractPortMeasuredFlow 1924;
BA_ "SigType" SG_ 2365465342 Valve2RetractPortMeasuredFlow 1;
BA_ "SPN" SG_ 2365465342 Valve2ExtendedPortPressure 1928;
BA_ "SigType" SG_ 2365465342 Valve2ExtendedPortPressure 1;
BA_ "SPN" SG_ 2365465342 Valve2RetractPortPressure 1929;
BA_ "SigType" SG_ 2365465342 Valve2RetractPortPressure 1;
BA_ "SPN" SG_ 2365465342 Valve2ReturnPortPressure 1930;
BA_ "SigType" SG_ 2365465342 Valve2ReturnPortPressure 1;
BA_ "SPN" SG_ 2365465342 Valve2LimitStatus 5164;
BA_ "SPN" SG_ 2365461246 Valve2ExtendedPortEstimatedFlow 1925;
BA_ "SigType" SG_ 2365461246 Valve2ExtendedPortEstimatedFlow 1;
BA_ "SPN" SG_ 2365461246 Valve2RetractPortEstimatedFlow 1926;
BA_ "SigType" SG_ 2365461246 Valve2RetractPortEstimatedFlow 1;
BA_ "SPN" SG_ 2365461246 Valve2ValveState 1927;
BA_ "SPN" SG_ 2365461246 Valve2FailSafeMode 1934;
BA_ "SigType" SG_ 2365461246 Valve2FailSafeMode 4;
BA_ "SPN" SG_ 2365461246 Valve2LimitStatus 5164;
BA_ "SPN" SG_ 2365469438 Valve2PortFlowCmd 1931;
BA_ "SigType" SG_ 2365469438 Valve2PortFlowCmd 1;
BA_ "SPN" SG_ 2365469438 Valve2StateCmd 1932;
BA_ "SPN" SG_ 2365469438 Valve2FailSaveModeCmd 1933;
BA_ "SigType" SG_ 2365469438 Valve2FailSaveModeCmd 4;
BA_ "SPN" SG_ 2365465086 Valve1ExtendedPortMeasuredFlow 1911;
BA_ "SigType" SG_ 2365465086 Valve1ExtendedPortMeasuredFlow 1;
BA_ "SPN" SG_ 2365465086 Valve1RetractPortMeasuredFlow 1912;
BA_ "SigType" SG_ 2365465086 Valve1RetractPortMeasuredFlow 1;
BA_ "SPN" SG_ 2365465086 Valve1ExtendedPortPressure 1916;
BA_ "SigType" SG_ 2365465086 Valve1ExtendedPortPressure 1;
BA_ "SPN" SG_ 2365465086 Valve1RetractPortPressure 1917;
BA_ "SigType" SG_ 2365465086 Valve1RetractPortPressure 1;
BA_ "SPN" SG_ 2365465086 Valve1ReturnPortPressure 1918;
BA_ "SigType" SG_ 2365465086 Valve1ReturnPortPressure 1;
BA_ "SPN" SG_ 2365465086 Valve1LimitStatus 5162;
BA_ "SPN" SG_ 2365460990 Valve1ExtendedPortEstimatedFlow 1913;
BA_ "SigType" SG_ 2365460990 Valve1ExtendedPortEstimatedFlow 1;
BA_ "SPN" SG_ 2365460990 Valve1RetractPortEstimatedFlow 1914;
BA_ "SigType" SG_ 2365460990 Valve1RetractPortEstimatedFlow 1;
BA_ "SPN" SG_ 2365460990 Valve1ValveState 1915;
BA_ "SPN" SG_ 2365460990 Valve1FailSafeMode 1922;
BA_ "SigType" SG_ 2365460990 Valve1FailSafeMode 4;
BA_ "SPN" SG_ 2365460990 Valve1LimitStatus 5162;
BA_ "SPN" SG_ 2365469182 Valve1PortFlowCmd 1919;
BA_ "SigType" SG_ 2365469182 Valve1PortFlowCmd 1;
BA_ "SPN" SG_ 2365469182 Valve1StateCmd 1920;
BA_ "SigType" SG_ 2365469182 Valve1FailSaveModeCmd 4;
BA_ "SPN" SG_ 2365464830 Valve0ExtendedPortMeasuredFlow 1899;
BA_ "SigType" SG_ 2365464830 Valve0ExtendedPortMeasuredFlow 1;
BA_ "SPN" SG_ 2365464830 Valve0RetractPortMeasuredFlow 1900;
BA_ "SigType" SG_ 2365464830 Valve0RetractPortMeasuredFlow 1;
BA_ "SPN" SG_ 2365464830 Valve0ExtendedPortPressure 1904;
BA_ "SigType" SG_ 2365464830 Valve0ExtendedPortPressure 1;
BA_ "SPN" SG_ 2365464830 Valve0RetractPortPressure 1905;
BA_ "SigType" SG_ 2365464830 Valve0RetractPortPressure 1;
BA_ "SPN" SG_ 2365464830 Valve0ReturnPortPressure 1906;
BA_ "SigType" SG_ 2365464830 Valve0ReturnPortPressure 1;
BA_ "SPN" SG_ 2365464830 Valve0LimitStatus 5160;
BA_ "SPN" SG_ 2365460734 Valve0ExtendedPortEstimatedFlow 1901;
BA_ "SigType" SG_ 2365460734 Valve0ExtendedPortEstimatedFlow 1;
BA_ "SPN" SG_ 2365460734 Valve0RetractPortEstimatedFlow 1902;
BA_ "SigType" SG_ 2365460734 Valve0RetractPortEstimatedFlow 1;
BA_ "SPN" SG_ 2365460734 Valve0ValveState 1903;
BA_ "SPN" SG_ 2365460734 Valve0FailSafeMode 1910;
BA_ "SigType" SG_ 2365460734 Valve0FailSafeMode 4;
BA_ "SPN" SG_ 2365460734 Valve0LimitStatus 5160;
BA_ "SPN" SG_ 2365468926 Valve0PortFlowCmd 1907;
BA_ "SigType" SG_ 2365468926 Valve0PortFlowCmd 1;
BA_ "SPN" SG_ 2365468926 Valve0StateCmd 1908;
BA_ "SPN" SG_ 2365468926 Valve0FailSaveModeCmd 1909;
BA_ "SigType" SG_ 2365468926 Valve0FailSaveModeCmd 4;
BA_ "SPN" SG_ 2365391360 StopAllImplementOperations 5140;
BA_ "SigType" SG_ 2297441790 SpprtVrblTrnsRpttnRtFrAcclrtnSns 5;
BA_ "SPN" SG_ 2297441790 SpprtVrblTrnsRpttnRtFrAcclrtnSns 5353;
BA_ "SAEDocument" SG_ 2297441790 SpprtVrblTrnsRpttnRtFrAcclrtnSns "J1939-71";
BA_ "SigType" SG_ 2297441790 VrtclAcclrtnExRangeFigureOfMerit 5;
BA_ "SPN" SG_ 2297441790 VrtclAcclrtnExRangeFigureOfMerit 5352;
BA_ "SAEDocument" SG_ 2297441790 VrtclAcclrtnExRangeFigureOfMerit "J1939-71";
BA_ "SigType" SG_ 2297441790 LngtdnlAcclrtnExRngFigureOfMerit 5;
BA_ "SPN" SG_ 2297441790 LngtdnlAcclrtnExRngFigureOfMerit 5351;
BA_ "SAEDocument" SG_ 2297441790 LngtdnlAcclrtnExRngFigureOfMerit "J1939-71";
BA_ "SigType" SG_ 2297441790 LtrlAcclrtonExRangeFigureOfMerit 5;
BA_ "SPN" SG_ 2297441790 LtrlAcclrtonExRangeFigureOfMerit 5350;
BA_ "SAEDocument" SG_ 2297441790 LtrlAcclrtonExRangeFigureOfMerit "J1939-71";
BA_ "SigType" SG_ 2297441790 VerticalAccelerationExRange 1;
BA_ "SPN" SG_ 2297441790 VerticalAccelerationExRange 5349;
BA_ "SAEDocument" SG_ 2297441790 VerticalAccelerationExRange "J1939-71";
BA_ "SigType" SG_ 2297441790 LateralAccelerationExRange 1;
BA_ "SPN" SG_ 2297441790 LateralAccelerationExRange 5347;
BA_ "SAEDocument" SG_ 2297441790 LateralAccelerationExRange "J1939-71";
BA_ "SigType" SG_ 2297441790 LongitudinalAccelerationExRange 1;
BA_ "SPN" SG_ 2297441790 LongitudinalAccelerationExRange 5348;
BA_ "SAEDocument" SG_ 2297441790 LongitudinalAccelerationExRange "J1939-71";
BA_ "SigType" SG_ 2566712062 HybridBatteryPackRemainingCharge 1;
BA_ "SPN" SG_ 2566712062 HybridBatteryPackRemainingCharge 5464;
BA_ "SAEDocument" SG_ 2566712062 HybridBatteryPackRemainingCharge "J1939-71";
BA_ "SigType" SG_ 2364549630 RllAndPtchExRngMasurementLatency 1;
BA_ "SPN" SG_ 2364549630 RllAndPtchExRngMasurementLatency 4982;
BA_ "SAEDocument" SG_ 2364549630 RllAndPtchExRngMasurementLatency "J1939-71";
BA_ "SigType" SG_ 2364549630 RollAngleExRangeFigureOfMerit 5;
BA_ "SPN" SG_ 2364549630 RollAngleExRangeFigureOfMerit 4981;
BA_ "SAEDocument" SG_ 2364549630 RollAngleExRangeFigureOfMerit "J1939-71";
BA_ "SigType" SG_ 2364549630 RollAngleExRangeCompensation 5;
BA_ "SPN" SG_ 2364549630 RollAngleExRangeCompensation 4980;
BA_ "SAEDocument" SG_ 2364549630 RollAngleExRangeCompensation "J1939-71";
BA_ "SigType" SG_ 2364549630 PitchAngleExRangeFigureOfMerit 5;
BA_ "SPN" SG_ 2364549630 PitchAngleExRangeFigureOfMerit 4979;
BA_ "SAEDocument" SG_ 2364549630 PitchAngleExRangeFigureOfMerit "J1939-71";
BA_ "SigType" SG_ 2364549630 PitchAngleExRangeCompensation 5;
BA_ "SPN" SG_ 2364549630 PitchAngleExRangeCompensation 4978;
BA_ "SAEDocument" SG_ 2364549630 PitchAngleExRangeCompensation "J1939-71";
BA_ "SPN" SG_ 2364549630 RollAngleExRange 4977;
BA_ "SAEDocument" SG_ 2364549630 RollAngleExRange "J1939-71";
BA_ "SPN" SG_ 2364549630 PitchAngleExRange 4976;
BA_ "SAEDocument" SG_ 2364549630 PitchAngleExRange "J1939-71";
BA_ "SigType" SG_ 2499614462 OccpntClssficationSystem10Status 5;
BA_ "SPN" SG_ 2499614462 OccpntClssficationSystem10Status 4972;
BA_ "SAEDocument" SG_ 2499614462 OccpntClssficationSystem10Status "J1939-71";
BA_ "SigType" SG_ 2499614462 OccpntClssificationSystem9Status 5;
BA_ "SPN" SG_ 2499614462 OccpntClssificationSystem9Status 4971;
BA_ "SAEDocument" SG_ 2499614462 OccpntClssificationSystem9Status "J1939-71";
BA_ "SigType" SG_ 2499614462 OccpntClssificationSystem8Status 5;
BA_ "SPN" SG_ 2499614462 OccpntClssificationSystem8Status 4970;
BA_ "SAEDocument" SG_ 2499614462 OccpntClssificationSystem8Status "J1939-71";
BA_ "SigType" SG_ 2499614462 OccpntClssificationSystem7Status 5;
BA_ "SPN" SG_ 2499614462 OccpntClssificationSystem7Status 4969;
BA_ "SAEDocument" SG_ 2499614462 OccpntClssificationSystem7Status "J1939-71";
BA_ "SigType" SG_ 2499614462 OccpntClssificationSystem6Status 5;
BA_ "SPN" SG_ 2499614462 OccpntClssificationSystem6Status 4968;
BA_ "SAEDocument" SG_ 2499614462 OccpntClssificationSystem6Status "J1939-71";
BA_ "SigType" SG_ 2499614462 OccpntClssificationSystem5Status 5;
BA_ "SPN" SG_ 2499614462 OccpntClssificationSystem5Status 4967;
BA_ "SAEDocument" SG_ 2499614462 OccpntClssificationSystem5Status "J1939-71";
BA_ "SigType" SG_ 2499614462 OccpntClssificationSystem4Status 5;
BA_ "SPN" SG_ 2499614462 OccpntClssificationSystem4Status 4966;
BA_ "SAEDocument" SG_ 2499614462 OccpntClssificationSystem4Status "J1939-71";
BA_ "SigType" SG_ 2499614462 OccpntClssificationSystem3Status 5;
BA_ "SPN" SG_ 2499614462 OccpntClssificationSystem3Status 4965;
BA_ "SAEDocument" SG_ 2499614462 OccpntClssificationSystem3Status "J1939-71";
BA_ "SPN" SG_ 2499614462 PssngrOccpntClssfctnSystemStatus 4964;
BA_ "SAEDocument" SG_ 2499614462 PssngrOccpntClssfctnSystemStatus "J1939-71";
BA_ "SPN" SG_ 2499614462 DrvrOccpntClssfctionSystemStatus 4963;
BA_ "SAEDocument" SG_ 2499614462 DrvrOccpntClssfctionSystemStatus "J1939-71";
BA_ "SPN" SG_ 2560098046 CabNoiseCtrlTuningStatus 5060;
BA_ "SAEDocument" SG_ 2560098046 CabNoiseCtrlTuningStatus "J1939-71";
BA_ "SigType" SG_ 2560098046 CabNoiseCtrlStatus 5;
BA_ "SPN" SG_ 2560098046 CabNoiseCtrlStatus 5059;
BA_ "SAEDocument" SG_ 2560098046 CabNoiseCtrlStatus "J1939-71";
BA_ "SPN" SG_ 2560163582 CabNoiseCtrlTuningState 5058;
BA_ "SAEDocument" SG_ 2560163582 CabNoiseCtrlTuningState "J1939-71";
BA_ "SigType" SG_ 2560163582 CabNoiseCtrlState 5;
BA_ "SPN" SG_ 2560163582 CabNoiseCtrlState 5057;
BA_ "SAEDocument" SG_ 2560163582 CabNoiseCtrlState "J1939-71";
BA_ "SigType" SG_ 2297441534 DropRelayCtrl 5;
BA_ "SPN" SG_ 2297441534 DropRelayCtrl 5403;
BA_ "SAEDocument" SG_ 2297441534 DropRelayCtrl "J1939-71";
BA_ "SigType" SG_ 2297441534 LiftRelayCtrl 5;
BA_ "SPN" SG_ 2297441534 LiftRelayCtrl 5402;
BA_ "SAEDocument" SG_ 2297441534 LiftRelayCtrl "J1939-71";
BA_ "SigType" SG_ 2297441534 MaterialDropActiveStatus 5;
BA_ "SPN" SG_ 2297441534 MaterialDropActiveStatus 5014;
BA_ "SAEDocument" SG_ 2297441534 MaterialDropActiveStatus "J1939-71";
BA_ "SigType" SG_ 2297441534 MaterialLiftActiveStatus 5;
BA_ "SPN" SG_ 2297441534 MaterialLiftActiveStatus 5013;
BA_ "SAEDocument" SG_ 2297441534 MaterialLiftActiveStatus "J1939-71";
BA_ "SigType" SG_ 2297441534 GneratorCurrentBoostActiveStatus 5;
BA_ "SPN" SG_ 2297441534 GneratorCurrentBoostActiveStatus 5012;
BA_ "SAEDocument" SG_ 2297441534 GneratorCurrentBoostActiveStatus "J1939-71";
BA_ "SigType" SG_ 2297441534 MaterialDropSwitch 5;
BA_ "SPN" SG_ 2297441534 MaterialDropSwitch 5011;
BA_ "SAEDocument" SG_ 2297441534 MaterialDropSwitch "J1939-71";
BA_ "SigType" SG_ 2297441534 MaterialLiftSwitch 5;
BA_ "SPN" SG_ 2297441534 MaterialLiftSwitch 5010;
BA_ "SAEDocument" SG_ 2297441534 MaterialLiftSwitch "J1939-71";
BA_ "SPN" SG_ 2297441534 MagnetReverseCurrent 5009;
BA_ "SAEDocument" SG_ 2297441534 MagnetReverseCurrent "J1939-71";
BA_ "SPN" SG_ 2297441534 MagnetForwardCurrent 5008;
BA_ "SAEDocument" SG_ 2297441534 MagnetForwardCurrent "J1939-71";
BA_ "SigType" SG_ 2566722302 GeneratorDutyCycleExceededStatus 5;
BA_ "SPN" SG_ 2566722302 GeneratorDutyCycleExceededStatus 5007;
BA_ "SAEDocument" SG_ 2566722302 GeneratorDutyCycleExceededStatus "J1939-71";
BA_ "SigType" SG_ 2566722302 VoltageMonitorActiveStatus 5;
BA_ "SPN" SG_ 2566722302 VoltageMonitorActiveStatus 5006;
BA_ "SAEDocument" SG_ 2566722302 VoltageMonitorActiveStatus "J1939-71";
BA_ "SigType" SG_ 2566722302 GensetEnableActiveStatus 5;
BA_ "SPN" SG_ 2566722302 GensetEnableActiveStatus 5005;
BA_ "SAEDocument" SG_ 2566722302 GensetEnableActiveStatus "J1939-71";
BA_ "SPN" SG_ 2566722302 ReverseCurrentRangeSetting 5002;
BA_ "SAEDocument" SG_ 2566722302 ReverseCurrentRangeSetting "J1939-71";
BA_ "SigType" SG_ 2566722302 GensetSoftstartActiveStatus 5;
BA_ "SPN" SG_ 2566722302 GensetSoftstartActiveStatus 5004;
BA_ "SAEDocument" SG_ 2566722302 GensetSoftstartActiveStatus "J1939-71";
BA_ "SigType" SG_ 2566722302 Grapple_MagnetSelectionSwitch 5;
BA_ "SPN" SG_ 2566722302 Grapple_MagnetSelectionSwitch 5003;
BA_ "SAEDocument" SG_ 2566722302 Grapple_MagnetSelectionSwitch "J1939-71";
BA_ "SigType" SG_ 2566722302 GnstSystmOtputVoltageRangeStatus 5;
BA_ "SPN" SG_ 2566722302 GnstSystmOtputVoltageRangeStatus 5001;
BA_ "SAEDocument" SG_ 2566722302 GnstSystmOtputVoltageRangeStatus "J1939-71";
BA_ "SigType" SG_ 2566722302 GeneratorOverheatStatus 5;
BA_ "SPN" SG_ 2566722302 GeneratorOverheatStatus 5000;
BA_ "SAEDocument" SG_ 2566722302 GeneratorOverheatStatus "J1939-71";
BA_ "SPN" SG_ 2566722558 MagnetRatedPower 4999;
BA_ "SAEDocument" SG_ 2566722558 MagnetRatedPower "J1939-71";
BA_ "SPN" SG_ 2566722558 MagnetBoostTime 4998;
BA_ "SAEDocument" SG_ 2566722558 MagnetBoostTime "J1939-71";
BA_ "SPN" SG_ 2560032510 LwVltgDscnnctDsiredOperatingMode 5149;
BA_ "SAEDocument" SG_ 2560032510 LwVltgDscnnctDsiredOperatingMode "J1939-71";
BA_ "SigType" SG_ 2566717950 LowVoltageDisconnectTemp 1;
BA_ "SPN" SG_ 2566717950 LowVoltageDisconnectTemp 5148;
BA_ "SAEDocument" SG_ 2566717950 LowVoltageDisconnectTemp "J1939-71";
BA_ "SPN" SG_ 2566717950 LwVltgeDisconnectVoutOutputState 5147;
BA_ "SAEDocument" SG_ 2566717950 LwVltgeDisconnectVoutOutputState "J1939-71";
BA_ "SPN" SG_ 2566717950 LowVoltageDisconnectOutput1State 5146;
BA_ "SAEDocument" SG_ 2566717950 LowVoltageDisconnectOutput1State "J1939-71";
BA_ "SPN" SG_ 2566717950 LowVoltageDisconnectOutput2State 5145;
BA_ "SAEDocument" SG_ 2566717950 LowVoltageDisconnectOutput2State "J1939-71";
BA_ "SPN" SG_ 2566717950 LowVoltageDisconnectOutput3State 5144;
BA_ "SAEDocument" SG_ 2566717950 LowVoltageDisconnectOutput3State "J1939-71";
BA_ "SPN" SG_ 2566717950 LwVltgDscnnctCrrentOperatingMode 5143;
BA_ "SAEDocument" SG_ 2566717950 LwVltgDscnnctCrrentOperatingMode "J1939-71";
BA_ "SigType" SG_ 2566717950 LwVltgDscnnectManualConnectState 4;
BA_ "SPN" SG_ 2566717950 LwVltgDscnnectManualConnectState 5142;
BA_ "SAEDocument" SG_ 2566717950 LwVltgDscnnectManualConnectState "J1939-71";
BA_ "SigType" SG_ 2566717950 LwVltgDscnnctMnalDisconnectState 4;
BA_ "SPN" SG_ 2566717950 LwVltgDscnnctMnalDisconnectState 5141;
BA_ "SAEDocument" SG_ 2566717950 LwVltgDscnnctMnalDisconnectState "J1939-71";
BA_ "SPN" SG_ 2499604222 BldReferenceElevationOffsetRight 5413;
BA_ "SAEDocument" SG_ 2499604222 BldReferenceElevationOffsetRight "J1939-71";
BA_ "SPN" SG_ 2499604222 BldeReferenceElevationOffsetLeft 5412;
BA_ "SAEDocument" SG_ 2499604222 BldeReferenceElevationOffsetLeft "J1939-71";
BA_ "SPN" SG_ 2499604222 BladeElevationDeviationRight 5411;
BA_ "SAEDocument" SG_ 2499604222 BladeElevationDeviationRight "J1939-71";
BA_ "SPN" SG_ 2499604222 BladeElevationDeviationLeft 5410;
BA_ "SAEDocument" SG_ 2499604222 BladeElevationDeviationLeft "J1939-71";
BA_ "SigType" SG_ 2358902526 Joystick3Lamp10Cmd 5;
BA_ "SPN" SG_ 2358902526 Joystick3Lamp10Cmd 4489;
BA_ "SAEDocument" SG_ 2358902526 Joystick3Lamp10Cmd "J1939-71";
BA_ "SigType" SG_ 2358902526 Joystick3Lamp9Cmd 5;
BA_ "SPN" SG_ 2358902526 Joystick3Lamp9Cmd 4488;
BA_ "SAEDocument" SG_ 2358902526 Joystick3Lamp9Cmd "J1939-71";
BA_ "SigType" SG_ 2358902526 Joystick3Lamp8Cmd 5;
BA_ "SPN" SG_ 2358902526 Joystick3Lamp8Cmd 4487;
BA_ "SAEDocument" SG_ 2358902526 Joystick3Lamp8Cmd "J1939-71";
BA_ "SigType" SG_ 2358902526 Joystick3Lamp7Cmd 5;
BA_ "SPN" SG_ 2358902526 Joystick3Lamp7Cmd 4486;
BA_ "SAEDocument" SG_ 2358902526 Joystick3Lamp7Cmd "J1939-71";
BA_ "SigType" SG_ 2358902526 Joystick3Lamp6Cmd 5;
BA_ "SPN" SG_ 2358902526 Joystick3Lamp6Cmd 4485;
BA_ "SAEDocument" SG_ 2358902526 Joystick3Lamp6Cmd "J1939-71";
BA_ "SigType" SG_ 2358902526 Joystick3Lamp5Cmd 5;
BA_ "SPN" SG_ 2358902526 Joystick3Lamp5Cmd 4484;
BA_ "SAEDocument" SG_ 2358902526 Joystick3Lamp5Cmd "J1939-71";
BA_ "SigType" SG_ 2358902526 Joystick3Lamp4Cmd 5;
BA_ "SPN" SG_ 2358902526 Joystick3Lamp4Cmd 4483;
BA_ "SAEDocument" SG_ 2358902526 Joystick3Lamp4Cmd "J1939-71";
BA_ "SigType" SG_ 2358902526 Joystick3Lamp3Cmd 5;
BA_ "SPN" SG_ 2358902526 Joystick3Lamp3Cmd 4482;
BA_ "SAEDocument" SG_ 2358902526 Joystick3Lamp3Cmd "J1939-71";
BA_ "SigType" SG_ 2358902526 Joystick3Lamp2Cmd 5;
BA_ "SPN" SG_ 2358902526 Joystick3Lamp2Cmd 4481;
BA_ "SAEDocument" SG_ 2358902526 Joystick3Lamp2Cmd "J1939-71";
BA_ "SigType" SG_ 2358902526 Joystick3Lamp1Cmd 5;
BA_ "SPN" SG_ 2358902526 Joystick3Lamp1Cmd 4480;
BA_ "SAEDocument" SG_ 2358902526 Joystick3Lamp1Cmd "J1939-71";
BA_ "SigType" SG_ 2358902526 Joystick2Lamp10Cmd 5;
BA_ "SPN" SG_ 2358902526 Joystick2Lamp10Cmd 4479;
BA_ "SAEDocument" SG_ 2358902526 Joystick2Lamp10Cmd "J1939-71";
BA_ "SigType" SG_ 2358902526 Joystick2Lamp9Cmd 5;
BA_ "SPN" SG_ 2358902526 Joystick2Lamp9Cmd 4478;
BA_ "SAEDocument" SG_ 2358902526 Joystick2Lamp9Cmd "J1939-71";
BA_ "SigType" SG_ 2358902526 Joystick2Lamp8Cmd 5;
BA_ "SPN" SG_ 2358902526 Joystick2Lamp8Cmd 4477;
BA_ "SAEDocument" SG_ 2358902526 Joystick2Lamp8Cmd "J1939-71";
BA_ "SigType" SG_ 2358902526 Joystick2Lamp7Cmd 5;
BA_ "SPN" SG_ 2358902526 Joystick2Lamp7Cmd 4476;
BA_ "SAEDocument" SG_ 2358902526 Joystick2Lamp7Cmd "J1939-71";
BA_ "SigType" SG_ 2358902526 Joystick2Lamp6Cmd 5;
BA_ "SPN" SG_ 2358902526 Joystick2Lamp6Cmd 4475;
BA_ "SAEDocument" SG_ 2358902526 Joystick2Lamp6Cmd "J1939-71";
BA_ "SigType" SG_ 2358902526 Joystick2Lamp5Cmd 5;
BA_ "SPN" SG_ 2358902526 Joystick2Lamp5Cmd 4474;
BA_ "SAEDocument" SG_ 2358902526 Joystick2Lamp5Cmd "J1939-71";
BA_ "SigType" SG_ 2358902526 Joystick2Lamp4Cmd 5;
BA_ "SPN" SG_ 2358902526 Joystick2Lamp4Cmd 4473;
BA_ "SAEDocument" SG_ 2358902526 Joystick2Lamp4Cmd "J1939-71";
BA_ "SigType" SG_ 2358902526 Joystick2Lamp3Cmd 5;
BA_ "SPN" SG_ 2358902526 Joystick2Lamp3Cmd 4472;
BA_ "SAEDocument" SG_ 2358902526 Joystick2Lamp3Cmd "J1939-71";
BA_ "SigType" SG_ 2358902526 Joystick2Lamp2Cmd 5;
BA_ "SPN" SG_ 2358902526 Joystick2Lamp2Cmd 4471;
BA_ "SAEDocument" SG_ 2358902526 Joystick2Lamp2Cmd "J1939-71";
BA_ "SigType" SG_ 2358902526 Joystick2Lamp1Cmd 5;
BA_ "SPN" SG_ 2358902526 Joystick2Lamp1Cmd 4470;
BA_ "SAEDocument" SG_ 2358902526 Joystick2Lamp1Cmd "J1939-71";
BA_ "SigType" SG_ 2358902526 Joystick1Lamp10Cmd 5;
BA_ "SPN" SG_ 2358902526 Joystick1Lamp10Cmd 4469;
BA_ "SAEDocument" SG_ 2358902526 Joystick1Lamp10Cmd "J1939-71";
BA_ "SigType" SG_ 2358902526 Joystick1Lamp9Cmd 5;
BA_ "SPN" SG_ 2358902526 Joystick1Lamp9Cmd 4468;
BA_ "SAEDocument" SG_ 2358902526 Joystick1Lamp9Cmd "J1939-71";
BA_ "SigType" SG_ 2358902526 Joystick1Lamp8Cmd 5;
BA_ "SPN" SG_ 2358902526 Joystick1Lamp8Cmd 4467;
BA_ "SAEDocument" SG_ 2358902526 Joystick1Lamp8Cmd "J1939-71";
BA_ "SigType" SG_ 2358902526 Joystick1Lamp7Cmd 5;
BA_ "SPN" SG_ 2358902526 Joystick1Lamp7Cmd 4466;
BA_ "SAEDocument" SG_ 2358902526 Joystick1Lamp7Cmd "J1939-71";
BA_ "SigType" SG_ 2358902526 Joystick1Lamp6Cmd 5;
BA_ "SPN" SG_ 2358902526 Joystick1Lamp6Cmd 4465;
BA_ "SAEDocument" SG_ 2358902526 Joystick1Lamp6Cmd "J1939-71";
BA_ "SigType" SG_ 2358902526 Joystick1Lamp5Cmd 5;
BA_ "SPN" SG_ 2358902526 Joystick1Lamp5Cmd 4464;
BA_ "SAEDocument" SG_ 2358902526 Joystick1Lamp5Cmd "J1939-71";
BA_ "SigType" SG_ 2358902526 Joystick1Lamp4Cmd 5;
BA_ "SPN" SG_ 2358902526 Joystick1Lamp4Cmd 4463;
BA_ "SAEDocument" SG_ 2358902526 Joystick1Lamp4Cmd "J1939-71";
BA_ "SigType" SG_ 2358902526 Joystick1Lamp3Cmd 5;
BA_ "SPN" SG_ 2358902526 Joystick1Lamp3Cmd 4462;
BA_ "SAEDocument" SG_ 2358902526 Joystick1Lamp3Cmd "J1939-71";
BA_ "SigType" SG_ 2358902526 Joystick1Lamp2Cmd 5;
BA_ "SPN" SG_ 2358902526 Joystick1Lamp2Cmd 4461;
BA_ "SAEDocument" SG_ 2358902526 Joystick1Lamp2Cmd "J1939-71";
BA_ "SigType" SG_ 2358902526 Joystick1Lamp1Cmd 5;
BA_ "SPN" SG_ 2358902526 Joystick1Lamp1Cmd 4460;
BA_ "SAEDocument" SG_ 2358902526 Joystick1Lamp1Cmd "J1939-71";
BA_ "SigType" SG_ 2566711550 IntkVlvActtnSystmOlPrss2SlndCtrl 5;
BA_ "SPN" SG_ 2566711550 IntkVlvActtnSystmOlPrss2SlndCtrl 5500;
BA_ "SAEDocument" SG_ 2566711550 IntkVlvActtnSystmOlPrss2SlndCtrl "J1939-71";
BA_ "SigType" SG_ 2566711550 IntkVlvActtnSystmOlPrss1SlndCtrl 5;
BA_ "SPN" SG_ 2566711550 IntkVlvActtnSystmOlPrss1SlndCtrl 5499;
BA_ "SAEDocument" SG_ 2566711550 IntkVlvActtnSystmOlPrss1SlndCtrl "J1939-71";
BA_ "SigType" SG_ 2633832958 SpecialIgnitorLoop90Resistance 1;
BA_ "SPN" SG_ 2633832958 SpecialIgnitorLoop90Resistance 4917;
BA_ "SAEDocument" SG_ 2633832958 SpecialIgnitorLoop90Resistance "J1939-71";
BA_ "SigType" SG_ 2633832958 SpecialIgnitorLoop89Resistance 1;
BA_ "SPN" SG_ 2633832958 SpecialIgnitorLoop89Resistance 4916;
BA_ "SAEDocument" SG_ 2633832958 SpecialIgnitorLoop89Resistance "J1939-71";
BA_ "SigType" SG_ 2633832958 SpecialIgnitorLoop88Resistance 1;
BA_ "SPN" SG_ 2633832958 SpecialIgnitorLoop88Resistance 4915;
BA_ "SAEDocument" SG_ 2633832958 SpecialIgnitorLoop88Resistance "J1939-71";
BA_ "SigType" SG_ 2633832958 SpecialIgnitorLoop87Resistance 1;
BA_ "SPN" SG_ 2633832958 SpecialIgnitorLoop87Resistance 4914;
BA_ "SAEDocument" SG_ 2633832958 SpecialIgnitorLoop87Resistance "J1939-71";
BA_ "SigType" SG_ 2633832958 SpecialIgnitorLoop86Resistance 1;
BA_ "SPN" SG_ 2633832958 SpecialIgnitorLoop86Resistance 4913;
BA_ "SAEDocument" SG_ 2633832958 SpecialIgnitorLoop86Resistance "J1939-71";
BA_ "SigType" SG_ 2633832958 SpecialIgnitorLoop85Resistance 1;
BA_ "SPN" SG_ 2633832958 SpecialIgnitorLoop85Resistance 4912;
BA_ "SAEDocument" SG_ 2633832958 SpecialIgnitorLoop85Resistance "J1939-71";
BA_ "SigType" SG_ 2633832958 SpecialIgnitorLoop84Resistance 1;
BA_ "SPN" SG_ 2633832958 SpecialIgnitorLoop84Resistance 4911;
BA_ "SAEDocument" SG_ 2633832958 SpecialIgnitorLoop84Resistance "J1939-71";
BA_ "SigType" SG_ 2633832958 SpecialIgnitorLoop83Resistance 1;
BA_ "SPN" SG_ 2633832958 SpecialIgnitorLoop83Resistance 4910;
BA_ "SAEDocument" SG_ 2633832958 SpecialIgnitorLoop83Resistance "J1939-71";
BA_ "SigType" SG_ 2633832958 SpecialIgnitorLoop82Resistance 1;
BA_ "SPN" SG_ 2633832958 SpecialIgnitorLoop82Resistance 4909;
BA_ "SAEDocument" SG_ 2633832958 SpecialIgnitorLoop82Resistance "J1939-71";
BA_ "SigType" SG_ 2633832958 SpecialIgnitorLoop81Resistance 1;
BA_ "SPN" SG_ 2633832958 SpecialIgnitorLoop81Resistance 4908;
BA_ "SAEDocument" SG_ 2633832958 SpecialIgnitorLoop81Resistance "J1939-71";
BA_ "SigType" SG_ 2633832958 SpecialIgnitorLoop80Resistance 1;
BA_ "SPN" SG_ 2633832958 SpecialIgnitorLoop80Resistance 4907;
BA_ "SAEDocument" SG_ 2633832958 SpecialIgnitorLoop80Resistance "J1939-71";
BA_ "SigType" SG_ 2633832958 SpecialIgnitorLoop79Resistance 1;
BA_ "SPN" SG_ 2633832958 SpecialIgnitorLoop79Resistance 4906;
BA_ "SAEDocument" SG_ 2633832958 SpecialIgnitorLoop79Resistance "J1939-71";
BA_ "SigType" SG_ 2633832958 SpecialIgnitorLoop78Resistance 1;
BA_ "SPN" SG_ 2633832958 SpecialIgnitorLoop78Resistance 4905;
BA_ "SAEDocument" SG_ 2633832958 SpecialIgnitorLoop78Resistance "J1939-71";
BA_ "SigType" SG_ 2633832958 SpecialIgnitorLoop77Resistance 1;
BA_ "SPN" SG_ 2633832958 SpecialIgnitorLoop77Resistance 4904;
BA_ "SAEDocument" SG_ 2633832958 SpecialIgnitorLoop77Resistance "J1939-71";
BA_ "SigType" SG_ 2633832958 SpecialIgnitorLoop76Resistance 1;
BA_ "SPN" SG_ 2633832958 SpecialIgnitorLoop76Resistance 4903;
BA_ "SAEDocument" SG_ 2633832958 SpecialIgnitorLoop76Resistance "J1939-71";
BA_ "SigType" SG_ 2633832958 SpecialIgnitorLoop75Resistance 1;
BA_ "SPN" SG_ 2633832958 SpecialIgnitorLoop75Resistance 4902;
BA_ "SAEDocument" SG_ 2633832958 SpecialIgnitorLoop75Resistance "J1939-71";
BA_ "SigType" SG_ 2633832958 SpecialIgnitorLoop74Resistance 1;
BA_ "SPN" SG_ 2633832958 SpecialIgnitorLoop74Resistance 4901;
BA_ "SAEDocument" SG_ 2633832958 SpecialIgnitorLoop74Resistance "J1939-71";
BA_ "SigType" SG_ 2633832958 SpecialIgnitorLoop73Resistance 1;
BA_ "SPN" SG_ 2633832958 SpecialIgnitorLoop73Resistance 4900;
BA_ "SAEDocument" SG_ 2633832958 SpecialIgnitorLoop73Resistance "J1939-71";
BA_ "SigType" SG_ 2633832958 SpecialIgnitorLoop72Resistance 1;
BA_ "SPN" SG_ 2633832958 SpecialIgnitorLoop72Resistance 4899;
BA_ "SAEDocument" SG_ 2633832958 SpecialIgnitorLoop72Resistance "J1939-71";
BA_ "SigType" SG_ 2633832958 SpecialIgnitorLoop71Resistance 1;
BA_ "SPN" SG_ 2633832958 SpecialIgnitorLoop71Resistance 4898;
BA_ "SAEDocument" SG_ 2633832958 SpecialIgnitorLoop71Resistance "J1939-71";
BA_ "SigType" SG_ 2633832958 SpecialIgnitorLoop70Resistance 1;
BA_ "SPN" SG_ 2633832958 SpecialIgnitorLoop70Resistance 4897;
BA_ "SAEDocument" SG_ 2633832958 SpecialIgnitorLoop70Resistance "J1939-71";
BA_ "SigType" SG_ 2633832958 SpecialIgnitorLoop69Resistance 1;
BA_ "SPN" SG_ 2633832958 SpecialIgnitorLoop69Resistance 4896;
BA_ "SAEDocument" SG_ 2633832958 SpecialIgnitorLoop69Resistance "J1939-71";
BA_ "SigType" SG_ 2633832958 SpecialIgnitorLoop68Resistance 1;
BA_ "SPN" SG_ 2633832958 SpecialIgnitorLoop68Resistance 4895;
BA_ "SAEDocument" SG_ 2633832958 SpecialIgnitorLoop68Resistance "J1939-71";
BA_ "SigType" SG_ 2633832958 SpecialIgnitorLoop67Resistance 1;
BA_ "SPN" SG_ 2633832958 SpecialIgnitorLoop67Resistance 4894;
BA_ "SAEDocument" SG_ 2633832958 SpecialIgnitorLoop67Resistance "J1939-71";
BA_ "SigType" SG_ 2633832958 SpecialIgnitorLoop66Resistance 1;
BA_ "SPN" SG_ 2633832958 SpecialIgnitorLoop66Resistance 4893;
BA_ "SAEDocument" SG_ 2633832958 SpecialIgnitorLoop66Resistance "J1939-71";
BA_ "SigType" SG_ 2633832958 SpecialIgnitorLoop65Resistance 1;
BA_ "SPN" SG_ 2633832958 SpecialIgnitorLoop65Resistance 4892;
BA_ "SAEDocument" SG_ 2633832958 SpecialIgnitorLoop65Resistance "J1939-71";
BA_ "SigType" SG_ 2633832958 SpecialIgnitorLoop64Resistance 1;
BA_ "SPN" SG_ 2633832958 SpecialIgnitorLoop64Resistance 4891;
BA_ "SAEDocument" SG_ 2633832958 SpecialIgnitorLoop64Resistance "J1939-71";
BA_ "SigType" SG_ 2633832958 SpecialIgnitorLoop63Resistance 1;
BA_ "SPN" SG_ 2633832958 SpecialIgnitorLoop63Resistance 4890;
BA_ "SAEDocument" SG_ 2633832958 SpecialIgnitorLoop63Resistance "J1939-71";
BA_ "SigType" SG_ 2633832958 SpecialIgnitorLoop61Resistance 1;
BA_ "SPN" SG_ 2633832958 SpecialIgnitorLoop61Resistance 4888;
BA_ "SAEDocument" SG_ 2633832958 SpecialIgnitorLoop61Resistance "J1939-71";
BA_ "SigType" SG_ 2633832958 SpecialIgnitorLoop60Resistance 1;
BA_ "SPN" SG_ 2633832958 SpecialIgnitorLoop60Resistance 4887;
BA_ "SAEDocument" SG_ 2633832958 SpecialIgnitorLoop60Resistance "J1939-71";
BA_ "SigType" SG_ 2633832958 SpecialIgnitorLoop59Resistance 1;
BA_ "SPN" SG_ 2633832958 SpecialIgnitorLoop59Resistance 4886;
BA_ "SAEDocument" SG_ 2633832958 SpecialIgnitorLoop59Resistance "J1939-71";
BA_ "SigType" SG_ 2633832958 SpecialIgnitorLoop58Resistance 1;
BA_ "SPN" SG_ 2633832958 SpecialIgnitorLoop58Resistance 4885;
BA_ "SAEDocument" SG_ 2633832958 SpecialIgnitorLoop58Resistance "J1939-71";
BA_ "SigType" SG_ 2633832958 SpecialIgnitorLoop57Resistance 1;
BA_ "SPN" SG_ 2633832958 SpecialIgnitorLoop57Resistance 4884;
BA_ "SAEDocument" SG_ 2633832958 SpecialIgnitorLoop57Resistance "J1939-71";
BA_ "SigType" SG_ 2633832958 SpecialIgnitorLoop56Resistance 1;
BA_ "SPN" SG_ 2633832958 SpecialIgnitorLoop56Resistance 4883;
BA_ "SAEDocument" SG_ 2633832958 SpecialIgnitorLoop56Resistance "J1939-71";
BA_ "SigType" SG_ 2633832958 SpecialIgnitorLoop55Resistance 1;
BA_ "SPN" SG_ 2633832958 SpecialIgnitorLoop55Resistance 4882;
BA_ "SAEDocument" SG_ 2633832958 SpecialIgnitorLoop55Resistance "J1939-71";
BA_ "SigType" SG_ 2633832958 SpecialIgnitorLoop54Resistance 1;
BA_ "SPN" SG_ 2633832958 SpecialIgnitorLoop54Resistance 4881;
BA_ "SAEDocument" SG_ 2633832958 SpecialIgnitorLoop54Resistance "J1939-71";
BA_ "SigType" SG_ 2633832958 SpecialIgnitorLoop53Resistance 1;
BA_ "SPN" SG_ 2633832958 SpecialIgnitorLoop53Resistance 4880;
BA_ "SAEDocument" SG_ 2633832958 SpecialIgnitorLoop53Resistance "J1939-71";
BA_ "SigType" SG_ 2633832958 SpecialIgnitorLoop52Resistance 1;
BA_ "SPN" SG_ 2633832958 SpecialIgnitorLoop52Resistance 4879;
BA_ "SAEDocument" SG_ 2633832958 SpecialIgnitorLoop52Resistance "J1939-71";
BA_ "SigType" SG_ 2633832958 SpecialIgnitorLoop51Resistance 1;
BA_ "SPN" SG_ 2633832958 SpecialIgnitorLoop51Resistance 4878;
BA_ "SAEDocument" SG_ 2633832958 SpecialIgnitorLoop51Resistance "J1939-71";
BA_ "SigType" SG_ 2633832958 SpecialIgnitorLoop50Resistance 1;
BA_ "SPN" SG_ 2633832958 SpecialIgnitorLoop50Resistance 4877;
BA_ "SAEDocument" SG_ 2633832958 SpecialIgnitorLoop50Resistance "J1939-71";
BA_ "SigType" SG_ 2633832958 SpecialIgnitorLoop49Resistance 1;
BA_ "SPN" SG_ 2633832958 SpecialIgnitorLoop49Resistance 4876;
BA_ "SAEDocument" SG_ 2633832958 SpecialIgnitorLoop49Resistance "J1939-71";
BA_ "SigType" SG_ 2633832958 SpecialIgnitorLoop48Resistance 1;
BA_ "SPN" SG_ 2633832958 SpecialIgnitorLoop48Resistance 4875;
BA_ "SAEDocument" SG_ 2633832958 SpecialIgnitorLoop48Resistance "J1939-71";
BA_ "SigType" SG_ 2633832958 SpecialIgnitorLoop47Resistance 1;
BA_ "SPN" SG_ 2633832958 SpecialIgnitorLoop47Resistance 4874;
BA_ "SAEDocument" SG_ 2633832958 SpecialIgnitorLoop47Resistance "J1939-71";
BA_ "SigType" SG_ 2633832958 SpecialIgnitorLoop46Resistance 1;
BA_ "SPN" SG_ 2633832958 SpecialIgnitorLoop46Resistance 4873;
BA_ "SAEDocument" SG_ 2633832958 SpecialIgnitorLoop46Resistance "J1939-71";
BA_ "SigType" SG_ 2633832958 SpecialIgnitorLoop45Resistance 1;
BA_ "SPN" SG_ 2633832958 SpecialIgnitorLoop45Resistance 4872;
BA_ "SAEDocument" SG_ 2633832958 SpecialIgnitorLoop45Resistance "J1939-71";
BA_ "SigType" SG_ 2633832958 SpecialIgnitorLoop44Resistance 1;
BA_ "SPN" SG_ 2633832958 SpecialIgnitorLoop44Resistance 4871;
BA_ "SAEDocument" SG_ 2633832958 SpecialIgnitorLoop44Resistance "J1939-71";
BA_ "SigType" SG_ 2633832958 SpecialIgnitorLoop43Resistance 1;
BA_ "SPN" SG_ 2633832958 SpecialIgnitorLoop43Resistance 4870;
BA_ "SAEDocument" SG_ 2633832958 SpecialIgnitorLoop43Resistance "J1939-71";
BA_ "SigType" SG_ 2633832958 SpecialIgnitorLoop42Resistance 1;
BA_ "SPN" SG_ 2633832958 SpecialIgnitorLoop42Resistance 4869;
BA_ "SAEDocument" SG_ 2633832958 SpecialIgnitorLoop42Resistance "J1939-71";
BA_ "SigType" SG_ 2633832958 SpecialIgnitorLoop41Resistance 1;
BA_ "SPN" SG_ 2633832958 SpecialIgnitorLoop41Resistance 4868;
BA_ "SAEDocument" SG_ 2633832958 SpecialIgnitorLoop41Resistance "J1939-71";
BA_ "SigType" SG_ 2633832958 SpecialIgnitorLoop40Resistance 1;
BA_ "SPN" SG_ 2633832958 SpecialIgnitorLoop40Resistance 4867;
BA_ "SAEDocument" SG_ 2633832958 SpecialIgnitorLoop40Resistance "J1939-71";
BA_ "SigType" SG_ 2633832958 SpecialIgnitorLoop39Resistance 1;
BA_ "SPN" SG_ 2633832958 SpecialIgnitorLoop39Resistance 4866;
BA_ "SAEDocument" SG_ 2633832958 SpecialIgnitorLoop39Resistance "J1939-71";
BA_ "SigType" SG_ 2633832958 SpecialIgnitorLoop38Resistance 1;
BA_ "SPN" SG_ 2633832958 SpecialIgnitorLoop38Resistance 4865;
BA_ "SAEDocument" SG_ 2633832958 SpecialIgnitorLoop38Resistance "J1939-71";
BA_ "SigType" SG_ 2633832958 SpecialIgnitorLoop37Resistance 1;
BA_ "SPN" SG_ 2633832958 SpecialIgnitorLoop37Resistance 4864;
BA_ "SAEDocument" SG_ 2633832958 SpecialIgnitorLoop37Resistance "J1939-71";
BA_ "SigType" SG_ 2633832958 SpecialIgnitorLoop36Resistance 1;
BA_ "SPN" SG_ 2633832958 SpecialIgnitorLoop36Resistance 4863;
BA_ "SAEDocument" SG_ 2633832958 SpecialIgnitorLoop36Resistance "J1939-71";
BA_ "SigType" SG_ 2633832958 SpecialIgnitorLoop35Resistance 1;
BA_ "SPN" SG_ 2633832958 SpecialIgnitorLoop35Resistance 4862;
BA_ "SAEDocument" SG_ 2633832958 SpecialIgnitorLoop35Resistance "J1939-71";
BA_ "SigType" SG_ 2633832958 SpecialIgnitorLoop34Resistance 1;
BA_ "SPN" SG_ 2633832958 SpecialIgnitorLoop34Resistance 4861;
BA_ "SAEDocument" SG_ 2633832958 SpecialIgnitorLoop34Resistance "J1939-71";
BA_ "SigType" SG_ 2633832958 SpecialIgnitorLoop33Resistance 1;
BA_ "SPN" SG_ 2633832958 SpecialIgnitorLoop33Resistance 4860;
BA_ "SAEDocument" SG_ 2633832958 SpecialIgnitorLoop33Resistance "J1939-71";
BA_ "SigType" SG_ 2633832958 SpecialIgnitorLoop32Resistance 1;
BA_ "SPN" SG_ 2633832958 SpecialIgnitorLoop32Resistance 4859;
BA_ "SAEDocument" SG_ 2633832958 SpecialIgnitorLoop32Resistance "J1939-71";
BA_ "SigType" SG_ 2633832958 SpecialIgnitorLoop31Resistance 1;
BA_ "SPN" SG_ 2633832958 SpecialIgnitorLoop31Resistance 4858;
BA_ "SAEDocument" SG_ 2633832958 SpecialIgnitorLoop31Resistance "J1939-71";
BA_ "SigType" SG_ 2633832958 SpecialIgnitorLoop30Resistance 1;
BA_ "SPN" SG_ 2633832958 SpecialIgnitorLoop30Resistance 4857;
BA_ "SAEDocument" SG_ 2633832958 SpecialIgnitorLoop30Resistance "J1939-71";
BA_ "SigType" SG_ 2633832958 SpecialIgnitorLoop29Resistance 1;
BA_ "SPN" SG_ 2633832958 SpecialIgnitorLoop29Resistance 4856;
BA_ "SAEDocument" SG_ 2633832958 SpecialIgnitorLoop29Resistance "J1939-71";
BA_ "SigType" SG_ 2633832958 SpecialIgnitorLoop28Resistance 1;
BA_ "SPN" SG_ 2633832958 SpecialIgnitorLoop28Resistance 4855;
BA_ "SAEDocument" SG_ 2633832958 SpecialIgnitorLoop28Resistance "J1939-71";
BA_ "SigType" SG_ 2633832958 SpecialIgnitorLoop27Resistance 1;
BA_ "SPN" SG_ 2633832958 SpecialIgnitorLoop27Resistance 4854;
BA_ "SAEDocument" SG_ 2633832958 SpecialIgnitorLoop27Resistance "J1939-71";
BA_ "SigType" SG_ 2633832958 SpecialIgnitorLoop26Resistance 1;
BA_ "SPN" SG_ 2633832958 SpecialIgnitorLoop26Resistance 4853;
BA_ "SAEDocument" SG_ 2633832958 SpecialIgnitorLoop26Resistance "J1939-71";
BA_ "SigType" SG_ 2633832958 SpecialIgnitorLoop25Resistance 1;
BA_ "SPN" SG_ 2633832958 SpecialIgnitorLoop25Resistance 4852;
BA_ "SAEDocument" SG_ 2633832958 SpecialIgnitorLoop25Resistance "J1939-71";
BA_ "SigType" SG_ 2633832958 SpecialIgnitorLoop24Resistance 1;
BA_ "SPN" SG_ 2633832958 SpecialIgnitorLoop24Resistance 4851;
BA_ "SAEDocument" SG_ 2633832958 SpecialIgnitorLoop24Resistance "J1939-71";
BA_ "SigType" SG_ 2633832958 SpecialIgnitorLoop23Resistance 1;
BA_ "SPN" SG_ 2633832958 SpecialIgnitorLoop23Resistance 4850;
BA_ "SAEDocument" SG_ 2633832958 SpecialIgnitorLoop23Resistance "J1939-71";
BA_ "SigType" SG_ 2633832958 SpecialIgnitorLoop22Resistance 1;
BA_ "SPN" SG_ 2633832958 SpecialIgnitorLoop22Resistance 4849;
BA_ "SAEDocument" SG_ 2633832958 SpecialIgnitorLoop22Resistance "J1939-71";
BA_ "SigType" SG_ 2633832958 SpecialIgnitorLoop21Resistance 1;
BA_ "SPN" SG_ 2633832958 SpecialIgnitorLoop21Resistance 4848;
BA_ "SAEDocument" SG_ 2633832958 SpecialIgnitorLoop21Resistance "J1939-71";
BA_ "SigType" SG_ 2633832958 SpecialIgnitorLoop20Resistance 1;
BA_ "SPN" SG_ 2633832958 SpecialIgnitorLoop20Resistance 4847;
BA_ "SAEDocument" SG_ 2633832958 SpecialIgnitorLoop20Resistance "J1939-71";
BA_ "SigType" SG_ 2633832958 SpecialIgnitorLoop19Resistance 1;
BA_ "SPN" SG_ 2633832958 SpecialIgnitorLoop19Resistance 4846;
BA_ "SAEDocument" SG_ 2633832958 SpecialIgnitorLoop19Resistance "J1939-71";
BA_ "SigType" SG_ 2633832958 SpecialIgnitorLoop18Resistance 1;
BA_ "SPN" SG_ 2633832958 SpecialIgnitorLoop18Resistance 4845;
BA_ "SAEDocument" SG_ 2633832958 SpecialIgnitorLoop18Resistance "J1939-71";
BA_ "SigType" SG_ 2633832958 SpecialIgnitorLoop17Resistance 1;
BA_ "SPN" SG_ 2633832958 SpecialIgnitorLoop17Resistance 4844;
BA_ "SAEDocument" SG_ 2633832958 SpecialIgnitorLoop17Resistance "J1939-71";
BA_ "SigType" SG_ 2633832958 SpecialIgnitorLoop16Resistance 1;
BA_ "SPN" SG_ 2633832958 SpecialIgnitorLoop16Resistance 4843;
BA_ "SAEDocument" SG_ 2633832958 SpecialIgnitorLoop16Resistance "J1939-71";
BA_ "SigType" SG_ 2633832958 SpecialIgnitorLoop15Resistance 1;
BA_ "SPN" SG_ 2633832958 SpecialIgnitorLoop15Resistance 4842;
BA_ "SAEDocument" SG_ 2633832958 SpecialIgnitorLoop15Resistance "J1939-71";
BA_ "SigType" SG_ 2633832958 SpecialIgnitorLoop14Resistance 1;
BA_ "SPN" SG_ 2633832958 SpecialIgnitorLoop14Resistance 4841;
BA_ "SAEDocument" SG_ 2633832958 SpecialIgnitorLoop14Resistance "J1939-71";
BA_ "SigType" SG_ 2633832958 SpecialIgnitorLoop13Resistance 1;
BA_ "SPN" SG_ 2633832958 SpecialIgnitorLoop13Resistance 4840;
BA_ "SAEDocument" SG_ 2633832958 SpecialIgnitorLoop13Resistance "J1939-71";
BA_ "SigType" SG_ 2633832958 SpecialIgnitorLoop12Resistance 1;
BA_ "SPN" SG_ 2633832958 SpecialIgnitorLoop12Resistance 4839;
BA_ "SAEDocument" SG_ 2633832958 SpecialIgnitorLoop12Resistance "J1939-71";
BA_ "SigType" SG_ 2633832958 SpecialIgnitorLoop11Resistance 1;
BA_ "SPN" SG_ 2633832958 SpecialIgnitorLoop11Resistance 4838;
BA_ "SAEDocument" SG_ 2633832958 SpecialIgnitorLoop11Resistance "J1939-71";
BA_ "SigType" SG_ 2633832958 SpecialIgnitorLoop10Resistance 1;
BA_ "SPN" SG_ 2633832958 SpecialIgnitorLoop10Resistance 4837;
BA_ "SAEDocument" SG_ 2633832958 SpecialIgnitorLoop10Resistance "J1939-71";
BA_ "SigType" SG_ 2633832958 SpecialIgnitorLoop9Resistance 1;
BA_ "SPN" SG_ 2633832958 SpecialIgnitorLoop9Resistance 4836;
BA_ "SAEDocument" SG_ 2633832958 SpecialIgnitorLoop9Resistance "J1939-71";
BA_ "SigType" SG_ 2633832958 SpecialIgnitorLoop8Resistance 1;
BA_ "SPN" SG_ 2633832958 SpecialIgnitorLoop8Resistance 4835;
BA_ "SAEDocument" SG_ 2633832958 SpecialIgnitorLoop8Resistance "J1939-71";
BA_ "SigType" SG_ 2633832958 SpecialIgnitorLoop7Resistance 1;
BA_ "SPN" SG_ 2633832958 SpecialIgnitorLoop7Resistance 4834;
BA_ "SAEDocument" SG_ 2633832958 SpecialIgnitorLoop7Resistance "J1939-71";
BA_ "SigType" SG_ 2633832958 SpecialIgnitorLoop6Resistance 1;
BA_ "SPN" SG_ 2633832958 SpecialIgnitorLoop6Resistance 4833;
BA_ "SAEDocument" SG_ 2633832958 SpecialIgnitorLoop6Resistance "J1939-71";
BA_ "SigType" SG_ 2633832958 SpecialIgnitorLoop5Resistance 1;
BA_ "SPN" SG_ 2633832958 SpecialIgnitorLoop5Resistance 4832;
BA_ "SAEDocument" SG_ 2633832958 SpecialIgnitorLoop5Resistance "J1939-71";
BA_ "SigType" SG_ 2633832958 SpecialIgnitorLoop4Resistance 1;
BA_ "SPN" SG_ 2633832958 SpecialIgnitorLoop4Resistance 4831;
BA_ "SAEDocument" SG_ 2633832958 SpecialIgnitorLoop4Resistance "J1939-71";
BA_ "SigType" SG_ 2633832958 SpecialIgnitorLoop3Resistance 1;
BA_ "SPN" SG_ 2633832958 SpecialIgnitorLoop3Resistance 4830;
BA_ "SAEDocument" SG_ 2633832958 SpecialIgnitorLoop3Resistance "J1939-71";
BA_ "SigType" SG_ 2633832958 SpecialIgnitorLoop2Resistance 1;
BA_ "SPN" SG_ 2633832958 SpecialIgnitorLoop2Resistance 4829;
BA_ "SAEDocument" SG_ 2633832958 SpecialIgnitorLoop2Resistance "J1939-71";
BA_ "SigType" SG_ 2633832958 SpecialIgnitorLoop1Resistance 1;
BA_ "SPN" SG_ 2633832958 SpecialIgnitorLoop1Resistance 4828;
BA_ "SAEDocument" SG_ 2633832958 SpecialIgnitorLoop1Resistance "J1939-71";
BA_ "SigType" SG_ 2633832958 SdBagIgnitorLoop2RightResistance 1;
BA_ "SPN" SG_ 2633832958 SdBagIgnitorLoop2RightResistance 4827;
BA_ "SAEDocument" SG_ 2633832958 SdBagIgnitorLoop2RightResistance "J1939-71";
BA_ "SigType" SG_ 2633832958 SdBagIgnitorLoop1RightResistance 1;
BA_ "SPN" SG_ 2633832958 SdBagIgnitorLoop1RightResistance 4826;
BA_ "SAEDocument" SG_ 2633832958 SdBagIgnitorLoop1RightResistance "J1939-71";
BA_ "SigType" SG_ 2633832958 SdeBagIgnitorLoop2LeftResistance 1;
BA_ "SPN" SG_ 2633832958 SdeBagIgnitorLoop2LeftResistance 4825;
BA_ "SAEDocument" SG_ 2633832958 SdeBagIgnitorLoop2LeftResistance "J1939-71";
BA_ "SigType" SG_ 2633832958 SdeBagIgnitorLoop1LeftResistance 1;
BA_ "SPN" SG_ 2633832958 SdeBagIgnitorLoop1LeftResistance 4824;
BA_ "SAEDocument" SG_ 2633832958 SdeBagIgnitorLoop1LeftResistance "J1939-71";
BA_ "SigType" SG_ 2633832958 PssngrBltTnsnrIgntrLopResistance 1;
BA_ "SPN" SG_ 2633832958 PssngrBltTnsnrIgntrLopResistance 4823;
BA_ "SAEDocument" SG_ 2633832958 PssngrBltTnsnrIgntrLopResistance "J1939-71";
BA_ "SigType" SG_ 2633832958 DrvrBltTnsnrIgntorLoopResistance 1;
BA_ "SPN" SG_ 2633832958 DrvrBltTnsnrIgntorLoopResistance 4822;
BA_ "SAEDocument" SG_ 2633832958 DrvrBltTnsnrIgntorLoopResistance "J1939-71";
BA_ "SigType" SG_ 2633832958 PssngrArbgIgntrLp2ndStgRsistance 1;
BA_ "SPN" SG_ 2633832958 PssngrArbgIgntrLp2ndStgRsistance 4821;
BA_ "SAEDocument" SG_ 2633832958 PssngrArbgIgntrLp2ndStgRsistance "J1939-71";
BA_ "SigType" SG_ 2633832958 DrvrArbgIgntrLp2ndStgeResistance 1;
BA_ "SPN" SG_ 2633832958 DrvrArbgIgntrLp2ndStgeResistance 4820;
BA_ "SAEDocument" SG_ 2633832958 DrvrArbgIgntrLp2ndStgeResistance "J1939-71";
BA_ "SigType" SG_ 2633832958 PssngrArbgIgntrLp1stStgRsistance 1;
BA_ "SPN" SG_ 2633832958 PssngrArbgIgntrLp1stStgRsistance 4819;
BA_ "SAEDocument" SG_ 2633832958 PssngrArbgIgntrLp1stStgRsistance "J1939-71";
BA_ "SigType" SG_ 2633832958 DrvrArbgIgntrLp1stStgeResistance 1;
BA_ "SPN" SG_ 2633832958 DrvrArbgIgntrLp1stStgeResistance 4818;
BA_ "SAEDocument" SG_ 2633832958 DrvrArbgIgntrLp1stStgeResistance "J1939-71";
BA_ "SigType" SG_ 2566719998 HighResolutionEngTotalFuelUsed 1;
BA_ "SPN" SG_ 2566719998 HighResolutionEngTotalFuelUsed 5054;
BA_ "SAEDocument" SG_ 2566719998 HighResolutionEngTotalFuelUsed "J1939-71";
BA_ "SigType" SG_ 2566719998 HighResolutionEngTripFuel 1;
BA_ "SPN" SG_ 2566719998 HighResolutionEngTripFuel 5053;
BA_ "SAEDocument" SG_ 2566719998 HighResolutionEngTripFuel "J1939-71";
BA_ "SPN" SG_ 2565877502 EngTurboWastegateActuator2Cmd 5387;
BA_ "SAEDocument" SG_ 2565877502 EngTurboWastegateActuator2Cmd "J1939-71";
BA_ "SPN" SG_ 2565877502 EngTurboWastegateActuator1Cmd 5386;
BA_ "SAEDocument" SG_ 2565877502 EngTurboWastegateActuator1Cmd "J1939-71";
BA_ "SPN" SG_ 2566713854 EngTrbWstgtActtr2OperationStatus 5452;
BA_ "SAEDocument" SG_ 2566713854 EngTrbWstgtActtr2OperationStatus "J1939-71";
BA_ "SPN" SG_ 2566713854 EngTrbWstgtActtr1OperationStatus 5451;
BA_ "SAEDocument" SG_ 2566713854 EngTrbWstgtActtr1OperationStatus "J1939-71";
BA_ "SPN" SG_ 2566713854 EngTrbWstgateActuator2TempStatus 5385;
BA_ "SAEDocument" SG_ 2566713854 EngTrbWstgateActuator2TempStatus "J1939-71";
BA_ "SPN" SG_ 2566713854 EngTrbWstgtActtor2PreliminaryFMI 5384;
BA_ "SAEDocument" SG_ 2566713854 EngTrbWstgtActtor2PreliminaryFMI "J1939-71";
BA_ "SPN" SG_ 2566714366 EngTrbCmprssrBypssActtr2OprtnStt 5450;
BA_ "SAEDocument" SG_ 2566714366 EngTrbCmprssrBypssActtr2OprtnStt "J1939-71";
BA_ "SPN" SG_ 2566714366 EngTrbCmprssrBypssActtr1OprtnStt 5449;
BA_ "SAEDocument" SG_ 2566714366 EngTrbCmprssrBypssActtr1OprtnStt "J1939-71";
BA_ "SPN" SG_ 2566714366 EngTrbCmprssrBypssActtr2TmpSttus 5391;
BA_ "SAEDocument" SG_ 2566714366 EngTrbCmprssrBypssActtr2TmpSttus "J1939-71";
BA_ "SPN" SG_ 2566714366 EngTrbCmprssrBypssActtr2PrlmnryF 5390;
BA_ "SAEDocument" SG_ 2566714366 EngTrbCmprssrBypssActtr2PrlmnryF "J1939-71";
BA_ "SPN" SG_ 2566714366 EngDsrdTrbCmprssrBypssActtor2Pos 5389;
BA_ "SAEDocument" SG_ 2566714366 EngDsrdTrbCmprssrBypssActtor2Pos "J1939-71";
BA_ "SigType" SG_ 2566714366 EngTrbCmprssorBypassActuator2Pos 1;
BA_ "SPN" SG_ 2566714366 EngTrbCmprssorBypassActuator2Pos 5388;
BA_ "SAEDocument" SG_ 2566714366 EngTrbCmprssorBypassActuator2Pos "J1939-71";
VAL_ 2628452094 FSClientCommand 2 "VSVolumeStatusRequest" 1 "CMGetFileServerProperties" 64 "VHVolumeInitialization" 52 "FHGetFileDateTime" 17 "DHChangeCurrentDirectory" 51 "FHSetFileAttributes" 50 "FHGetFileAttributes" 49 "FHDeleteFile" 48 "FHMoveFile" 36 "FACloseFile" 35 "FAWriteFile" 34 "FAReadFile" 33 "FASeekFile" 32 "FAOpenFile" 16 "DHGetCurrentDirectory" 0 "CMConnectionMaintenance" ;
VAL_ 2628452094 CM_VersionNumber 255 "CompliantToVersion2AndPrior" 3 "FirstPublishedEditionAndAmd1OfIS" 2 "FirstPublishedEditionOfIS" 1 "FDIS" 0 "DIS" ;
VAL_ 2628452094 VS_ReportVolumeUsedByClient 1 "ReportVolumeInUseByClient" 0 "ReportVolumeNotInUseByClient" ;
VAL_ 2628452094 VS_RequestVolumeToPrepareForRemo 1 "RequestVolumeToPrepareForRemoval" ;
VAL_ 2628452094 DF_DeleteMode 1 "'copy' mode is set" 0 "'copy' mode is not set" ;
VAL_ 2628452094 MF_MoveModeCopy 1 "'copy' mode is set" 0 "'copy' mode is not set" ;
VAL_ 2628452094 OF_FlagReadWrite 3 "Open directory for reading" 2 "Open file for reading & writing" 1 "Open file for writing only" 0 "Open file for reading only" ;
VAL_ 2628452094 SET_ATTR_ReadOnly 3 "Leave 'read-only' attribute" 2 "Reserved" 1 "Set 'read-only' attribute" 0 "Clear 'read-only' attribute" ;
VAL_ 2628452094 DF_DeleteModeForce 1 "'force' mode is set" 0 "'force' mode is not set" ;
VAL_ 2628452094 MF_MoveModeForce 1 "'force' mode is set" 0 "'force' mode is not set" ;
VAL_ 2628452094 DF_DeleteModeRecursive 1 "'recursive' mode is set" 0 "'recursive' mode is not set" ;
VAL_ 2628452094 MF_MoveModeRecursive 1 "'recursive' mode is set" 0 "'recursive' mode is not set" ;
VAL_ 2628452094 OF_FlagCreateNew 1 "Create new file if not existing" 0 "Open an existing file" ;
VAL_ 2628452094 SET_ATTR_Hidden 3 "Leave 'hidden' attribute" 2 "Reserved" 1 "Set 'hidden' attribute" 0 "Clear 'hidden' attribute" ;
VAL_ 2628452094 OF_FlagAppend 1 "Open file for appending data" 0 "Open file for random access" ;
VAL_ 2628452094 OF_FlagExclusiveAccess 1 "Open file with exclusive access" 0 "Open file for shared read access" ;
VAL_ 2628452094 SF_PositionMode 2 "From the end of the file" 1 "From the current pointer pos" 0 "From the beginning of the file" ;
VAL_ 2628452094 RF_ReportHiddenFiles 255 "NotAvailable" 1 "ReportHiddenFiles" 0 "DoNotReportHiddenFiles" ;
VAL_ 2365474046 FrontPTOEngagementRqStatus 3 "Not available" 2 "Error" 1 "Control Override" 0 "External Request accepted" ;
VAL_ 2365474046 FrontPTOEconomyMode 0 "PTOEconomyModeIsDisengaged" 1 "PTOEconomyModeIsEngaged" 2 "ErrorIndication" 3 "NotAvailable" ;
VAL_ 2365474046 FrontPTOMode 0 "PTOModeIs540" 1 "PTOModeIs1000" 2 "ErrorIndication" 3 "NotAvailable" ;
VAL_ 2365474046 FrontPTOEngagement 0 "PTODisengaged" 1 "PTOEngaged" 2 "ErrorIndication" 3 "NotAvailable" ;
VAL_ 2365474046 FrontPTOShaftSpeedLimitStatus 7 "Not available" 6 "Non-recoverable Fault" 5 "Reserver" 4 "Reserved" 3 "Limited Low" 2 "Limited High" 1 "Operator Limited" 0 "Not limited" ;
VAL_ 2365474046 FrontPTOEconomyModeRqStatus 3 "Not available" 2 "Error" 1 "Control Override" 0 "External Request accepted" ;
VAL_ 2365474046 FrontPTOModeRqStatus 3 "Not available" 2 "Error" 1 "Control Override" 0 "External Request accepted" ;
VAL_ 2365474558 FrontHitchPositionLimitStatus 7 "Not available" 6 "Non-recoverable Fault" 5 "Reserver" 4 "Reserved" 3 "Limited Low" 2 "Limited High" 1 "Operator Limited" 0 "Not limited" ;
VAL_ 2365474558 FrontHitchInWorkIndication 0 "HitchPositionIsOutOfWork" 1 "HitchPositionIsInWorl" 2 "ErrorIndication" 3 "NotAvailable" ;
VAL_ 2563243774 SequenceNumber 255 "NoSequenceAvailable" ;
VAL_ 2563309310 ConnectionAbortReason 7 "AnyOtherError" 6 "DuplicateSequenceNumber" 5 "BadSequenceNumber" 4 "UnexpectedDataTransferPacket" 3 "Timeout_CloseSession" 2 "NoFreeSystemResources" 1 "AlreadyInConnManagedSession" ;
VAL_ 2563309310 ControlByte 24 "EAbort" 23 "EEoMACK" 22 "EDPO" 21 "ECTS" 20 "ERTS" 255 "EAbort" ;
VAL_ 2563309310 PGNumber 255 "NotAvailable" ;
VAL_ 2566704384 DriveStrategyRequestState 3 "Not available/Not Installed " 2 "Error indication " 1 "Control override (most recent external request ignored)" 0 "External Request Accepted. No subsequent operator intervention" ;
VAL_ 2566704384 DriveStrategyPriority4 255 "Not available/Don't care " 254 "Error or reserved" 253 "Requested mode not supported " 6 "Enable maximum electric power control" 5 "Enable maximum hydraulic power control" 4 "Enable engine economy control " 3 "Enable minimum engine speed control" 2 "Enable wheel speed/PTO speed ratio control" 1 "Enable constant PTO speed control" 0 "Enable maximum draft power control " ;
VAL_ 2566704384 DriveStrategyPriority3 255 "Not available/Don't care " 254 "Error or reserved" 253 "Requested mode not supported " 6 "Enable maximum electric power control" 5 "Enable maximum hydraulic power control" 4 "Enable engine economy control " 3 "Enable minimum engine speed control" 2 "Enable wheel speed/PTO speed ratio control" 1 "Enable constant PTO speed control" 0 "Enable maximum draft power control " ;
VAL_ 2566704384 DriveStrategyPriority2 255 "Not available/Don't care " 254 "Error or reserved" 253 "Requested mode not supported " 6 "Enable maximum electric power control" 5 "Enable maximum hydraulic power control" 4 "Enable engine economy control " 3 "Enable minimum engine speed control" 2 "Enable wheel speed/PTO speed ratio control" 1 "Enable constant PTO speed control" 0 "Enable maximum draft power control " ;
VAL_ 2566704384 DriveStrategyPriority1 255 "Not available/Don't care " 254 "Error or reserved" 253 "Requested mode not supported " 6 "Enable maximum electric power control" 5 "Enable maximum hydraulic power control" 4 "Enable engine economy control " 3 "Enable minimum engine speed control" 2 "Enable wheel speed/PTO speed ratio control" 1 "Enable constant PTO speed control" 0 "Enable maximum draft power control " ;
VAL_ 2566704384 DriveStrategyExitReason 63 "Not available (parameter not supported) " 62 "Error " 22 "Vehicle transmission gear does not allow remote commands" 9 "Function fault " 8 "Operator control fault" 7 "Function not calibrated " 6 "Remote command out of range/invalid " 5 "Remote command timeout" 4 "Operator control not in valid position" 3 "Operator override of function " 2 "Implement released control of function " 1 "Operator presence not detected " 0 "No reason/all clear " ;
VAL_ 2365378048 RestoreOpDriveStratSetReq 3 "Not available " 2 "Error indication " 1 "Restore Operator Drive Strategy Setting " 0 "No Request (sent when implement does not want setting restored) " ;
VAL_ 2365378048 DriveStrategyPriority4Req 255 "Not available/Don't care " 254 "Error or reserved" 6 "Enable maximum electric power control" 5 "Enable maximum hydraulic power control" 4 "Enable engine economy control " 3 "Enable minimum engine speed control" 2 "Enable wheel speed/PTO speed ratio control" 1 "Enable constant PTO speed control" 0 "Enable maximum draft power control " ;
VAL_ 2365378048 DriveStrategyPriority3Req 255 "Not available/Don't care " 254 "Error or reserved" 6 "Enable maximum electric power control" 5 "Enable maximum hydraulic power control" 4 "Enable engine economy control " 3 "Enable minimum engine speed control" 2 "Enable wheel speed/PTO speed ratio control" 1 "Enable constant PTO speed control" 0 "Enable maximum draft power control " ;
VAL_ 2365378048 DriveStrategyPriority2Req 255 "Not available/Don't care " 254 "Error or reserved" 6 "Enable maximum electric power control" 5 "Enable maximum hydraulic power control" 4 "Enable engine economy control " 3 "Enable minimum engine speed control" 2 "Enable wheel speed/PTO speed ratio control" 1 "Enable constant PTO speed control" 0 "Enable maximum draft power control " ;
VAL_ 2365378048 DriveStrategyPriority1Req 255 "Not available/Don't care " 254 "Error or reserved" 6 "Enable maximum electric power control" 5 "Enable maximum hydraulic power control" 4 "Enable engine economy control " 3 "Enable minimum engine speed control" 2 "Enable wheel speed/PTO speed ratio control" 1 "Enable constant PTO speed control" 0 "Enable maximum draft power control " ;
VAL_ 2314732286 SID 255 "nVldPsFxTTItTRng0T250FrVldPstnFx" ;
VAL_ 2314732286 COGReference 3 "Null" 2 "Error" 1 "Magnetic" 0 "True" ;
VAL_ 2566688510 Functionality 14 "Basic Tractor ECU implement set (client) " 13 "Basic Tractor ECU (server) " 12 "Task controller section control working set (client)" 11 "Task controller section control (server) " 10 "Task controller geo working set (client) " 9 "Task controller geo (server) " 8 "Task controller basic working set (client)" 7 "Task controller basic (server) " 6 "Aux-N functions " 5 "Aux-N inputs " 4 "Aux-O functions " 3 "Aux-O inputs " 2 "Universal terminal working set (client) " 1 "Universal terminal (server)" 0 "Minimum control function  " ;
VAL_ 2365468670 Valve15LimitStatus 7 "Not available" 6 "Non-recoverable Fault" 5 "Reserver" 4 "Reserved" 3 "Limited Low" 2 "Limited High" 1 "Operator Limited" 0 "Not limited" ;
VAL_ 2365464574 Valve15ValveState 0 "Blocked" 1 "Extend" 2 "Retract" 3 "Floating" 14 "ErrorIndication" 15 "DoNotCare" ;
VAL_ 2365464574 Valve15FailSafeMode 0 "Block" 1 "Float" 2 "ErrorIndication" 3 "NotAvailable" ;
VAL_ 2365464574 Valve15LimitStatus 7 "Not available" 6 "Non-recoverable Fault" 5 "Reserver" 4 "Reserved" 3 "Limited Low" 2 "Limited High" 1 "Operator Limited" 0 "Not limited" ;
VAL_ 2365472766 Valve15StateCmd 0 "Block" 1 "Extend" 2 "Retract" 3 "Float" 15 "Reserved" ;
VAL_ 2365472766 Valve15FailSaveModeCmd 0 "Block" 1 "Float" 3 "DoNotCare" ;
VAL_ 2365468414 Valve14LimitStatus 7 "Not available" 6 "Non-recoverable Fault" 5 "Reserver" 4 "Reserved" 3 "Limited Low" 2 "Limited High" 1 "Operator Limited" 0 "Not limited" ;
VAL_ 2365464318 Valve14ValveState 0 "Blocked" 1 "Extend" 2 "Retract" 3 "Floating" 14 "ErrorIndication" 15 "DoNotCare" ;
VAL_ 2365464318 Valve14FailSafeMode 0 "Block" 1 "Float" 2 "ErrorIndication" 3 "NotAvailable" ;
VAL_ 2365464318 Valve14LimitStatus 7 "Not available" 6 "Non-recoverable Fault" 5 "Reserver" 4 "Reserved" 3 "Limited Low" 2 "Limited High" 1 "Operator Limited" 0 "Not limited" ;
VAL_ 2365472510 Valve14StateCmd 0 "Block" 1 "Extend" 2 "Retract" 3 "Float" 15 "Reserved" ;
VAL_ 2365472510 Valve14FailSaveModeCmd 0 "Block" 1 "Float" 3 "DoNotCare" ;
VAL_ 2365468158 Valve13LimitStatus 7 "Not available" 6 "Non-recoverable Fault" 5 "Reserver" 4 "Reserved" 3 "Limited Low" 2 "Limited High" 1 "Operator Limited" 0 "Not limited" ;
VAL_ 2365464062 Valve13ValveState 0 "Blocked" 1 "Extend" 2 "Retract" 3 "Floating" 14 "ErrorIndication" 15 "DoNotCare" ;
VAL_ 2365464062 Valve13FailSafeMode 0 "Block" 1 "Float" 2 "ErrorIndication" 3 "NotAvailable" ;
VAL_ 2365464062 Valve13LimitStatus 7 "Not available" 6 "Non-recoverable Fault" 5 "Reserver" 4 "Reserved" 3 "Limited Low" 2 "Limited High" 1 "Operator Limited" 0 "Not limited" ;
VAL_ 2365472254 Valve13StateCmd 0 "Block" 1 "Extend" 2 "Retract" 3 "Float" 15 "Reserved" ;
VAL_ 2365472254 Valve13FailSaveModeCmd 0 "Block" 1 "Float" 3 "DoNotCare" ;
VAL_ 2365467902 Valve12LimitStatus 7 "Not available" 6 "Non-recoverable Fault" 5 "Reserver" 4 "Reserved" 3 "Limited Low" 2 "Limited High" 1 "Operator Limited" 0 "Not limited" ;
VAL_ 2365463806 Valve12ValveState 0 "Blocked" 1 "Extend" 2 "Retract" 3 "Floating" 14 "ErrorIndication" 15 "DoNotCare" ;
VAL_ 2365463806 Valve12FailSafeMode 0 "Block" 1 "Float" 2 "ErrorIndication" 3 "NotAvailable" ;
VAL_ 2365463806 Valve12LimitStatus 7 "Not available" 6 "Non-recoverable Fault" 5 "Reserver" 4 "Reserved" 3 "Limited Low" 2 "Limited High" 1 "Operator Limited" 0 "Not limited" ;
VAL_ 2365471998 Valve12StateCmd 0 "Block" 1 "Extend" 2 "Retract" 3 "Float" 15 "Reserved" ;
VAL_ 2365471998 Valve12FailSaveModeCmd 0 "Block" 1 "Float" 3 "DoNotCare" ;
VAL_ 2365467646 Valve11LimitStatus 7 "Not available" 6 "Non-recoverable Fault" 5 "Reserver" 4 "Reserved" 3 "Limited Low" 2 "Limited High" 1 "Operator Limited" 0 "Not limited" ;
VAL_ 2365463550 Valve11ValveState 0 "Blocked" 1 "Extend" 2 "Retract" 3 "Floating" 14 "ErrorIndication" 15 "DoNotCare" ;
VAL_ 2365463550 Valve11FailSafeMode 0 "Block" 1 "Float" 2 "ErrorIndication" 3 "NotAvailable" ;
VAL_ 2365463550 Valve11LimitStatus 7 "Not available" 6 "Non-recoverable Fault" 5 "Reserver" 4 "Reserved" 3 "Limited Low" 2 "Limited High" 1 "Operator Limited" 0 "Not limited" ;
VAL_ 2365471742 Valve11StateCmd 0 "Block" 1 "Extend" 2 "Retract" 3 "Float" 15 "Reserved" ;
VAL_ 2365471742 Valve11FailSaveModeCmd 0 "Block" 1 "Float" 3 "DoNotCare" ;
VAL_ 2365467390 Valve10LimitStatus 7 "Not available" 6 "Non-recoverable Fault" 5 "Reserver" 4 "Reserved" 3 "Limited Low" 2 "Limited High" 1 "Operator Limited" 0 "Not limited" ;
VAL_ 2365463294 Valve10ValveState 0 "Blocked" 1 "Extend" 2 "Retract" 3 "Floating" 14 "ErrorIndication" 15 "DoNotCare" ;
VAL_ 2365463294 Valve10FailSafeMode 0 "Block" 1 "Float" 2 "ErrorIndication" 3 "NotAvailable" ;
VAL_ 2365463294 Valve10LimitStatus 7 "Not available" 6 "Non-recoverable Fault" 5 "Reserver" 4 "Reserved" 3 "Limited Low" 2 "Limited High" 1 "Operator Limited" 0 "Not limited" ;
VAL_ 2365471486 Valve10StateCmd 0 "Block" 1 "Extend" 2 "Retract" 3 "Float" 15 "Reserved" ;
VAL_ 2365471486 Valve10FailSaveModeCmd 0 "Block" 1 "Float" 3 "DoNotCare" ;
VAL_ 2365467134 Valve9LimitStatus 7 "Not available" 6 "Non-recoverable Fault" 5 "Reserver" 4 "Reserved" 3 "Limited Low" 2 "Limited High" 1 "Operator Limited" 0 "Not limited" ;
VAL_ 2365463038 Valve9ValveState 0 "Blocked" 1 "Extend" 2 "Retract" 3 "Floating" 14 "ErrorIndication" 15 "DoNotCare" ;
VAL_ 2365463038 Valve9FailSafeMode 0 "Block" 1 "Float" 2 "ErrorIndication" 3 "NotAvailable" ;
VAL_ 2365463038 Valve9LimitStatus 7 "Not available" 6 "Non-recoverable Fault" 5 "Reserver" 4 "Reserved" 3 "Limited Low" 2 "Limited High" 1 "Operator Limited" 0 "Not limited" ;
VAL_ 2365471230 Valve9StateCmd 0 "Block" 1 "Extend" 2 "Retract" 3 "Float" 15 "Reserved" ;
VAL_ 2365471230 Valve9FailSaveModeCmd 0 "Block" 1 "Float" 3 "DoNotCare" ;
VAL_ 2365466878 Valve8LimitStatus 7 "Not available" 6 "Non-recoverable Fault" 5 "Reserver" 4 "Reserved" 3 "Limited Low" 2 "Limited High" 1 "Operator Limited" 0 "Not limited" ;
VAL_ 2365462782 Valve8ValveState 0 "Blocked" 1 "Extend" 2 "Retract" 3 "Floating" 14 "ErrorIndication" 15 "DoNotCare" ;
VAL_ 2365462782 Valve8FailSafeMode 0 "Block" 1 "Float" 2 "ErrorIndication" 3 "NotAvailable" ;
VAL_ 2365462782 Valve8LimitStatus 7 "Not available" 6 "Non-recoverable Fault" 5 "Reserver" 4 "Reserved" 3 "Limited Low" 2 "Limited High" 1 "Operator Limited" 0 "Not limited" ;
VAL_ 2365470974 Valve8StateCmd 0 "Block" 1 "Extend" 2 "Retract" 3 "Float" 15 "Reserved" ;
VAL_ 2365470974 Valve8FailSaveModeCmd 0 "Block" 1 "Float" 3 "DoNotCare" ;
VAL_ 2365466622 Valve7LimitStatus 7 "Not available" 6 "Non-recoverable Fault" 5 "Reserver" 4 "Reserved" 3 "Limited Low" 2 "Limited High" 1 "Operator Limited" 0 "Not limited" ;
VAL_ 2365462526 Valve7ValveState 0 "Blocked" 1 "Extend" 2 "Retract" 3 "Floating" 14 "ErrorIndication" 15 "DoNotCare" ;
VAL_ 2365462526 Valve7FailSafeMode 0 "Block" 1 "Float" 2 "ErrorIndication" 3 "NotAvailable" ;
VAL_ 2365462526 Valve7LimitStatus 7 "Not available" 6 "Non-recoverable Fault" 5 "Reserver" 4 "Reserved" 3 "Limited Low" 2 "Limited High" 1 "Operator Limited" 0 "Not limited" ;
VAL_ 2365470718 Valve7StateCmd 0 "Block" 1 "Extend" 2 "Retract" 3 "Float" 15 "Reserved" ;
VAL_ 2365470718 Valve7FailSaveModeCmd 0 "Block" 1 "Float" 3 "DoNotCare" ;
VAL_ 2365466366 Valve6LimitStatus 7 "Not available" 6 "Non-recoverable Fault" 5 "Reserver" 4 "Reserved" 3 "Limited Low" 2 "Limited High" 1 "Operator Limited" 0 "Not limited" ;
VAL_ 2365462270 Valve6ValveState 0 "Blocked" 1 "Extend" 2 "Retract" 3 "Floating" 14 "ErrorIndication" 15 "DoNotCare" ;
VAL_ 2365462270 Valve6FailSafeMode 0 "Block" 1 "Float" 2 "ErrorIndication" 3 "NotAvailable" ;
VAL_ 2365462270 Valve6LimitStatus 7 "Not available" 6 "Non-recoverable Fault" 5 "Reserver" 4 "Reserved" 3 "Limited Low" 2 "Limited High" 1 "Operator Limited" 0 "Not limited" ;
VAL_ 2365470462 Valve6StateCmd 0 "Block" 1 "Extend" 2 "Retract" 3 "Float" 15 "Reserved" ;
VAL_ 2365470462 Valve6FailSaveModeCmd 0 "Block" 1 "Float" 3 "DoNotCare" ;
VAL_ 2365466110 Valve5LimitStatus 7 "Not available" 6 "Non-recoverable Fault" 5 "Reserver" 4 "Reserved" 3 "Limited Low" 2 "Limited High" 1 "Operator Limited" 0 "Not limited" ;
VAL_ 2365462014 Valve5ValveState 0 "Blocked" 1 "Extend" 2 "Retract" 3 "Floating" 14 "ErrorIndication" 15 "DoNotCare" ;
VAL_ 2365462014 Valve5FailSafeMode 0 "Block" 1 "Float" 2 "ErrorIndication" 3 "NotAvailable" ;
VAL_ 2365462014 Valve5LimitStatus 7 "Not available" 6 "Non-recoverable Fault" 5 "Reserver" 4 "Reserved" 3 "Limited Low" 2 "Limited High" 1 "Operator Limited" 0 "Not limited" ;
VAL_ 2365470206 Valve5StateCmd 0 "Block" 1 "Extend" 2 "Retract" 3 "Float" 15 "Reserved" ;
VAL_ 2365470206 Valve5FailSaveModeCmd 0 "Block" 1 "Float" 3 "DoNotCare" ;
VAL_ 2365465854 Valve4LimitStatus 7 "Not available" 6 "Non-recoverable Fault" 5 "Reserver" 4 "Reserved" 3 "Limited Low" 2 "Limited High" 1 "Operator Limited" 0 "Not limited" ;
VAL_ 2365461758 Valve4ValveState 0 "Blocked" 1 "Extend" 2 "Retract" 3 "Floating" 14 "ErrorIndication" 15 "DoNotCare" ;
VAL_ 2365461758 Valve4FailSafeMode 0 "Block" 1 "Float" 2 "ErrorIndication" 3 "NotAvailable" ;
VAL_ 2365461758 Valve4LimitStatus 7 "Not available" 6 "Non-recoverable Fault" 5 "Reserver" 4 "Reserved" 3 "Limited Low" 2 "Limited High" 1 "Operator Limited" 0 "Not limited" ;
VAL_ 2365469950 Valve4StateCmd 0 "Block" 1 "Extend" 2 "Retract" 3 "Float" 15 "Reserved" ;
VAL_ 2365469950 Valve4FailSaveModeCmd 0 "Block" 1 "Float" 3 "DoNotCare" ;
VAL_ 2365465598 Valve3LimitStatus 7 "Not available" 6 "Non-recoverable Fault" 5 "Reserver" 4 "Reserved" 3 "Limited Low" 2 "Limited High" 1 "Operator Limited" 0 "Not limited" ;
VAL_ 2365461502 Valve3ValveState 0 "Blocked" 1 "Extend" 2 "Retract" 3 "Floating" 14 "ErrorIndication" 15 "DoNotCare" ;
VAL_ 2365461502 Valve3FailSafeMode 0 "Block" 1 "Float" 2 "ErrorIndication" 3 "NotAvailable" ;
VAL_ 2365461502 Valve3LimitStatus 7 "Not available" 6 "Non-recoverable Fault" 5 "Reserver" 4 "Reserved" 3 "Limited Low" 2 "Limited High" 1 "Operator Limited" 0 "Not limited" ;
VAL_ 2365469694 Valve3StateCmd 0 "Block" 1 "Extend" 2 "Retract" 3 "Float" 15 "Reserved" ;
VAL_ 2365469694 Valve3FailSaveModeCmd 0 "Block" 1 "Float" 3 "DoNotCare" ;
VAL_ 2365465342 Valve2LimitStatus 7 "Not available" 6 "Non-recoverable Fault" 5 "Reserver" 4 "Reserved" 3 "Limited Low" 2 "Limited High" 1 "Operator Limited" 0 "Not limited" ;
VAL_ 2365461246 Valve2ValveState 0 "Blocked" 1 "Extend" 2 "Retract" 3 "Floating" 14 "ErrorIndication" 15 "DoNotCare" ;
VAL_ 2365461246 Valve2FailSafeMode 0 "Block" 1 "Float" 2 "ErrorIndication" 3 "NotAvailable" ;
VAL_ 2365461246 Valve2LimitStatus 7 "Not available" 6 "Non-recoverable Fault" 5 "Reserver" 4 "Reserved" 3 "Limited Low" 2 "Limited High" 1 "Operator Limited" 0 "Not limited" ;
VAL_ 2365469438 Valve2StateCmd 0 "Block" 1 "Extend" 2 "Retract" 3 "Float" 15 "Reserved" ;
VAL_ 2365469438 Valve2FailSaveModeCmd 0 "Block" 1 "Float" 3 "DoNotCare" ;
VAL_ 2365465086 Valve1LimitStatus 7 "Not available" 6 "Non-recoverable Fault" 5 "Reserver" 4 "Reserved" 3 "Limited Low" 2 "Limited High" 1 "Operator Limited" 0 "Not limited" ;
VAL_ 2365460990 Valve1ValveState 0 "Blocked" 1 "Extend" 2 "Retract" 3 "Floating" 14 "ErrorIndication" 15 "DoNotCare" ;
VAL_ 2365460990 Valve1FailSafeMode 0 "Block" 1 "Float" 2 "ErrorIndication" 3 "NotAvailable" ;
VAL_ 2365460990 Valve1LimitStatus 7 "Not available" 6 "Non-recoverable Fault" 5 "Reserver" 4 "Reserved" 3 "Limited Low" 2 "Limited High" 1 "Operator Limited" 0 "Not limited" ;
VAL_ 2365469182 Valve1StateCmd 0 "Block" 1 "Extend" 2 "Retract" 3 "Float" 15 "Reserved" ;
VAL_ 2365469182 Valve1FailSaveModeCmd 0 "Block" 1 "Float" 3 "DoNotCare" ;
VAL_ 2365464830 Valve0LimitStatus 7 "Not available" 6 "Non-recoverable Fault" 5 "Reserver" 4 "Reserved" 3 "Limited Low" 2 "Limited High" 1 "Operator Limited" 0 "Not limited" ;
VAL_ 2365460734 Valve0ValveState 0 "Blocked" 1 "Extend" 2 "Retract" 3 "Floating" 14 "ErrorIndication" 15 "DoNotCare" ;
VAL_ 2365460734 Valve0FailSafeMode 0 "Block" 1 "Float" 2 "ErrorIndication" 3 "NotAvailable" ;
VAL_ 2365460734 Valve0LimitStatus 7 "Not available" 6 "Non-recoverable Fault" 5 "Reserver" 4 "Reserved" 3 "Limited Low" 2 "Limited High" 1 "Operator Limited" 0 "Not limited" ;
VAL_ 2365468926 Valve0StateCmd 0 "Block" 1 "Extend" 2 "Retract" 3 "Float" 15 "Reserved" ;
VAL_ 2365468926 Valve0FailSaveModeCmd 0 "Block" 1 "Float" 3 "DoNotCare" ;
VAL_ 2365391360 StopAllImplementOperations 3 "NotAvailable " 2 "ErrorIndication" 1 "PermitAllImplementsToON " 0 "StopImplementOperations" ;
VAL_ 2297441790 VrtclAcclrtnExRangeFigureOfMerit 3 "not available" 2 "error" 1 "verticalacceleration is degraded Data is suspect due to enviromental conditions" 0 "vertical acceleration is fully functional Data is within sensor specification" ;
VAL_ 2297441790 LngtdnlAcclrtnExRngFigureOfMerit 3 "not available" 2 "error" 1 "longitudinal acceleration is degraded Data is suspect due to enviromental conditions" 0 "longitudinal acceleration is fully functional Data is within sensor specification" ;
VAL_ 2297441790 LtrlAcclrtonExRangeFigureOfMerit 3 "not available" 2 "error" 1 "lateral acceleration is degraded Data is suspect due to enviromental conditions" 0 "lateral acceleration is fully functional Data is within sensor specification" ;
VAL_ 2364549630 RollAngleExRangeFigureOfMerit 3 "Not available" 2 "Error" 1 "Roll rate degraded Data is suspect due to environmental conditions" 0 "Roll rate fully functional Data is within sensor specification" ;
VAL_ 2364549630 RollAngleExRangeCompensation 3 "Not Available" 2 "Error" 1 "Off" 0 "On" ;
VAL_ 2364549630 PitchAngleExRangeFigureOfMerit 3 "Not available" 2 "Error" 1 "Pitch rate degraded Data is suspect due to environmental conditions" 0 "Pitch rate fully functional Data is within sensor specification" ;
VAL_ 2364549630 PitchAngleExRangeCompensation 3 "Not Available" 2 "Error" 1 "Off" 0 "On" ;
VAL_ 2499614462 OccpntClssficationSystem10Status 3 "not available" 2 "Error  Classification cannot be determined" 1 "occupied" 0 "empty" ;
VAL_ 2499614462 OccpntClssificationSystem9Status 3 "not available" 2 "Error  Classification cannot be determined" 1 "occupied" 0 "empty" ;
VAL_ 2499614462 OccpntClssificationSystem8Status 3 "not available" 2 "Error  Classification cannot be determined" 1 "occupied" 0 "empty" ;
VAL_ 2499614462 OccpntClssificationSystem7Status 3 "not available" 2 "Error  Classification cannot be determined" 1 "occupied" 0 "empty" ;
VAL_ 2499614462 OccpntClssificationSystem6Status 3 "not available" 2 "Error  Classification cannot be determined" 1 "occupied" 0 "empty" ;
VAL_ 2499614462 OccpntClssificationSystem5Status 3 "not available" 2 "Error  Classification cannot be determined" 1 "occupied" 0 "empty" ;
VAL_ 2499614462 OccpntClssificationSystem4Status 3 "not available" 2 "Error  Classification cannot be determined" 1 "occupied" 0 "empty" ;
VAL_ 2499614462 OccpntClssificationSystem3Status 3 "not available" 2 "Error  Classification cannot be determined" 1 "occupied" 0 "empty" ;
VAL_ 2499614462 PssngrOccpntClssfctnSystemStatus 3 "adult" 4 "reserved" 2 "small adult" 1 "child" 0 "empty" ;
VAL_ 2499614462 DrvrOccpntClssfctionSystemStatus 7 "not available" 6 "Error  Classification of occupant cannot be determined" 5 "reserved" 4 "large adult" 3 "adult" 2 "small adult" 1 "child" 0 "empty" ;
VAL_ 2560098046 CabNoiseCtrlTuningStatus 12 "Reserved" 11 "Reserved" 6 "Reserved" 5 "Reserved" 4 "Reserved" 3 "Reserved" 15 "Not Available/Not Tuning/Not Requested" 14 "Tuning Mode  Error" 10 "Automatic Tuning Mode  Saving Data" 9 "Automatic Tuning Mode  Command Complete" 8 "Automatic Tuning Mode" 7 "Manual Tuning Denied  Requires Security Verification" 13 "Reserved" 2 "Manual Tuning Mode  Saving Data" 1 "Manual Tuning Mode  Command Complete" 0 "Manual Tuning Mode" ;
VAL_ 2560098046 CabNoiseCtrlStatus 3 "Not Available/Not Requested" 2 "Error Indicator" 1 "Cab Noise Control System OFFLine" 0 "Cab Noise Control System ONLine" ;
VAL_ 2560163582 CabNoiseCtrlTuningState 7 "Dont Care NOT Commanded" 6 "Reserved" 5 "Exit Tuning Saving Parameters" 4 "Exit Tuning Not Saving Parameters" 3 "Remain In Tuning Save Current Parameters" 2 "Activate Automatic Tuning State Saveing Parameters Exit on Completion" 1 "Activate Automatic Tuning Wait for Save and Exit Commands" 0 "Activate Manual Tuning Wait for Save and Exit Commands" ;
VAL_ 2560163582 CabNoiseCtrlState 3 "Dont Care/Not Commanded" 2 "Reserved" 1 "Bring Cab Noise Control System On Line" 0 "Take Cab Noise Control System Off Line" ;
VAL_ 2297441534 DropRelayCtrl 3 "Take No Action" 2 "Reserved" 1 "On Enable Drop Relay Request" 0 "Off Disable Drop Relay Request" ;
VAL_ 2297441534 LiftRelayCtrl 3 "Take No Action" 2 "Reserved" 1 "On Enable Lift Relay Request" 0 "Off Disable Lift Relay Request" ;
VAL_ 2297441534 MaterialDropActiveStatus 3 "Not Available" 2 "Error" 1 "On" 0 "Off" ;
VAL_ 2297441534 MaterialLiftActiveStatus 3 "Not Available" 2 "Error" 1 "On" 0 "Off" ;
VAL_ 2297441534 GneratorCurrentBoostActiveStatus 3 "Not Available" 2 "Error" 1 "On" 0 "Off" ;
VAL_ 2297441534 MaterialDropSwitch 3 "Not Available" 2 "Error" 1 "Drop" 0 "Dont Drop" ;
VAL_ 2297441534 MaterialLiftSwitch 3 "Not Available" 2 "Error" 1 "Lift" 0 "Dont Lift" ;
VAL_ 2566722302 GeneratorDutyCycleExceededStatus 3 "Not Avaiable" 2 "Error" 1 "Duty Cycle Exceed" 0 "Duty Cycle Not Exceed" ;
VAL_ 2566722302 VoltageMonitorActiveStatus 3 "Not Available" 2 "Error" 1 "Monitor is On" 0 "Monitor is Off" ;
VAL_ 2566722302 GensetEnableActiveStatus 3 "Not Avaialble" 2 "Error" 1 "Enabled" 0 "Not Enabled" ;
VAL_ 2566722302 ReverseCurrentRangeSetting 31 "Not Available" 30 "Error" 15 "16" 14 "15" 13 "14" 12 "13" 11 "12" 10 "11" 9 "10" 8 "9" 7 "8" 6 "7" 5 "6" 4 "5" 3 "4" 2 "3" 1 "2" 0 "1" ;
VAL_ 2566722302 GensetSoftstartActiveStatus 3 "Not Available" 2 "Error" 1 "On" 0 "Off" ;
VAL_ 2566722302 Grapple_MagnetSelectionSwitch 3 "Not Available" 2 "Error" 1 "Magnet Selected" 0 "Grapple Selected" ;
VAL_ 2566722302 GnstSystmOtputVoltageRangeStatus 3 "Not Available" 2 "Error" 1 "In Range" 0 "Out of Range" ;
VAL_ 2566722302 GeneratorOverheatStatus 3 "Not Available" 2 "Error" 1 "Overheat" 0 "Not Overheat" ;
VAL_ 2560032510 LwVltgDscnnctDsiredOperatingMode 15 "No change" 5 "Manual Connect" 4 "Manual Disconnect" 0 "Automatic" ;
VAL_ 2566717950 LwVltgeDisconnectVoutOutputState 15 "Not available or not installed" 14 "Output fault" 4 "Connect pending alarm active" 3 "Disconnect pending alarm active" 2 "Disconnect alarm expired output off or disconnected" 1 "Output on or connected" 0 "Output off or disconnected" ;
VAL_ 2566717950 LowVoltageDisconnectOutput1State 15 "Not available or not installed" 14 "Output fault" 4 "Connect pending alarm active" 3 "Disconnect pending alarm active" 2 "Disconnect alarm expired output off or disconnected" 1 "Output on or connected" 0 "Output off or disconnected" ;
VAL_ 2566717950 LowVoltageDisconnectOutput2State 15 "Not available or not installed" 14 "Output fault" 4 "Connect pending alarm active" 3 "Disconnect pending alarm active" 2 "Disconnect alarm expired output off or disconnected" 1 "Output on or connected" 0 "Output off or disconnected" ;
VAL_ 2566717950 LowVoltageDisconnectOutput3State 15 "Not available or not installed" 14 "Output fault" 4 "Connect pending alarm active" 3 "Disconnect pending alarm active" 2 "Disconnect alarm expired output off or disconnected" 1 "Output on or connected" 0 "Output off or disconnected" ;
VAL_ 2566717950 LwVltgDscnnctCrrentOperatingMode 15 "Not available" 9 "Manual Connect via hardwired input" 8 "Manual Disconnect via hardwired input" 5 "Manual Connect via J1939 request" 4 "Manual Disconnect via J1939 request" 0 "Automatic" ;
VAL_ 2566717950 LwVltgDscnnectManualConnectState 3 "Not installed" 2 "Error" 1 "Input on" 0 "Input off" ;
VAL_ 2566717950 LwVltgDscnnctMnalDisconnectState 3 "Not installed" 2 "Error" 1 "Input on" 0 "Input off" ;
VAL_ 2358902526 Joystick3Lamp10Cmd 3 "Not available or not installed" 2 "Blinking" 1 "On" 0 "Off" ;
VAL_ 2358902526 Joystick3Lamp9Cmd 3 "Not available or not installed" 2 "Blinking" 1 "On" 0 "Off" ;
VAL_ 2358902526 Joystick3Lamp8Cmd 3 "Not available or not installed" 2 "Blinking" 1 "On" 0 "Off" ;
VAL_ 2358902526 Joystick3Lamp7Cmd 3 "Not available or not installed" 2 "Blinking" 1 "On" 0 "Off" ;
VAL_ 2358902526 Joystick3Lamp6Cmd 3 "Not available or not installed" 2 "Blinking" 1 "On" 0 "Off" ;
VAL_ 2358902526 Joystick3Lamp5Cmd 3 "Not available or not installed" 2 "Blinking" 1 "On" 0 "Off" ;
VAL_ 2358902526 Joystick3Lamp4Cmd 3 "Not available or not installed" 2 "Blinking" 1 "On" 0 "Off" ;
VAL_ 2358902526 Joystick3Lamp3Cmd 3 "Not available or not installed" 2 "Blinking" 1 "On" 0 "Off" ;
VAL_ 2358902526 Joystick3Lamp2Cmd 3 "Not available or not installed" 2 "Blinking" 1 "On" 0 "Off" ;
VAL_ 2358902526 Joystick3Lamp1Cmd 3 "Not available or not installed" 2 "Blinking" 1 "On" 0 "Off" ;
VAL_ 2358902526 Joystick2Lamp10Cmd 3 "Not available or not installed" 2 "Blinking" 1 "On" 0 "Off" ;
VAL_ 2358902526 Joystick2Lamp9Cmd 3 "Not available or not installed" 2 "Blinking" 1 "On" 0 "Off" ;
VAL_ 2358902526 Joystick2Lamp8Cmd 3 "Not available or not installed" 2 "Blinking" 1 "On" 0 "Off" ;
VAL_ 2358902526 Joystick2Lamp7Cmd 3 "Not available or not installed" 2 "Blinking" 1 "On" 0 "Off" ;
VAL_ 2358902526 Joystick2Lamp6Cmd 3 "Not available or not installed" 2 "Blinking" 1 "On" 0 "Off" ;
VAL_ 2358902526 Joystick2Lamp5Cmd 3 "Not available or not installed" 2 "Blinking" 1 "On" 0 "Off" ;
VAL_ 2358902526 Joystick2Lamp4Cmd 3 "Not available or not installed" 2 "Blinking" 1 "On" 0 "Off" ;
VAL_ 2358902526 Joystick2Lamp3Cmd 3 "Not available or not installed" 2 "Blinking" 1 "On" 0 "Off" ;
VAL_ 2358902526 Joystick2Lamp2Cmd 3 "Not available or not installed" 2 "Blinking" 1 "On" 0 "Off" ;
VAL_ 2358902526 Joystick2Lamp1Cmd 3 "Not available or not installed" 2 "Blinking" 1 "On" 0 "Off" ;
VAL_ 2358902526 Joystick1Lamp10Cmd 3 "Not available or not installed" 2 "Blinking" 1 "On" 0 "Off" ;
VAL_ 2358902526 Joystick1Lamp9Cmd 3 "Not available or not installed" 2 "Blinking" 1 "On" 0 "Off" ;
VAL_ 2358902526 Joystick1Lamp8Cmd 3 "Not available or not installed" 2 "Blinking" 1 "On" 0 "Off" ;
VAL_ 2358902526 Joystick1Lamp7Cmd 3 "Not available or not installed" 2 "Blinking" 1 "On" 0 "Off" ;
VAL_ 2358902526 Joystick1Lamp6Cmd 3 "Not available or not installed" 2 "Blinking" 1 "On" 0 "Off" ;
VAL_ 2358902526 Joystick1Lamp5Cmd 3 "Not available or not installed" 2 "Blinking" 1 "On" 0 "Off" ;
VAL_ 2358902526 Joystick1Lamp4Cmd 3 "Not available or not installed" 2 "Blinking" 1 "On" 0 "Off" ;
VAL_ 2358902526 Joystick1Lamp3Cmd 3 "Not available or not installed" 2 "Blinking" 1 "On" 0 "Off" ;
VAL_ 2358902526 Joystick1Lamp2Cmd 3 "Not available or not installed" 2 "Blinking" 1 "On" 0 "Off" ;
VAL_ 2358902526 Joystick1Lamp1Cmd 3 "Not available or not installed" 2 "Blinking" 1 "On" 0 "Off" ;
VAL_ 2566711550 IntkVlvActtnSystmOlPrss2SlndCtrl 3 "not available" 2 "reserved for SAE assignment" 1 "on" 0 "off" ;
VAL_ 2566711550 IntkVlvActtnSystmOlPrss1SlndCtrl 3 "not available" 2 "reserved for SAE assignment" 1 "on" 0 "off" ;
VAL_ 2566713854 EngTrbWstgtActtr2OperationStatus 14 "Error" 6 "1101ReservedForFutureAssignment" 5 "UnCtrlledShutdownActive" 4 "CtrlledShutdownActive" 3 "DerateActive" 2 "AlarmHighSeverity" 1 "Alarm" 0 "Normal" ;
VAL_ 2566713854 EngTrbWstgtActtr1OperationStatus 14 "Error" 6 "1101ReservedForFutureAssignment" 5 "UnCtrlledShutdownActive" 4 "CtrlledShutdownActive" 3 "DerateActive" 2 "AlarmHighSeverity" 1 "Alarm" 0 "Normal" ;
VAL_ 2566713854 EngTrbWstgateActuator2TempStatus 7 "Not available" 6 "Error" 5 "Not Defined" 4 "Low Most severe" 3 "Low Least severe" 2 "In Range" 1 "High Least severe" 0 "High most severe" ;
VAL_ 2566714366 EngTrbCmprssrBypssActtr2OprtnStt 14 "Error" 6 "1101ReservedForFutureAssignment" 5 "UnCtrlledShutdownActive" 4 "CtrlledShutdownActive" 3 "DerateActive" 2 "AlarmHighSeverity" 1 "Alarm" 0 "Normal" ;
VAL_ 2566714366 EngTrbCmprssrBypssActtr1OprtnStt 14 "Error" 6 "1101ReservedForFutureAssignment" 5 "UnCtrlledShutdownActive" 4 "CtrlledShutdownActive" 3 "DerateActive" 2 "AlarmHighSeverity" 1 "Alarm" 0 "Normal" ;
VAL_ 2566714366 EngTrbCmprssrBypssActtr2TmpSttus 7 "Not available" 6 "Error" 5 "Not Defined" 4 "Low Most severe" 3 "Low Least severe" 2 "In Range" 1 "High Least severe" 0 "High most severe" ;
